VERSION ""

NS_ :

BS_:

BU_: PowertrainControlModule AtmosphericSensor SafetyRestraintSystem2 Aftertreatment_2_GasOutlet Aftertreatment_2_GasIntake DieselParticulateFilterControl Turbocharger SafetyRestraintSystem1 CabDisplay2 Aftertreatment_1_GasOutlet Aftertreatment_1_GasIntake OnBoardDataLogger OffBoardDiagnosticTool2 OffBoardDiagnosticTool1 FileServer ParkingBrakeController SeatController2 FanDriveController SteeringColumnUnit CommunicationUnitRadio CommunicationUnitSatellite CommunicationUnitCellular PropulsionBatteryCharger ChassisController2 ChassisController1 EngineValveControl AuxiliaryHeater2 AuxiliaryHeater1 ClutchUnit RampControl InformationSystem1 SuspensionSystemController2 OilSensor VehicleDynamicStability ExhaustEmissionController TransmissionDisplay2 TransmissionDisplay1 ClimateControl2 WaterPumpController RearAxleSteeringController LightingOperatorControl SeatController1 IgnitionController2 IgnitionController1 TirePressureController CabController2 CabController1 PneumaticSystemController SuspensionSystemController1 HydraulicPumpController EnduranceBrakingSystem RetarderExhaustEngine2 OnBoardDiagnosticUnit HeadwayController RetarderExhaustEngine1 CabDisplay1 ManagementComputer VirtualTerminal OffVehicleGateway PowerTakeOffFront HitchControl AuxiliaryValveControl BodyController TractorTrailerBridge1 StarterSystem ElectricalSystem VehicleSecurity VehicleNavigation AerodynamicControl ElectricalChargingSystem ClimateControl1 TripRecorder InstrumentCluster SuspensionDriveAxle2 SuspensionDriveAxle1 SuspensionSteerAxle SteeringController FuelSystem CruiseControl RetarderDriveline RetarderEngine BrakesDriveAxle2 BrakesDriveAxle1 BrakesSystemController BrakesSteerAxle AxleDrive2 AxleDrive1 AxleSteering PowerTakeOff ShiftConsoleSecondary ShiftConsolePrimary Transmission2 Transmission1 Engine2 Engine1

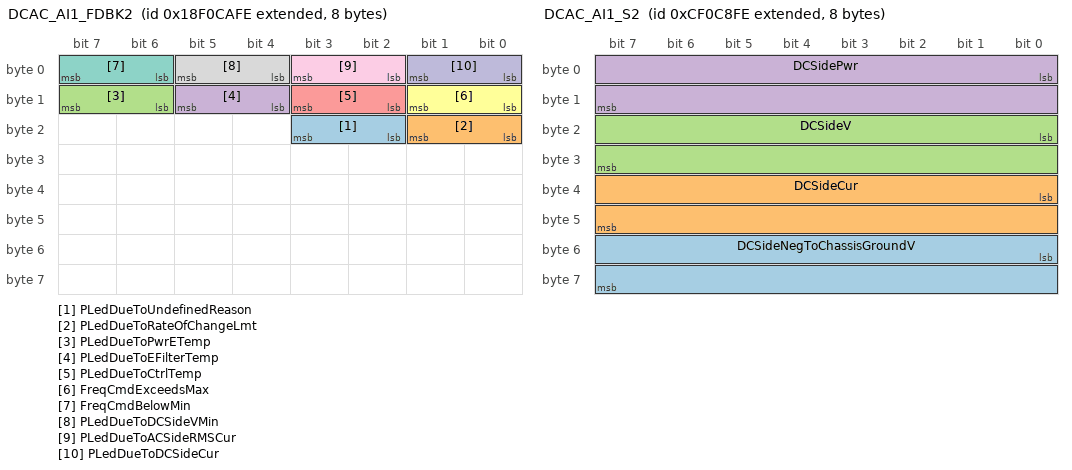
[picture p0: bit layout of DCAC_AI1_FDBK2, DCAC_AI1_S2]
BO_ 2565917438 DCAC_AI1_FDBK2: 8 Vector__XXX
 SG_ PLedDueToUndefinedReason : 18|2@1+ (1,0) [0|3] "" Vector__XXX
 SG_ PLedDueToRateOfChangeLmt : 16|2@1+ (1,0) [0|3] "" Vector__XXX
 SG_ PLedDueToPwrETemp : 14|2@1+ (1,0) [0|3] "" Vector__XXX
 SG_ PLedDueToEFilterTemp : 12|2@1+ (1,0) [0|3] "" Vector__XXX
 SG_ PLedDueToCtrlTemp : 10|2@1+ (1,0) [0|3] "" Vector__XXX
 SG_ FreqCmdExceedsMax : 8|2@1+ (1,0) [0|3] "" Vector__XXX
 SG_ FreqCmdBelowMin : 6|2@1+ (1,0) [0|3] "" Vector__XXX
 SG_ PLedDueToDCSideVMin : 4|2@1+ (1,0) [0|3] "" Vector__XXX
 SG_ PLedDueToACSideRMSCur : 2|2@1+ (1,0) [0|3] "" Vector__XXX
 SG_ PLedDueToDCSideCur : 0|2@1+ (1,0) [0|3] "" Vector__XXX

BO_ 2364590590 DCAC_AI1_V: 8 Vector__XXX
 SG_ SLIV : 16|16@1+ (0.05,0) [0|3212.75] "V" Vector__XXX
 SG_ IgntV : 0|16@1+ (0.05,0) [0|3212.75] "V" Vector__XXX

BO_ 2364590334 DCAC_AI1_S2: 8 Vector__XXX
 SG_ DCSideNegToChassisGroundV : 48|16@1+ (0.05,0) [0|3212.75] "V" Vector__XXX
 SG_ DCSideCur : 32|16@1+ (0.0625,0) [0|4015.9375] "A" Vector__XXX
 SG_ DCSideV : 16|16@1+ (0.05,0) [0|3212.75] "V" Vector__XXX
 SG_ DCSidePwr : 0|16@1+ (0.0625,0) [0|4015.9375] "kW" Vector__XXX

BO_ 2624519934 CRSC: 8 Vector__XXX
 SG_ CommandedReceiveSPNSA : 40|8@1+ (1,0) [0|255] "" Vector__XXX
 SG_ CommandedReceiveSPNReqSt : 32|2@1+ (1,0) [0|3] "" Vector__XXX
 SG_ CommandedReceiveSPN : 16|19@1+ (1,0) [0|524287] "" Vector__XXX
 SG_ TransactionMode : 4|4@1+ (1,0) [0|15] "" Vector__XXX
 SG_ CommandedPort : 0|4@1+ (1,0) [0|15] "" Vector__XXX

BO_ 2557345534 WSPT1: 19 Vector__XXX
 SG_ PlungerFiringOrder : 144|4@1+ (1,0) [0|15] "" Vector__XXX
 SG_ RodLoadHiThreshold : 128|16@1+ (5,0) [0|321275] "kN" Vector__XXX
 SG_ CrankshaftSpdHiThreshold : 112|16@1+ (0.125,0) [0|8031.875] "rpm" Vector__XXX
 SG_ CrankshaftSpdLowThreshold : 96|16@1+ (0.125,0) [0|8031.875] "rpm" Vector__XXX
 SG_ DisPressHiThreshold : 80|16@1+ (5,0) [0|321275] "kPa" Vector__XXX
 SG_ SuctionPressHiThreshold : 64|16@1+ (0.1,-3212.7) [-3212.7|3212.8] "kPa" Vector__XXX
 SG_ SuctionPressLowThreshold : 48|16@1+ (0.1,-3212.7) [-3212.7|3212.8] "kPa" Vector__XXX
 SG_ GearBoxOilTempHiThreshold : 40|8@1+ (1,-40) [-40|210] "°C" Vector__XXX
 SG_ GearBoxOilTempLowThreshold : 32|8@1+ (1,-40) [-40|210] "°C" Vector__XXX
 SG_ GearBoxOilPressHiThreshold : 16|16@1+ (0.1,0) [0|6425.5] "kPa" Vector__XXX
 SG_ GearBoxOilPressLowThreshold : 0|16@1+ (0.1,0) [0|6425.5] "kPa" Vector__XXX

BO_ 2557214462 WSPSCC: 8 Vector__XXX
 SG_ DisPressCalSetPointCmd : 8|4@1+ (1,0) [0|15] "" Vector__XXX
 SG_ SuctionPressCalSetPointCmd : 0|4@1+ (1,0) [0|15] "" Vector__XXX

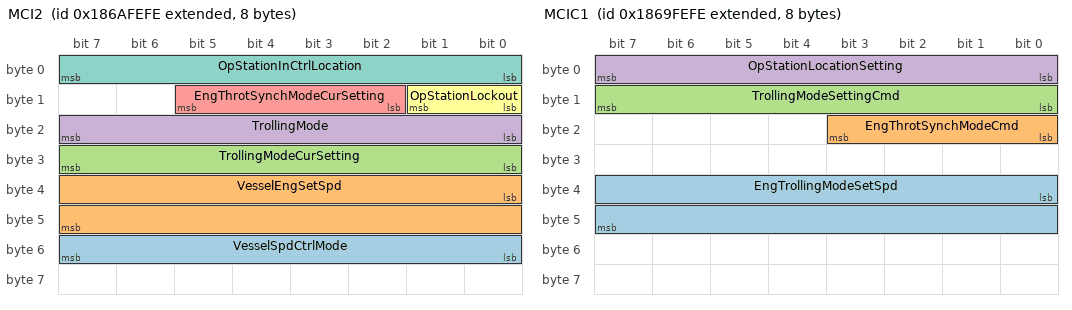
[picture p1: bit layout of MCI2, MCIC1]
BO_ 2557148926 MCI2: 8 Vector__XXX
 SG_ VesselSpdCtrlMode : 48|8@1+ (1,0) [0|255] "" Vector__XXX
 SG_ VesselEngSetSpd : 32|16@1+ (0.125,0) [0|8031.875] "rpm" Vector__XXX
 SG_ TrollingModeCurSetting : 24|8@1+ (1,0) [0|255] "" Vector__XXX
 SG_ TrollingMode : 16|8@1+ (1,0) [0|255] "" Vector__XXX
 SG_ EngThrotSynchModeCurSetting : 10|4@1+ (1,0) [0|15] "" Vector__XXX
 SG_ OpStationLockout : 8|2@1+ (1,0) [0|3] "" Vector__XXX
 SG_ OpStationInCtrlLocation : 0|8@1+ (1,0) [0|250] "ID" Vector__XXX

BO_ 2557083390 MCIC1: 8 Vector__XXX
 SG_ EngTrollingModeSetSpd : 32|16@1+ (0.125,0) [0|8031.875] "rpm" Vector__XXX
 SG_ EngThrotSynchModeCmd : 16|4@1+ (1,0) [0|15] "" Vector__XXX
 SG_ TrollingModeSettingCmd : 8|8@1+ (1,0) [0|255] "" Vector__XXX
 SG_ OpStationLocationSetting : 0|8@1+ (1,0) [0|250] "ID" Vector__XXX

BO_ 2633785086 HVESSHIST: 19 Vector__XXX
 SG_ TotalEnergyOut : 120|32@1+ (1,0) [0|4211081215] "kWh" Vector__XXX
 SG_ TotalEnergyInput : 88|32@1+ (1,0) [0|4211081215] "kWh" Vector__XXX
 SG_ TotalAccumulatedCharge : 56|32@1+ (100,0) [0|421108121500] "Ah" Vector__XXX
 SG_ TotalEnergyThroughput : 24|32@1+ (100,0) [0|421108121500] "Wh" Vector__XXX
 SG_ ContactorOpenUnderLoadCount : 8|16@1+ (1,0) [0|64255] "" Vector__XXX
 SG_ StOfHealth : 0|8@1+ (0.4,0) [0|100] "%" Vector__XXX

BO_ 2566675966 HVESSCFG: 20 Vector__XXX
 SG_ NomRatedCapacity : 136|24@1+ (0.001,0) [0|16449.535] "kWh" Vector__XXX
 SG_ NumOfHVESPsConfigured : 128|8@1+ (1,0) [0|250] "" Vector__XXX
 SG_ CellMinVLmt : 120|8@1+ (0.02044,0) [0|5.11] "V" Vector__XXX
 SG_ CellMaxVLmt : 112|8@1+ (0.02044,0) [0|5.11] "V" Vector__XXX
 SG_ RecommendedMinOperatingTemp : 96|16@1+ (0.03125,-273) [-273|1734.96875] "°C" Vector__XXX
 SG_ RecommendedMaxOperatingTemp : 80|16@1+ (0.03125,-273) [-273|1734.96875] "°C" Vector__XXX
 SG_ RecommendedMaxStOfCharge : 64|16@1+ (0.0015625,0) [0|100.3984375] "%" Vector__XXX
 SG_ RecommendedMinStOfCharge : 48|16@1+ (0.0015625,0) [0|100.3984375] "%" Vector__XXX
 SG_ RecommendedMaxOperatingV : 32|16@1+ (0.05,0) [0|3212.75] "V" Vector__XXX
 SG_ RecommendedMinOperatingV : 16|16@1+ (0.05,0) [0|3212.75] "V" Vector__XXX
 SG_ NominalV : 0|16@1+ (0.05,0) [0|3212.75] "V" Vector__XXX

BO_ 2566661886 A2DEFI2: 8 Vector__XXX
 SG_ Ctrl2Temp : 8|8@1+ (1,-40) [-40|210] "°C" Vector__XXX
 SG_ CtrlTemp : 0|8@1+ (1,-40) [-40|210] "°C" Vector__XXX

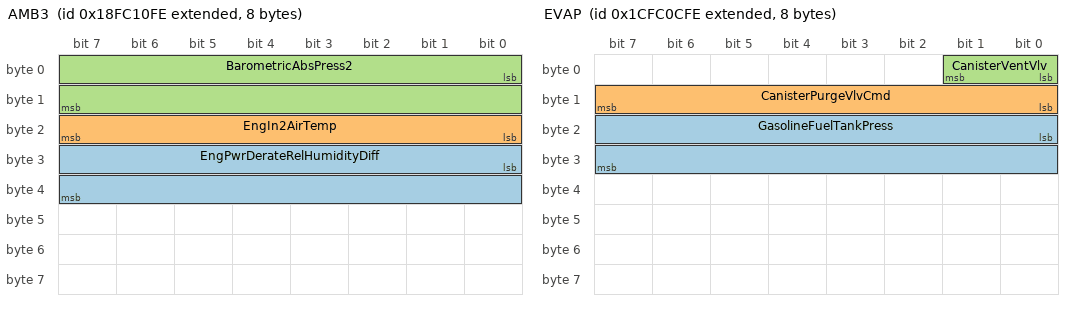
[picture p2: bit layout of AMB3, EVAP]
BO_ 2566656254 AMB3: 8 Vector__XXX
 SG_ EngPwrDerateRelHumidityDiff : 24|16@1+ (0.01,-321.27) [-100|100] "%" Vector__XXX
 SG_ EngIn2AirTemp : 16|8@1+ (1,-40) [-40|210] "°C" Vector__XXX
 SG_ BarometricAbsPress2 : 0|16@1+ (0.1,0) [0|6425.5] "kPa" Vector__XXX

BO_ 2566655998 SHRPS: 8 Vector__XXX
 SG_ PitchSensitivity : 8|8@1+ (0.4,0) [0|100] "%" Vector__XXX
 SG_ Sensitivity : 0|8@1+ (0.4,0) [0|100] "%" Vector__XXX

BO_ 2566655742 PHRPS: 8 Vector__XXX
 SG_ PitchSensitivity : 8|8@1+ (0.4,0) [0|100] "%" Vector__XXX
 SG_ Sensitivity : 0|8@1+ (0.4,0) [0|100] "%" Vector__XXX

BO_ 2633764350 FPS1: 8 Vector__XXX
 SG_ EngagementCycles : 32|16@1+ (1,0) [0|64255] "" Vector__XXX
 SG_ OpTime : 0|32@1+ (1,0) [0|4211081215] "s" Vector__XXX

BO_ 2633764094 EVAP: 8 Vector__XXX
 SG_ GasolineFuelTankPress : 16|16@1+ (0.1,-3212.7) [-3212.7|3212.8] "kPa" Vector__XXX
 SG_ CanisterPurgeVlvCmd : 8|8@1+ (0.4,0) [0|100] "%" Vector__XXX
 SG_ CanisterVentVlv : 0|2@1+ (1,0) [0|3] "" Vector__XXX

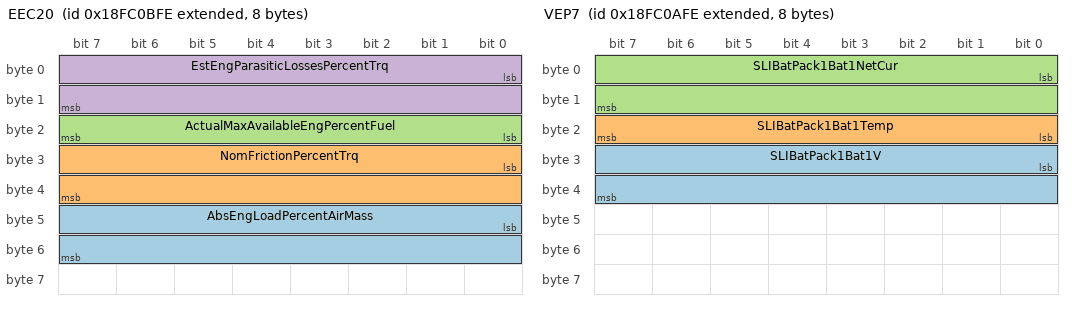
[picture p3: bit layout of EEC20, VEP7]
BO_ 2566654974 EEC20: 8 Vector__XXX
 SG_ AbsEngLoadPercentAirMass : 40|16@1+ (0.025,0) [0|1606.375] "%" Vector__XXX
 SG_ NomFrictionPercentTrq : 24|16@1+ (0.0015625,0) [0|100.3984375] "%" Vector__XXX
 SG_ ActualMaxAvailableEngPercentFuel : 16|8@1+ (0.4,0) [0|100] "%" Vector__XXX
 SG_ EstEngParasiticLossesPercentTrq : 0|16@1+ (0.0015625,0) [0|100.3984375] "%" Vector__XXX

BO_ 2566654718 VEP7: 8 Vector__XXX
 SG_ SLIBatPack1Bat1V : 24|16@1+ (0.05,0) [0|3212.75] "V" Vector__XXX
 SG_ SLIBatPack1Bat1Temp : 16|8@1+ (1,-40) [-40|210] "°C" Vector__XXX
 SG_ SLIBatPack1Bat1NetCur : 0|16@1+ (0.05,-1600) [-1600|1612.75] "A" Vector__XXX

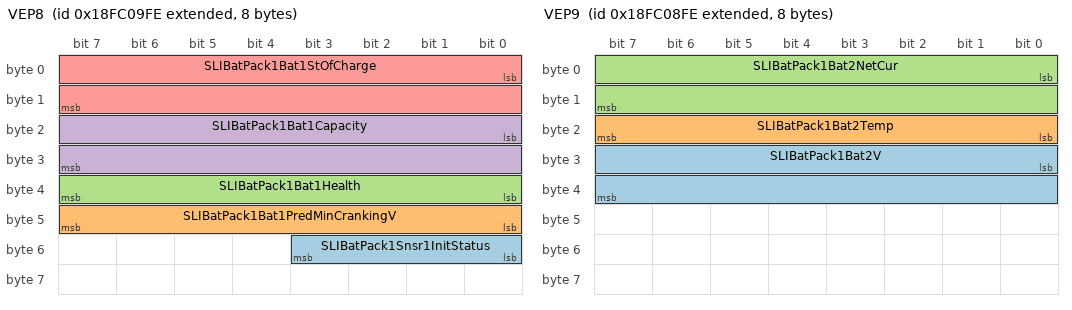
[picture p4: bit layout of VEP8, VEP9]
BO_ 2566654462 VEP8: 8 Vector__XXX
 SG_ SLIBatPack1Snsr1InitStatus : 48|4@1+ (1,0) [0|15] "" Vector__XXX
 SG_ SLIBatPack1Bat1PredMinCrankingV : 40|8@1+ (0.2,0) [0|50] "V" Vector__XXX
 SG_ SLIBatPack1Bat1Health : 32|8@1+ (0.5,0) [0|125] "%" Vector__XXX
 SG_ SLIBatPack1Bat1Capacity : 16|16@1+ (1,0) [0|64255] "Ah" Vector__XXX
 SG_ SLIBatPack1Bat1StOfCharge : 0|16@1+ (0.0025,0) [0|160.6375] "%" Vector__XXX

BO_ 2566654206 VEP9: 8 Vector__XXX
 SG_ SLIBatPack1Bat2V : 24|16@1+ (0.05,0) [0|3212.75] "V" Vector__XXX
 SG_ SLIBatPack1Bat2Temp : 16|8@1+ (1,-40) [-40|210] "°C" Vector__XXX
 SG_ SLIBatPack1Bat2NetCur : 0|16@1+ (0.05,-1600) [-1600|1612.75] "A" Vector__XXX

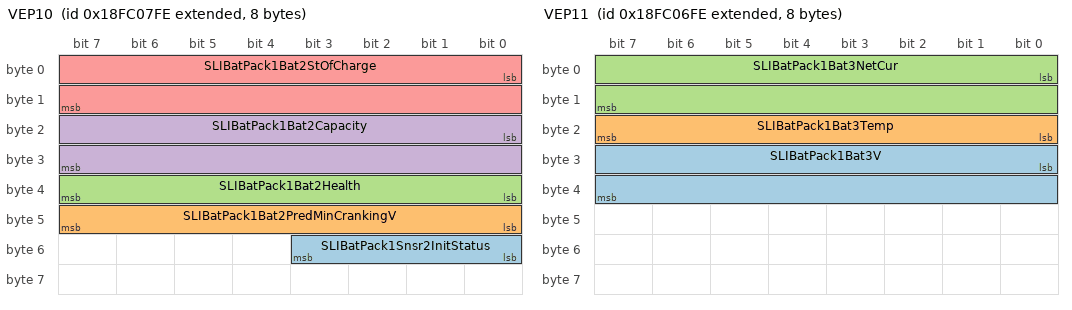
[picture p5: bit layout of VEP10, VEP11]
BO_ 2566653950 VEP10: 8 Vector__XXX
 SG_ SLIBatPack1Snsr2InitStatus : 48|4@1+ (1,0) [0|15] "" Vector__XXX
 SG_ SLIBatPack1Bat2PredMinCrankingV : 40|8@1+ (0.2,0) [0|50] "V" Vector__XXX
 SG_ SLIBatPack1Bat2Health : 32|8@1+ (0.5,0) [0|125] "%" Vector__XXX
 SG_ SLIBatPack1Bat2Capacity : 16|16@1+ (1,0) [0|64255] "Ah" Vector__XXX
 SG_ SLIBatPack1Bat2StOfCharge : 0|16@1+ (0.0025,0) [0|160.6375] "%" Vector__XXX

BO_ 2566653694 VEP11: 8 Vector__XXX
 SG_ SLIBatPack1Bat3V : 24|16@1+ (0.05,0) [0|3212.75] "V" Vector__XXX
 SG_ SLIBatPack1Bat3Temp : 16|8@1+ (1,-40) [-40|210] "°C" Vector__XXX
 SG_ SLIBatPack1Bat3NetCur : 0|16@1+ (0.05,-1600) [-1600|1612.75] "A" Vector__XXX

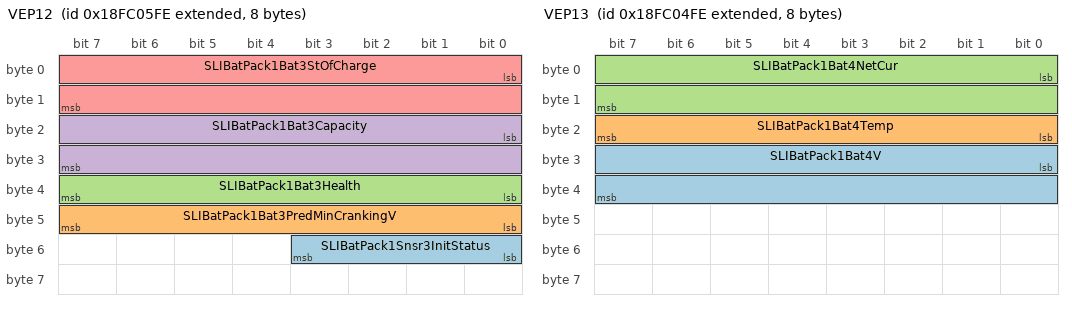
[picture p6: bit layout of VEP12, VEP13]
BO_ 2566653438 VEP12: 8 Vector__XXX
 SG_ SLIBatPack1Snsr3InitStatus : 48|4@1+ (1,0) [0|15] "" Vector__XXX
 SG_ SLIBatPack1Bat3PredMinCrankingV : 40|8@1+ (0.2,0) [0|50] "V" Vector__XXX
 SG_ SLIBatPack1Bat3Health : 32|8@1+ (0.5,0) [0|125] "%" Vector__XXX
 SG_ SLIBatPack1Bat3Capacity : 16|16@1+ (1,0) [0|64255] "Ah" Vector__XXX
 SG_ SLIBatPack1Bat3StOfCharge : 0|16@1+ (0.0025,0) [0|160.6375] "%" Vector__XXX

BO_ 2566653182 VEP13: 8 Vector__XXX
 SG_ SLIBatPack1Bat4V : 24|16@1+ (0.05,0) [0|3212.75] "V" Vector__XXX
 SG_ SLIBatPack1Bat4Temp : 16|8@1+ (1,-40) [-40|210] "°C" Vector__XXX
 SG_ SLIBatPack1Bat4NetCur : 0|16@1+ (0.05,-1600) [-1600|1612.75] "A" Vector__XXX

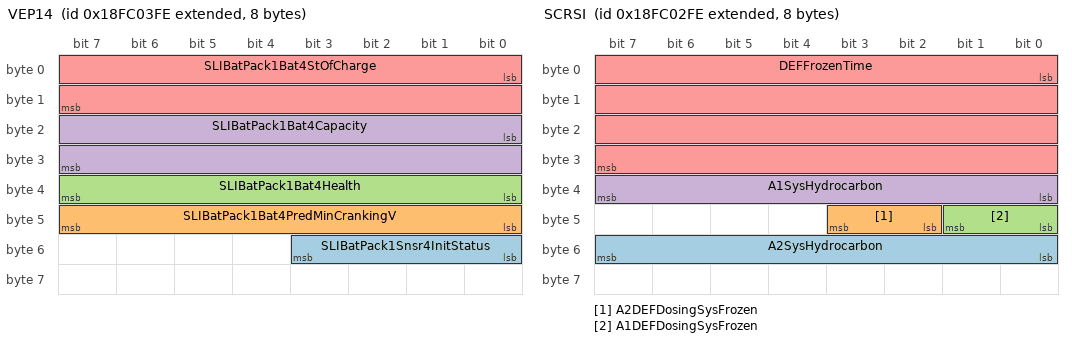
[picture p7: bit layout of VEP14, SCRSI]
BO_ 2566652926 VEP14: 8 Vector__XXX
 SG_ SLIBatPack1Snsr4InitStatus : 48|4@1+ (1,0) [0|15] "" Vector__XXX
 SG_ SLIBatPack1Bat4PredMinCrankingV : 40|8@1+ (0.2,0) [0|50] "V" Vector__XXX
 SG_ SLIBatPack1Bat4Health : 32|8@1+ (0.5,0) [0|125] "%" Vector__XXX
 SG_ SLIBatPack1Bat4Capacity : 16|16@1+ (1,0) [0|64255] "Ah" Vector__XXX
 SG_ SLIBatPack1Bat4StOfCharge : 0|16@1+ (0.0025,0) [0|160.6375] "%" Vector__XXX

BO_ 2566652670 SCRSI: 8 Vector__XXX
 SG_ A2SysHydrocarbon : 48|8@1+ (1,0) [0|250] "%" Vector__XXX
 SG_ A2DEFDosingSysFrozen : 42|2@1+ (1,0) [0|3] "" Vector__XXX
 SG_ A1DEFDosingSysFrozen : 40|2@1+ (1,0) [0|3] "" Vector__XXX
 SG_ A1SysHydrocarbon : 32|8@1+ (1,0) [0|250] "%" Vector__XXX
 SG_ DEFFrozenTime : 0|32@1+ (1,0) [0|4211081215] "s" Vector__XXX

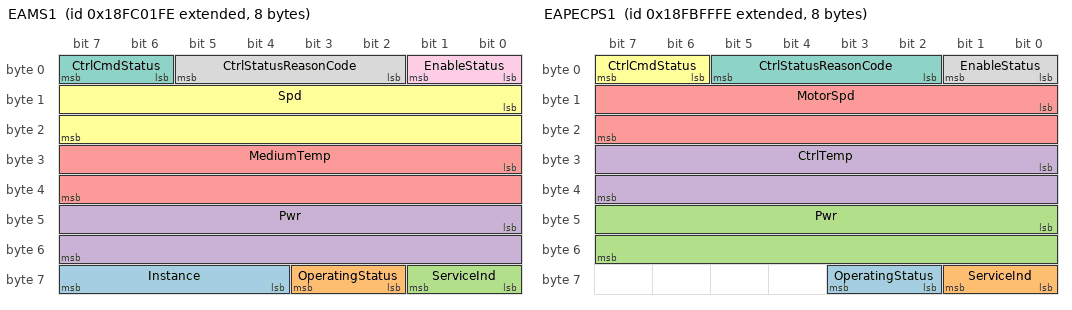
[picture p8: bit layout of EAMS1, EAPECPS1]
BO_ 2566652414 EAMS1: 8 Vector__XXX
 SG_ Instance : 60|4@1+ (1,0) [0|15] "" Vector__XXX
 SG_ OperatingStatus : 58|2@1+ (1,0) [0|3] "" Vector__XXX
 SG_ ServiceInd : 56|2@1+ (1,0) [0|3] "" Vector__XXX
 SG_ Pwr : 40|16@1+ (0.5,0) [0|32127.5] "W" Vector__XXX
 SG_ MediumTemp : 24|16@1+ (0.03125,-273) [-273|1734.96875] "°C" Vector__XXX
 SG_ Spd : 8|16@1+ (0.5,0) [0|32127.5] "rpm" Vector__XXX
 SG_ CtrlCmdStatus : 6|2@1+ (1,0) [0|3] "" Vector__XXX
 SG_ CtrlStatusReasonCode : 2|4@1+ (1,0) [0|15] "" Vector__XXX
 SG_ EnableStatus : 0|2@1+ (1,0) [0|3] "" Vector__XXX

BO_ 2566651902 EAPECPS1: 8 Vector__XXX
 SG_ OperatingStatus : 58|2@1+ (1,0) [0|3] "" Vector__XXX
 SG_ ServiceInd : 56|2@1+ (1,0) [0|3] "" Vector__XXX
 SG_ Pwr : 40|16@1+ (0.5,0) [0|32127.5] "W" Vector__XXX
 SG_ CtrlTemp : 24|16@1+ (0.03125,-273) [-273|1734.96875] "°C" Vector__XXX
 SG_ MotorSpd : 8|16@1+ (0.5,0) [0|32127.5] "rpm" Vector__XXX
 SG_ CtrlCmdStatus : 6|2@1+ (1,0) [0|3] "" Vector__XXX
 SG_ CtrlStatusReasonCode : 2|4@1+ (1,0) [0|15] "" Vector__XXX
 SG_ EnableStatus : 0|2@1+ (1,0) [0|3] "" Vector__XXX

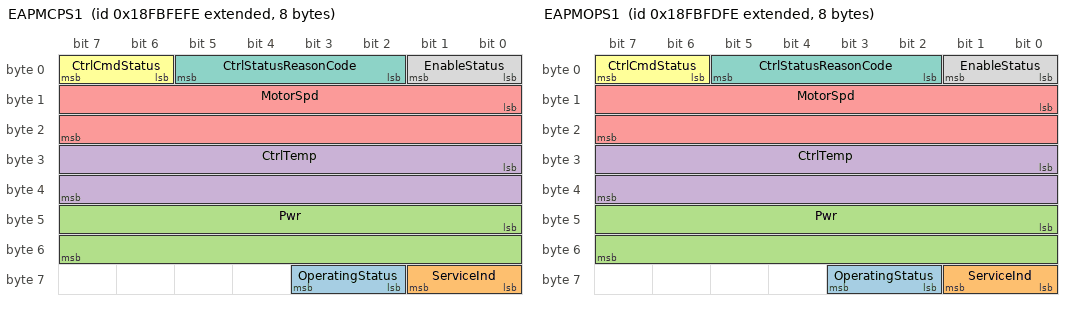
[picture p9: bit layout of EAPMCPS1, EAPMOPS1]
BO_ 2566651646 EAPMCPS1: 8 Vector__XXX
 SG_ OperatingStatus : 58|2@1+ (1,0) [0|3] "" Vector__XXX
 SG_ ServiceInd : 56|2@1+ (1,0) [0|3] "" Vector__XXX
 SG_ Pwr : 40|16@1+ (0.5,0) [0|32127.5] "W" Vector__XXX
 SG_ CtrlTemp : 24|16@1+ (0.03125,-273) [-273|1734.96875] "°C" Vector__XXX
 SG_ MotorSpd : 8|16@1+ (0.5,0) [0|32127.5] "rpm" Vector__XXX
 SG_ CtrlCmdStatus : 6|2@1+ (1,0) [0|3] "" Vector__XXX
 SG_ CtrlStatusReasonCode : 2|4@1+ (1,0) [0|15] "" Vector__XXX
 SG_ EnableStatus : 0|2@1+ (1,0) [0|3] "" Vector__XXX

BO_ 2566651390 EAPMOPS1: 8 Vector__XXX
 SG_ OperatingStatus : 58|2@1+ (1,0) [0|3] "" Vector__XXX
 SG_ ServiceInd : 56|2@1+ (1,0) [0|3] "" Vector__XXX
 SG_ Pwr : 40|16@1+ (0.5,0) [0|32127.5] "W" Vector__XXX
 SG_ CtrlTemp : 24|16@1+ (0.03125,-273) [-273|1734.96875] "°C" Vector__XXX
 SG_ MotorSpd : 8|16@1+ (0.5,0) [0|32127.5] "rpm" Vector__XXX
 SG_ CtrlCmdStatus : 6|2@1+ (1,0) [0|3] "" Vector__XXX
 SG_ CtrlStatusReasonCode : 2|4@1+ (1,0) [0|15] "" Vector__XXX
 SG_ EnableStatus : 0|2@1+ (1,0) [0|3] "" Vector__XXX

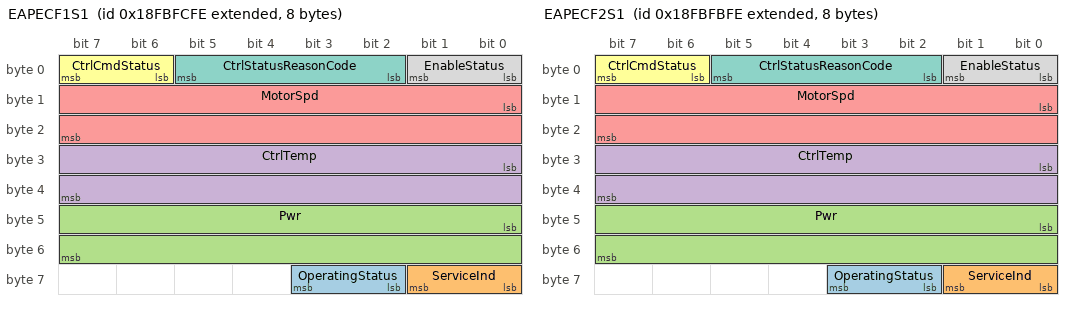
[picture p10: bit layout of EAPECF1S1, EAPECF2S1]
BO_ 2566651134 EAPECF1S1: 8 Vector__XXX
 SG_ OperatingStatus : 58|2@1+ (1,0) [0|3] "" Vector__XXX
 SG_ ServiceInd : 56|2@1+ (1,0) [0|3] "" Vector__XXX
 SG_ Pwr : 40|16@1+ (0.5,0) [0|32127.5] "W" Vector__XXX
 SG_ CtrlTemp : 24|16@1+ (0.03125,-273) [-273|1734.96875] "°C" Vector__XXX
 SG_ MotorSpd : 8|16@1+ (0.5,0) [0|32127.5] "rpm" Vector__XXX
 SG_ CtrlCmdStatus : 6|2@1+ (1,0) [0|3] "" Vector__XXX
 SG_ CtrlStatusReasonCode : 2|4@1+ (1,0) [0|15] "" Vector__XXX
 SG_ EnableStatus : 0|2@1+ (1,0) [0|3] "" Vector__XXX

BO_ 2566650878 EAPECF2S1: 8 Vector__XXX
 SG_ OperatingStatus : 58|2@1+ (1,0) [0|3] "" Vector__XXX
 SG_ ServiceInd : 56|2@1+ (1,0) [0|3] "" Vector__XXX
 SG_ Pwr : 40|16@1+ (0.5,0) [0|32127.5] "W" Vector__XXX
 SG_ CtrlTemp : 24|16@1+ (0.03125,-273) [-273|1734.96875] "°C" Vector__XXX
 SG_ MotorSpd : 8|16@1+ (0.5,0) [0|32127.5] "rpm" Vector__XXX
 SG_ CtrlCmdStatus : 6|2@1+ (1,0) [0|3] "" Vector__XXX
 SG_ CtrlStatusReasonCode : 2|4@1+ (1,0) [0|15] "" Vector__XXX
 SG_ EnableStatus : 0|2@1+ (1,0) [0|3] "" Vector__XXX

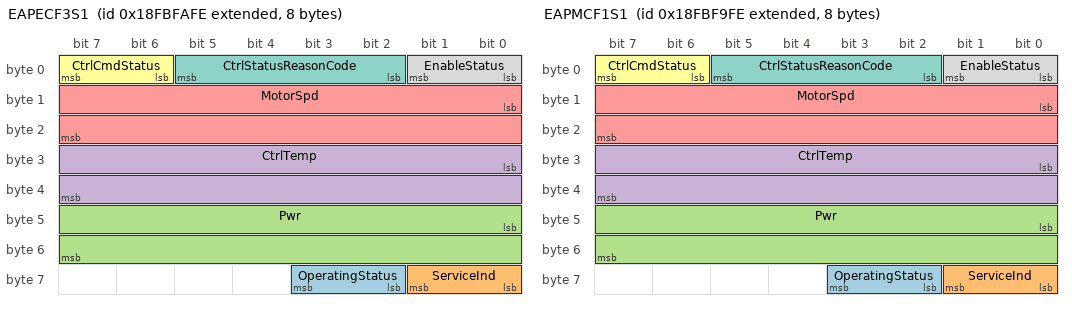
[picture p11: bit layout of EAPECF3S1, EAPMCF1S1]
BO_ 2566650622 EAPECF3S1: 8 Vector__XXX
 SG_ OperatingStatus : 58|2@1+ (1,0) [0|3] "" Vector__XXX
 SG_ ServiceInd : 56|2@1+ (1,0) [0|3] "" Vector__XXX
 SG_ Pwr : 40|16@1+ (0.5,0) [0|32127.5] "W" Vector__XXX
 SG_ CtrlTemp : 24|16@1+ (0.03125,-273) [-273|1734.96875] "°C" Vector__XXX
 SG_ MotorSpd : 8|16@1+ (0.5,0) [0|32127.5] "rpm" Vector__XXX
 SG_ CtrlCmdStatus : 6|2@1+ (1,0) [0|3] "" Vector__XXX
 SG_ CtrlStatusReasonCode : 2|4@1+ (1,0) [0|15] "" Vector__XXX
 SG_ EnableStatus : 0|2@1+ (1,0) [0|3] "" Vector__XXX

BO_ 2566650366 EAPMCF1S1: 8 Vector__XXX
 SG_ OperatingStatus : 58|2@1+ (1,0) [0|3] "" Vector__XXX
 SG_ ServiceInd : 56|2@1+ (1,0) [0|3] "" Vector__XXX
 SG_ Pwr : 40|16@1+ (0.5,0) [0|32127.5] "W" Vector__XXX
 SG_ CtrlTemp : 24|16@1+ (0.03125,-273) [-273|1734.96875] "°C" Vector__XXX
 SG_ MotorSpd : 8|16@1+ (0.5,0) [0|32127.5] "rpm" Vector__XXX
 SG_ CtrlCmdStatus : 6|2@1+ (1,0) [0|3] "" Vector__XXX
 SG_ CtrlStatusReasonCode : 2|4@1+ (1,0) [0|15] "" Vector__XXX
 SG_ EnableStatus : 0|2@1+ (1,0) [0|3] "" Vector__XXX

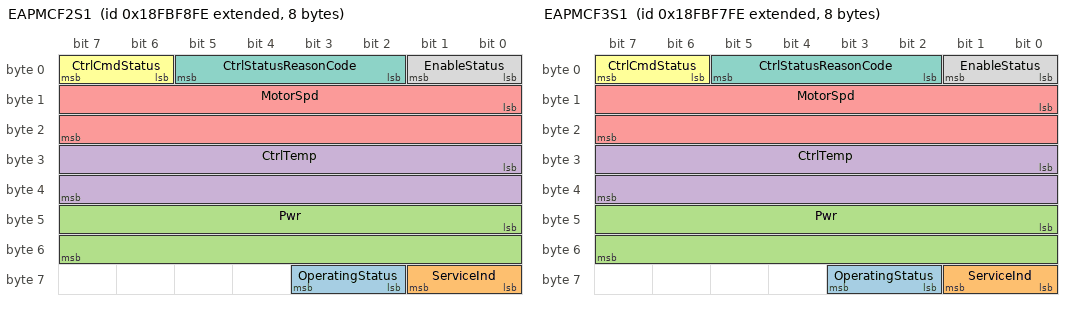
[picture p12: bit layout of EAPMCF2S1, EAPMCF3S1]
BO_ 2566650110 EAPMCF2S1: 8 Vector__XXX
 SG_ OperatingStatus : 58|2@1+ (1,0) [0|3] "" Vector__XXX
 SG_ ServiceInd : 56|2@1+ (1,0) [0|3] "" Vector__XXX
 SG_ Pwr : 40|16@1+ (0.5,0) [0|32127.5] "W" Vector__XXX
 SG_ CtrlTemp : 24|16@1+ (0.03125,-273) [-273|1734.96875] "°C" Vector__XXX
 SG_ MotorSpd : 8|16@1+ (0.5,0) [0|32127.5] "rpm" Vector__XXX
 SG_ CtrlCmdStatus : 6|2@1+ (1,0) [0|3] "" Vector__XXX
 SG_ CtrlStatusReasonCode : 2|4@1+ (1,0) [0|15] "" Vector__XXX
 SG_ EnableStatus : 0|2@1+ (1,0) [0|3] "" Vector__XXX

BO_ 2566649854 EAPMCF3S1: 8 Vector__XXX
 SG_ OperatingStatus : 58|2@1+ (1,0) [0|3] "" Vector__XXX
 SG_ ServiceInd : 56|2@1+ (1,0) [0|3] "" Vector__XXX
 SG_ Pwr : 40|16@1+ (0.5,0) [0|32127.5] "W" Vector__XXX
 SG_ CtrlTemp : 24|16@1+ (0.03125,-273) [-273|1734.96875] "°C" Vector__XXX
 SG_ MotorSpd : 8|16@1+ (0.5,0) [0|32127.5] "rpm" Vector__XXX
 SG_ CtrlCmdStatus : 6|2@1+ (1,0) [0|3] "" Vector__XXX
 SG_ CtrlStatusReasonCode : 2|4@1+ (1,0) [0|15] "" Vector__XXX
 SG_ EnableStatus : 0|2@1+ (1,0) [0|3] "" Vector__XXX

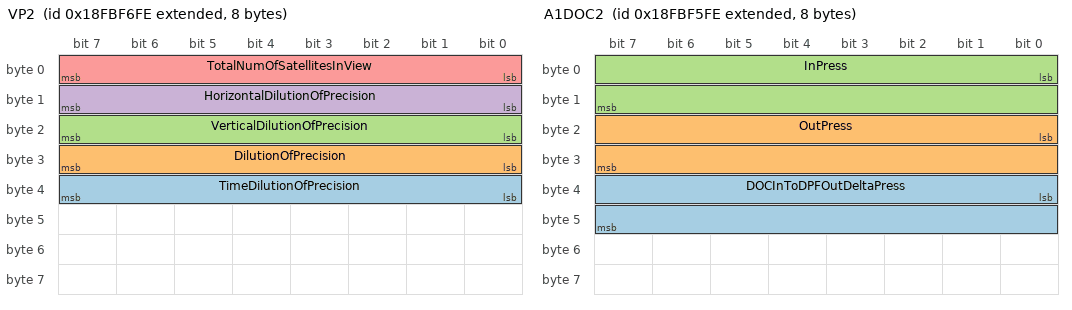
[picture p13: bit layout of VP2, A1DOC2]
BO_ 2566649598 VP2: 8 Vector__XXX
 SG_ TimeDilutionOfPrecision : 32|8@1+ (0.1,0) [0|25] "" Vector__XXX
 SG_ DilutionOfPrecision : 24|8@1+ (0.1,0) [0|25] "" Vector__XXX
 SG_ VerticalDilutionOfPrecision : 16|8@1+ (0.1,0) [0|25] "" Vector__XXX
 SG_ HorizontalDilutionOfPrecision : 8|8@1+ (0.1,0) [0|25] "" Vector__XXX
 SG_ TotalNumOfSatellitesInView : 0|8@1+ (1,0) [0|250] "" Vector__XXX

BO_ 2566649342 A1DOC2: 8 Vector__XXX
 SG_ DOCInToDPFOutDeltaPress : 32|16@1+ (0.1,0) [0|6425.5] "kPa" Vector__XXX
 SG_ OutPress : 16|16@1+ (0.1,0) [0|6425.5] "kPa" Vector__XXX
 SG_ InPress : 0|16@1+ (0.1,0) [0|6425.5] "kPa" Vector__XXX

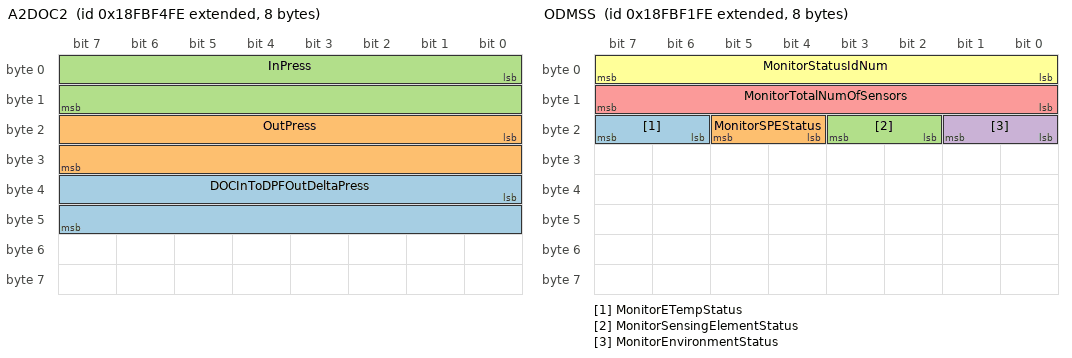
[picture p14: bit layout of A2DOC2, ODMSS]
BO_ 2566649086 A2DOC2: 8 Vector__XXX
 SG_ DOCInToDPFOutDeltaPress : 32|16@1+ (0.1,0) [0|6425.5] "kPa" Vector__XXX
 SG_ OutPress : 16|16@1+ (0.1,0) [0|6425.5] "kPa" Vector__XXX
 SG_ InPress : 0|16@1+ (0.1,0) [0|6425.5] "kPa" Vector__XXX

BO_ 2365322238 CCVS5: 8 Vector__XXX
 SG_ DirVS : 0|16@1+ (0.0078125,-250) [-250|251.9921875] "km/h" Vector__XXX

BO_ 2566648318 ODMSS: 8 Vector__XXX
 SG_ MonitorETempStatus : 22|2@1+ (1,0) [0|3] "" Vector__XXX
 SG_ MonitorSPEStatus : 20|2@1+ (1,0) [0|3] "" Vector__XXX
 SG_ MonitorSensingElementStatus : 18|2@1+ (1,0) [0|3] "" Vector__XXX
 SG_ MonitorEnvironmentStatus : 16|2@1+ (1,0) [0|3] "" Vector__XXX
 SG_ MonitorTotalNumOfSensors : 8|8@1+ (1,0) [0|250] "" Vector__XXX
 SG_ MonitorStatusIdNum : 0|8@1+ (1,0) [0|250] "" Vector__XXX

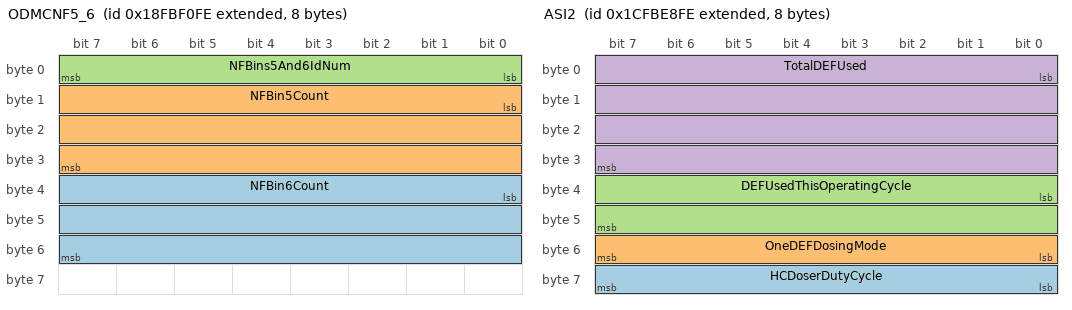
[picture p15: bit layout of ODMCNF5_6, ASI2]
BO_ 2566648062 ODMCNF5_6: 8 Vector__XXX
 SG_ NFBin6Count : 32|24@1+ (1,0) [0|16449535] "" Vector__XXX
 SG_ NFBin5Count : 8|24@1+ (1,0) [0|16449535] "" Vector__XXX
 SG_ NFBins5And6IdNum : 0|8@1+ (1,0) [0|250] "" Vector__XXX

BO_ 2566647806 ODMCNF3_4: 8 Vector__XXX
 SG_ NFBin4Count : 32|24@1+ (1,0) [0|16449535] "" Vector__XXX
 SG_ NFBin3Count : 8|24@1+ (1,0) [0|16449535] "" Vector__XXX
 SG_ NFBins3And4IdNum : 0|8@1+ (1,0) [0|250] "" Vector__XXX

BO_ 2566647550 ODMCNF1_2: 8 Vector__XXX
 SG_ NFBin2Count : 32|24@1+ (1,0) [0|16449535] "" Vector__XXX
 SG_ NFBin1Count : 8|24@1+ (1,0) [0|16449535] "" Vector__XXX
 SG_ NFBins1And2IdNum : 0|8@1+ (1,0) [0|250] "" Vector__XXX

BO_ 2566647294 ODMCF5_6: 8 Vector__XXX
 SG_ FBin6Count : 32|24@1+ (1,0) [0|16449535] "" Vector__XXX
 SG_ FBin5Count : 8|24@1+ (1,0) [0|16449535] "" Vector__XXX
 SG_ FBins5And6IdNum : 0|8@1+ (1,0) [0|250] "" Vector__XXX

BO_ 2566647038 ODMCF3_4: 8 Vector__XXX
 SG_ FBin4Count : 32|24@1+ (1,0) [0|16449535] "" Vector__XXX
 SG_ FBin3Count : 8|24@1+ (1,0) [0|16449535] "" Vector__XXX
 SG_ FBins3And4IdNum : 0|8@1+ (1,0) [0|250] "" Vector__XXX

BO_ 2566646782 ODMCF1_2: 8 Vector__XXX
 SG_ FBin2Count : 32|24@1+ (1,0) [0|16449535] "" Vector__XXX
 SG_ FBin1Count : 8|24@1+ (1,0) [0|16449535] "" Vector__XXX
 SG_ FBins1And2IdNum : 0|8@1+ (1,0) [0|250] "" Vector__XXX

BO_ 2633755390 E1NET1: 19 Vector__XXX
 SG_ MACAddressOctet6 : 144|8@1+ (1,0) [0|255] "" Vector__XXX
 SG_ MACAddressOctet5 : 136|8@1+ (1,0) [0|255] "" Vector__XXX
 SG_ MACAddressOctet4 : 128|8@1+ (1,0) [0|255] "" Vector__XXX
 SG_ MACAddressOctet3 : 120|8@1+ (1,0) [0|255] "" Vector__XXX
 SG_ MACAddressOctet2 : 112|8@1+ (1,0) [0|255] "" Vector__XXX
 SG_ MACAddressOctet1 : 104|8@1+ (1,0) [0|255] "" Vector__XXX
 SG_ DefaultGatewayOctet4 : 96|8@1+ (1,0) [0|255] "" Vector__XXX
 SG_ DefaultGatewayOctet3 : 88|8@1+ (1,0) [0|255] "" Vector__XXX
 SG_ DefaultGatewayOctet2 : 80|8@1+ (1,0) [0|255] "" Vector__XXX
 SG_ DefaultGatewayOctet1 : 72|8@1+ (1,0) [0|255] "" Vector__XXX
 SG_ SubnetMaskOctet4 : 64|8@1+ (1,0) [0|255] "" Vector__XXX
 SG_ SubnetMaskOctet3 : 56|8@1+ (1,0) [0|255] "" Vector__XXX
 SG_ SubnetMaskOctet2 : 48|8@1+ (1,0) [0|255] "" Vector__XXX
 SG_ SubnetMaskOctet1 : 40|8@1+ (1,0) [0|255] "" Vector__XXX
 SG_ IPv4AddressOctet4 : 32|8@1+ (1,0) [0|255] "" Vector__XXX
 SG_ IPv4AddressOctet3 : 24|8@1+ (1,0) [0|255] "" Vector__XXX
 SG_ IPv4AddressOctet2 : 16|8@1+ (1,0) [0|255] "" Vector__XXX
 SG_ IPv4AddressOctet1 : 8|8@1+ (1,0) [0|255] "" Vector__XXX
 SG_ LinkStatus : 4|2@1+ (1,0) [0|3] "" Vector__XXX
 SG_ DHCPStatus : 0|4@1+ (1,0) [0|15] "" Vector__XXX

BO_ 2633755134 E1NET2: 100 Vector__XXX
 SG_ HostName : 0|100@1+ (1,0) [0|255] "" Vector__XXX

BO_ 2633754878 ASI2: 8 Vector__XXX
 SG_ HCDoserDutyCycle : 56|8@1+ (0.4,0) [0|100] "%" Vector__XXX
 SG_ OneDEFDosingMode : 48|8@1+ (1,0) [0|250] "" Vector__XXX
 SG_ DEFUsedThisOperatingCycle : 32|16@1+ (0.1,0) [0|6425.5] "l" Vector__XXX
 SG_ TotalDEFUsed : 0|32@1+ (0.5,0) [0|2105540607.5] "l" Vector__XXX

BO_ 2633754622 SCROII5: 8 Vector__XXX
 SG_ EmergOvrdTotalActivationTime : 32|32@1+ (1,0) [0|4211081215] "s" Vector__XXX
 SG_ A1SCRInHiTempTime : 0|32@1+ (1,0) [0|4211081215] "s" Vector__XXX

BO_ 2365318910 HVESSFC: 8 Vector__XXX
 SG_ HVESFanInstance15 : 46|1@1+ (1,0) [0|1] "" Vector__XXX
 SG_ HVESFanInstance14 : 45|1@1+ (1,0) [0|1] "" Vector__XXX
 SG_ HVESFanInstance13 : 44|1@1+ (1,0) [0|1] "" Vector__XXX
 SG_ HVESFanInstance12 : 43|1@1+ (1,0) [0|1] "" Vector__XXX
 SG_ HVESFanInstance11 : 42|1@1+ (1,0) [0|1] "" Vector__XXX
 SG_ HVESFanInstance10 : 41|1@1+ (1,0) [0|1] "" Vector__XXX
 SG_ HVESFanInstance9 : 40|1@1+ (1,0) [0|1] "" Vector__XXX
 SG_ HVESFanInstance8 : 39|1@1+ (1,0) [0|1] "" Vector__XXX
 SG_ HVESFanInstance7 : 38|1@1+ (1,0) [0|1] "" Vector__XXX
 SG_ HVESFanInstance6 : 37|1@1+ (1,0) [0|1] "" Vector__XXX
 SG_ HVESFanInstance5 : 36|1@1+ (1,0) [0|1] "" Vector__XXX
 SG_ HVESFanInstance4 : 35|1@1+ (1,0) [0|1] "" Vector__XXX
 SG_ HVESFanInstance3 : 34|1@1+ (1,0) [0|1] "" Vector__XXX
 SG_ HVESFanInstance2 : 33|1@1+ (1,0) [0|1] "" Vector__XXX
 SG_ HVESFanInstance1 : 32|1@1+ (1,0) [0|1] "" Vector__XXX
 SG_ HVESFanPercentSpdCmd : 24|8@1+ (0.4,0) [0|100] "%" Vector__XXX
 SG_ HVESFanSpdCmd : 8|16@1+ (0.5,0) [0|32127.5] "rpm" Vector__XXX
 SG_ HVESFanPwrHold : 2|2@1+ (1,0) [0|3] "" Vector__XXX
 SG_ HVESFanEnableCmd : 0|2@1+ (1,0) [0|3] "" Vector__XXX

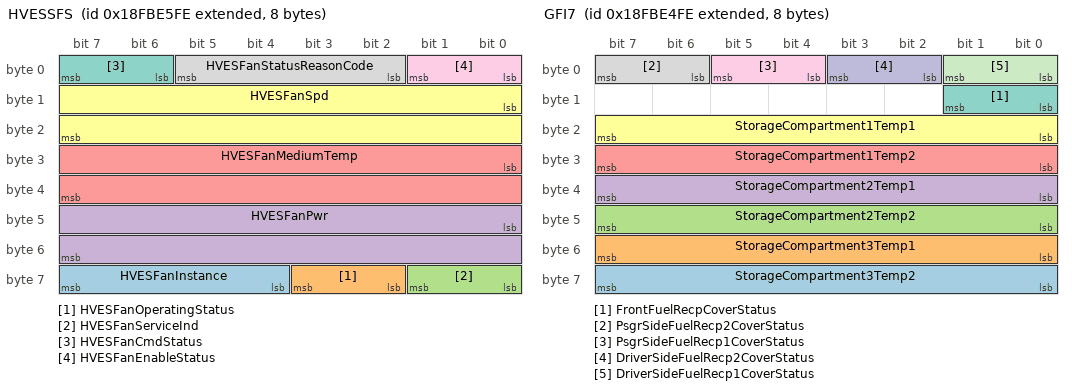
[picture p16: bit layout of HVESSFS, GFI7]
BO_ 2566645246 HVESSFS: 8 Vector__XXX
 SG_ HVESFanInstance : 60|4@1+ (1,0) [0|15] "" Vector__XXX
 SG_ HVESFanOperatingStatus : 58|2@1+ (1,0) [0|3] "" Vector__XXX
 SG_ HVESFanServiceInd : 56|2@1+ (1,0) [0|3] "" Vector__XXX
 SG_ HVESFanPwr : 40|16@1+ (0.5,0) [0|32127.5] "W" Vector__XXX
 SG_ HVESFanMediumTemp : 24|16@1+ (0.03125,-273) [-273|1734.96875] "°C" Vector__XXX
 SG_ HVESFanSpd : 8|16@1+ (0.5,0) [0|32127.5] "rpm" Vector__XXX
 SG_ HVESFanCmdStatus : 6|2@1+ (1,0) [0|3] "" Vector__XXX
 SG_ HVESFanStatusReasonCode : 2|4@1+ (1,0) [0|15] "" Vector__XXX
 SG_ HVESFanEnableStatus : 0|2@1+ (1,0) [0|3] "" Vector__XXX

BO_ 2566644990 GFI7: 8 Vector__XXX
 SG_ StorageCompartment3Temp2 : 56|8@1+ (1,-40) [-40|210] "°C" Vector__XXX
 SG_ StorageCompartment3Temp1 : 48|8@1+ (1,-40) [-40|210] "°C" Vector__XXX
 SG_ StorageCompartment2Temp2 : 40|8@1+ (1,-40) [-40|210] "°C" Vector__XXX
 SG_ StorageCompartment2Temp1 : 32|8@1+ (1,-40) [-40|210] "°C" Vector__XXX
 SG_ StorageCompartment1Temp2 : 24|8@1+ (1,-40) [-40|210] "°C" Vector__XXX
 SG_ StorageCompartment1Temp1 : 16|8@1+ (1,-40) [-40|210] "°C" Vector__XXX
 SG_ FrontFuelRecpCoverStatus : 8|2@1+ (1,0) [0|3] "" Vector__XXX
 SG_ PsgrSideFuelRecp2CoverStatus : 6|2@1+ (1,0) [0|3] "" Vector__XXX
 SG_ PsgrSideFuelRecp1CoverStatus : 4|2@1+ (1,0) [0|3] "" Vector__XXX
 SG_ DriverSideFuelRecp2CoverStatus : 2|2@1+ (1,0) [0|3] "" Vector__XXX
 SG_ DriverSideFuelRecp1CoverStatus : 0|2@1+ (1,0) [0|3] "" Vector__XXX

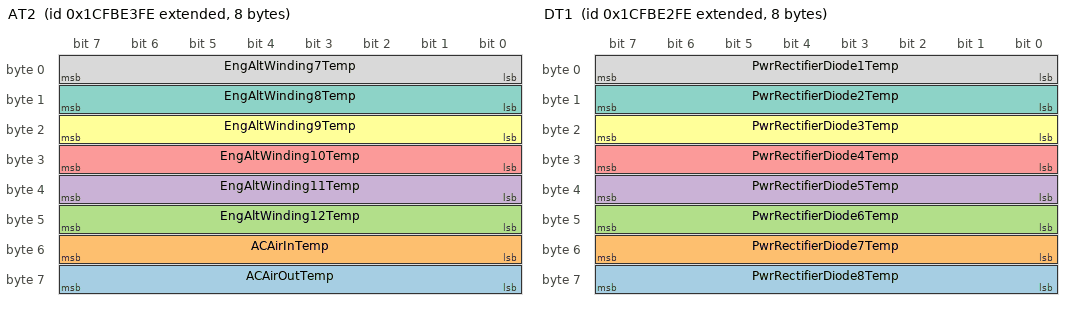
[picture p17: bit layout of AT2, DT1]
BO_ 2633753598 AT2: 8 Vector__XXX
 SG_ ACAirOutTemp : 56|8@1+ (1,-40) [-40|210] "°C" Vector__XXX
 SG_ ACAirInTemp : 48|8@1+ (1,-40) [-40|210] "°C" Vector__XXX
 SG_ EngAltWinding12Temp : 40|8@1+ (1,-40) [-40|210] "°C" Vector__XXX
 SG_ EngAltWinding11Temp : 32|8@1+ (1,-40) [-40|210] "°C" Vector__XXX
 SG_ EngAltWinding10Temp : 24|8@1+ (1,-40) [-40|210] "°C" Vector__XXX
 SG_ EngAltWinding9Temp : 16|8@1+ (1,-40) [-40|210] "°C" Vector__XXX
 SG_ EngAltWinding8Temp : 8|8@1+ (1,-40) [-40|210] "°C" Vector__XXX
 SG_ EngAltWinding7Temp : 0|8@1+ (1,-40) [-40|210] "°C" Vector__XXX

BO_ 2633753342 DT1: 8 Vector__XXX
 SG_ PwrRectifierDiode8Temp : 56|8@1+ (1,-40) [-40|210] "°C" Vector__XXX
 SG_ PwrRectifierDiode7Temp : 48|8@1+ (1,-40) [-40|210] "°C" Vector__XXX
 SG_ PwrRectifierDiode6Temp : 40|8@1+ (1,-40) [-40|210] "°C" Vector__XXX
 SG_ PwrRectifierDiode5Temp : 32|8@1+ (1,-40) [-40|210] "°C" Vector__XXX
 SG_ PwrRectifierDiode4Temp : 24|8@1+ (1,-40) [-40|210] "°C" Vector__XXX
 SG_ PwrRectifierDiode3Temp : 16|8@1+ (1,-40) [-40|210] "°C" Vector__XXX
 SG_ PwrRectifierDiode2Temp : 8|8@1+ (1,-40) [-40|210] "°C" Vector__XXX
 SG_ PwrRectifierDiode1Temp : 0|8@1+ (1,-40) [-40|210] "°C" Vector__XXX

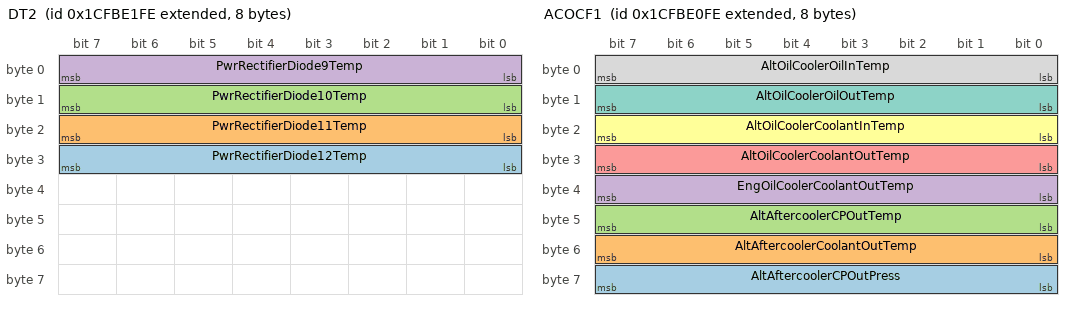
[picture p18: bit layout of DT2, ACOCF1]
BO_ 2633753086 DT2: 8 Vector__XXX
 SG_ PwrRectifierDiode12Temp : 24|8@1+ (1,-40) [-40|210] "°C" Vector__XXX
 SG_ PwrRectifierDiode11Temp : 16|8@1+ (1,-40) [-40|210] "°C" Vector__XXX
 SG_ PwrRectifierDiode10Temp : 8|8@1+ (1,-40) [-40|210] "°C" Vector__XXX
 SG_ PwrRectifierDiode9Temp : 0|8@1+ (1,-40) [-40|210] "°C" Vector__XXX

BO_ 2633752830 ACOCF1: 8 Vector__XXX
 SG_ AltAftercoolerCPOutPress : 56|8@1+ (2,0) [0|500] "kPa" Vector__XXX
 SG_ AltAftercoolerCoolantOutTemp : 48|8@1+ (1,-40) [-40|210] "°C" Vector__XXX
 SG_ AltAftercoolerCPOutTemp : 40|8@1+ (1,-40) [-40|210] "°C" Vector__XXX
 SG_ EngOilCoolerCoolantOutTemp : 32|8@1+ (1,-40) [-40|210] "°C" Vector__XXX
 SG_ AltOilCoolerCoolantOutTemp : 24|8@1+ (1,-40) [-40|210] "°C" Vector__XXX
 SG_ AltOilCoolerCoolantInTemp : 16|8@1+ (1,-40) [-40|210] "°C" Vector__XXX
 SG_ AltOilCoolerOilOutTemp : 8|8@1+ (1,-40) [-40|210] "°C" Vector__XXX
 SG_ AltOilCoolerOilInTemp : 0|8@1+ (1,-40) [-40|210] "°C" Vector__XXX

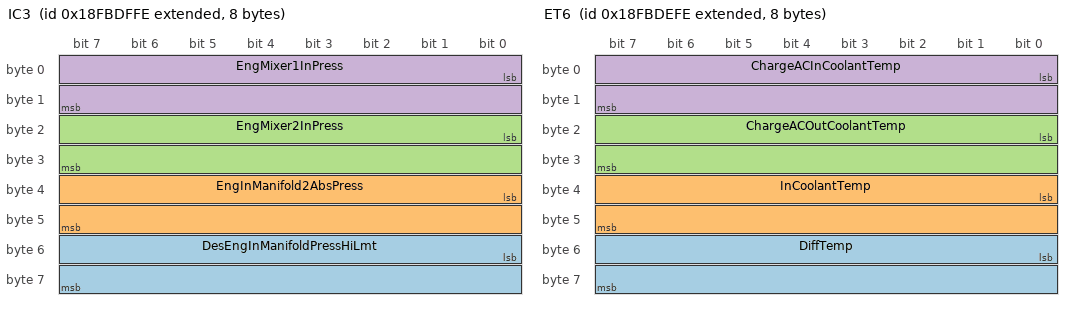
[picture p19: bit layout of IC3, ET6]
BO_ 2566643710 IC3: 8 Vector__XXX
 SG_ DesEngInManifoldPressHiLmt : 48|16@1+ (0.1,0) [0|6425.5] "kPa" Vector__XXX
 SG_ EngInManifold2AbsPress : 32|16@1+ (0.1,0) [0|6425.5] "kPa" Vector__XXX
 SG_ EngMixer2InPress : 16|16@1+ (0.1,0) [0|6425.5] "kPa" Vector__XXX
 SG_ EngMixer1InPress : 0|16@1+ (0.1,0) [0|6425.5] "kPa" Vector__XXX

BO_ 2566643454 ET6: 8 Vector__XXX
 SG_ DiffTemp : 48|16@1+ (0.03125,-273) [-273|1734.96875] "°C" Vector__XXX
 SG_ InCoolantTemp : 32|16@1+ (0.03125,-273) [-273|1734.96875] "°C" Vector__XXX
 SG_ ChargeACOutCoolantTemp : 16|16@1+ (0.03125,-273) [-273|1734.96875] "°C" Vector__XXX
 SG_ ChargeACInCoolantTemp : 0|16@1+ (0.03125,-273) [-273|1734.96875] "°C" Vector__XXX

BO_ 2566643198 DC3: 8 Vector__XXX
 SG_ EnableStatusOfDoor20 : 58|2@1+ (1,0) [0|3] "" Vector__XXX
 SG_ OpenStatusOfDoor20 : 56|2@1+ (1,0) [0|3] "" Vector__XXX
 SG_ LockStatusOfDoor20 : 54|2@1+ (1,0) [0|3] "" Vector__XXX
 SG_ EnableStatusOfDoor19 : 52|2@1+ (1,0) [0|3] "" Vector__XXX
 SG_ OpenStatusOfDoor19 : 50|2@1+ (1,0) [0|3] "" Vector__XXX
 SG_ LockStatusOfDoor19 : 48|2@1+ (1,0) [0|3] "" Vector__XXX
 SG_ EnableStatusOfDoor18 : 46|2@1+ (1,0) [0|3] "" Vector__XXX
 SG_ OpenStatusOfDoor18 : 44|2@1+ (1,0) [0|3] "" Vector__XXX
 SG_ LockStatusOfDoor18 : 42|2@1+ (1,0) [0|3] "" Vector__XXX
 SG_ EnableStatusOfDoor17 : 40|2@1+ (1,0) [0|3] "" Vector__XXX
 SG_ OpenStatusOfDoor17 : 38|2@1+ (1,0) [0|3] "" Vector__XXX
 SG_ LockStatusOfDoor17 : 36|2@1+ (1,0) [0|3] "" Vector__XXX
 SG_ EnableStatusOfDoor16 : 34|2@1+ (1,0) [0|3] "" Vector__XXX
 SG_ OpenStatusOfDoor16 : 32|2@1+ (1,0) [0|3] "" Vector__XXX
 SG_ LockStatusOfDoor16 : 30|2@1+ (1,0) [0|3] "" Vector__XXX
 SG_ EnableStatusOfDoor15 : 28|2@1+ (1,0) [0|3] "" Vector__XXX
 SG_ OpenStatusOfDoor15 : 26|2@1+ (1,0) [0|3] "" Vector__XXX
 SG_ LockStatusOfDoor15 : 24|2@1+ (1,0) [0|3] "" Vector__XXX
 SG_ EnableStatusOfDoor14 : 22|2@1+ (1,0) [0|3] "" Vector__XXX
 SG_ OpenStatusOfDoor14 : 20|2@1+ (1,0) [0|3] "" Vector__XXX
 SG_ LockStatusOfDoor14 : 18|2@1+ (1,0) [0|3] "" Vector__XXX
 SG_ EnableStatusOfDoor13 : 16|2@1+ (1,0) [0|3] "" Vector__XXX
 SG_ OpenStatusOfDoor13 : 14|2@1+ (1,0) [0|3] "" Vector__XXX
 SG_ LockStatusOfDoor13 : 12|2@1+ (1,0) [0|3] "" Vector__XXX
 SG_ EnableStatusOfDoor12 : 10|2@1+ (1,0) [0|3] "" Vector__XXX
 SG_ OpenStatusOfDoor12 : 8|2@1+ (1,0) [0|3] "" Vector__XXX
 SG_ LockStatusOfDoor12 : 6|2@1+ (1,0) [0|3] "" Vector__XXX
 SG_ EnableStatusOfDoor11 : 4|2@1+ (1,0) [0|3] "" Vector__XXX
 SG_ OpenStatusOfDoor11 : 2|2@1+ (1,0) [0|3] "" Vector__XXX
 SG_ LockStatusOfDoor11 : 0|2@1+ (1,0) [0|3] "" Vector__XXX

CM_ BO_ 2565917438 "DC/AC Accessory Inverter 1 Feedback 2
Sent by this Accessory Inverter instance and contains the current operating conditions of this output of the inverter.  This message would be received by a controller application (e.g. Power System Manager) ...";
CM_ SG_ 2565917438 PLedDueToUndefinedReason "Output power is being limited due to an undefined reason.

00b = No power limit for this reason
01b = Power limited for this reason
10b = Error
11b = Not Available";
CM_ SG_ 2565917438 PLedDueToRateOfChangeLmt "Output power is being limited due to the frequency approaching or exceeding the rate of change limit (see SPN 8332).

00b = No power limit for this reason
01b = Power limited for this reason
10b = Error
11b = Not Available";
CM_ SG_ 2565917438 PLedDueToPwrETemp "Output power is being limited due to power electronics temperature (see SPN 9206) approaching or exceeding the maximum limit.

00b = No power limit for this reason
01b = Power limited for this reason
10b = Error
11b = Not Available";
CM_ SG_ 2565917438 PLedDueToEFilterTemp "Output power is being limited due to electronic filter temperature (see SPN 9205) approaching or exceeding the maximum limit.

00b = No power limit for this reason
01b = Power limited for this reason
10b = Error
11b = Not Available";
CM_ SG_ 2565917438 PLedDueToCtrlTemp "Output power is being limited due to the controller temperature (see SPN 9204) approaching or exceeding the maximum limit.

00b = No power limit for this reason
01b = Power limited for this reason
10b = Error
11b = Not Available";
CM_ SG_ 2565917438 FreqCmdExceedsMax "Output frequency is being limited due to frequency command (see SPN 8333) approaching or exceeding the maximum limit (SPN 8328).

00b = No frequency limit for this reason
01b = Frequency limited for this reason
10b = Error
11b = Not Available";
CM_ SG_ 2565917438 FreqCmdBelowMin "Output frequency is being limited due to frequency command (see SPN 8333) approaching or falling below the minimum limit (SPN 8329).
00b = No frequency limit for this reason
01b = Frequency limited for this reason
10b = Error
11b = Not Available
 ...";
CM_ SG_ 2565917438 PLedDueToDCSideVMin "Output power is being limited due to DC Side input voltage (see SPN 8890) approaching or falling below the minimum limit (SPN 9225).

00b = No power limit for this reason
01b = Power limited for this reason
10b = Error
11b = Not Available";
CM_ SG_ 2565917438 PLedDueToACSideRMSCur "AC Side Output power is being limited due to AC Side output RMS current (see SPN 9200) approaching or exceeding the maximum limit (See SPN 9228).
00b = No power limit for this reason
01b = Power limited for this reason
10b = Error
11b = Not ...";
CM_ SG_ 2565917438 PLedDueToDCSideCur "Output power is being limited due to DC Side input current (see SPN 8891) approaching or exceeding the maximum limit (See SPN 9226).

00b = No power limit for this reason
01b = Power limited for this reason
10b = Error
11b = Not Available";
CM_ BO_ 2364590590 "DC/AC Accessory Inverter 1 Voltage
Low Voltage data from DC/AC Accessory Inverter.";
CM_ SG_ 2364590590 SLIV "Continuously supplied SLI power to this instance of the DC/AC Accessory Inverter controller.";
CM_ SG_ 2364590590 IgntV "Ignition voltage supplied to the  DC/AC Accessory Inverter controller.";
CM_ BO_ 2364590334 "DC/AC Accessory Inverter 1 Status 2
Additional data reported from DC/AC Accessory Inverter";
CM_ SG_ 2364590334 DCSideNegToChassisGroundV "The voltage level of the high voltage DC side, as measured by the DC/AC between the negative side of the High Voltage DC Side input and the chassis of the DC/AC enclosure.  This voltage can be used for system level monitoring of DC Side High Voltage ...";
CM_ SG_ 2364590334 DCSideCur "DC Side input current measured at the point of control inside the DC/AC Accessory Inverter.";
CM_ SG_ 2364590334 DCSideV "DC Side input voltage measured at the point of control inside the DC/AC Accessory Inverter.";
CM_ SG_ 2364590334 DCSidePwr "Power measured at the DC Side input to the DC/AC Accessory Inverter.";
CM_ BO_ 2624519934 "Configurable Receive SPNs Command
PGN 28160 and PGN 64462 are used to manage and report configurable parameters that are received by a Configurable ECU. PGN 28160 is used by an ECU to request the current receive parameter configuration or to ...";
CM_ SG_ 2624519934 CommandedReceiveSPNSA "The source address from which the Configurable ECU shall receive the SP identified in SPN 8839.
0 to 253 = Source Address that the Configurable ECU should use to receive the Configurable Receive SP.
254 = The command in SPN 8840 applies to all ...";
CM_ SG_ 2624519934 CommandedReceiveSPNReqSt "Identifies the receive enable state being commanded for the specified SP on the port identified in SPN 8837. This parameter is only valid when SPN 8838 is set to 'Configure Port Receive State' (1). For transaction modes where this parameter is not ...";
CM_ SG_ 2624519934 CommandedReceiveSPN "Identifies the SP to be acted on by the associated SPN 8840.";
CM_ SG_ 2624519934 TransactionMode "Identifies the command or action being commanded to the target Configurable ECU of this instance of PGN 28160.
0000b = Request Port Receive Status - Identifies the message as a request for the list of configurable receive SPs on the port identified ...";
CM_ SG_ 2624519934 CommandedPort "Identifies the ECU communication port of the target Configurable ECU for this instance of PGN 28160. The identification of each ECU communication port is ECU specific. The correlation of ECU communication port to a physical network connection is ...";
CM_ BO_ 2557345534 "Well Stimulation Pump System Configuration Command
Configures the threshold of operating parameters of a well stimulation pump used in oil and gas drilling applications.
See PGN 64461 for the feedback of current settings of the operating ...";
CM_ SG_ 2557345534 PlungerFiringOrder "Well stimulation pump plunger firing order
0000b = Firing order 1-2-3
0001b = Firing order 1-5-2-3-4
0010b = Reserved
0011b = Reserved
0100b = Reserved
0101b = Reserved
0110b = Reserved
0111b = Reserved
1000b = Reserved
1001b = Reserved
 ...";
CM_ SG_ 2557345534 RodLoadHiThreshold "Rod load force at which the rod load is considered at the highest acceptable force.";
CM_ SG_ 2557345534 CrankshaftSpdHiThreshold "Well stimulation pump crankshaft speed that has been considered to be the highest acceptable speed.";
CM_ SG_ 2557345534 CrankshaftSpdLowThreshold "The minimum speed of Well stimulation pump crankshaft that is considered to be valid.";
CM_ SG_ 2557345534 DisPressHiThreshold "Pressure at which the discharge pressure is considered at the highest acceptable pressure.";
CM_ SG_ 2557345534 SuctionPressHiThreshold "Pressure at which the suction pressure is considered at the highest acceptable pressure.";
CM_ SG_ 2557345534 SuctionPressLowThreshold "Pressure at which the suction pressure is considered at the lowest acceptable pressure.";
CM_ SG_ 2557345534 GearBoxOilTempHiThreshold "Temperature at which the gearbox oil temperature is considered at the highest acceptable temperature.";
CM_ SG_ 2557345534 GearBoxOilTempLowThreshold "Temperature at which the gearbox oil temperature is considered at the lowest acceptable temperature.";
CM_ SG_ 2557345534 GearBoxOilPressHiThreshold "Pressure at which the gearbox oil pressure is considered at the highest acceptable pressure.";
CM_ SG_ 2557345534 GearBoxOilPressLowThreshold "Pressure at which the gearbox oil pressure is considered at the lowest acceptable pressure.";
CM_ BO_ 2557214462 "Well Stimulation Pump Sensor Calibration Command
Calibration setting commands for the Well Stimulation Pump System.";
CM_ SG_ 2557214462 DisPressCalSetPointCmd "Specifies the current discharge pressure whose calibration status is being reported. Multipoint calibration of the discharge pressure system is performed by increasing the pressure with up to 10 known calibration pressures. For each calibration ...";
CM_ SG_ 2557214462 SuctionPressCalSetPointCmd "Specifies the current suction pressure being calibrated. Multipoint calibration of the suction pressure
system is performed by increasing the pressure with up to 10 known calibration pressures. For each
calibration pressure, the Well Stimulation ...";
CM_ BO_ 2557148926 "Marine Control Information 2
Marine vessel control information for the vessel control system.";
CM_ SG_ 2557148926 VesselSpdCtrlMode "The vessel set speed type that is selected by the operator.

00h = No Set Speed
01h = Slow Vessel Mode
02h = Synchronization Mode
03h = Trolling Mode
04h to FDh = Reserved
FEh = Error
FFh = Not Available";
CM_ SG_ 2557148926 VesselEngSetSpd "The (chosen) vessel speed that has been selected by the operator.";
CM_ SG_ 2557148926 TrollingModeCurSetting "The current setting of the Trolling Mode.  In traditional trolling mode, engine speed remains constant while the throttle lever changes the amount of slip within the transmission clutches. In advanced trolling mode, the throttle lever controls ...";
CM_ SG_ 2557148926 TrollingMode "The active status of the Trolling Mode (Extended Range). In traditional trolling mode, engine speed remains constant while the throttle lever changes the amount of slip within the transmission clutches. In advanced trolling mode, the throttle lever ...";
CM_ SG_ 2557148926 EngThrotSynchModeCurSetting "The current setting of the engine throttle synchronization mode. Throttle synchronization mode indicates which throttle, if any, is to be used for the synchronized throttle.
0000b = Not Synchronized
0001b = Synchronized Center
0010b = ...";
CM_ SG_ 2557148926 OpStationLockout "Indicates the status of a lockout to prevent changing the active control station. Lockout active indicates a change is not permitted to the active control station.
00b = Station Lockout Inactive
01b = Station Lockout Active
10b = Error
11b = Not ...";
CM_ SG_ 2557148926 OpStationInCtrlLocation "Identifies the location of the operator station that is currently in control of the system.
00h = Bridge
01h = Port Wing
02h = Starboard Wing
03h = Tower
04h = Engine Room
05h = Aft. Station
06h = Fly Bridge
07h = Bow Station
08h to FDh = ...";
CM_ BO_ 2557083390 "Marine Control Information Configuration 1
Marine vessel control configuration information for the vessel control system.";
CM_ SG_ 2557083390 EngTrollingModeSetSpd "The (chosen) vessel trolling speed that has been selected by the operator";
CM_ SG_ 2557083390 EngThrotSynchModeCmd "The setting of the throttle synchronization mode. Throttle synchronization mode is used to indicate which throttle, if any, is used to be used for the synchronized throttle.
0000b = Not Synchronized
0001b = Synchronized Center
0010b = ...";
CM_ SG_ 2557083390 TrollingModeSettingCmd "The commanded setting of the Trolling Mode.  In traditional trolling mode, engine speed remains constant while the throttle lever changes the amount of slip within the transmission clutches. In advanced trolling mode, the throttle lever controls ...";
CM_ SG_ 2557083390 OpStationLocationSetting "Configurable location of the selected operator station.
00h = Bridge
01h = Port Wing
02h = Starboard Wing
03h = Tower
04h = Engine Room
05h = Aft. Station
06h = Fly Bridge
07h = Bow Station
08h to FDh = Reserved
FEh = Error
FFh = Not ...";
CM_ BO_ 2633785086 "High Voltage Energy Storage System History
Historical data for High Voltage Energy Storage System (or Pack 1 in systems with only one pack).";
CM_ SG_ 2633785086 TotalEnergyOut "The cumulative energy which has flowed out of the High Voltage Energy Storage System over the lifetime of the battery system (or Pack 1 in systems with only one pack). In multipack systems this parameter is the sum of the individual packs (See SPN ...";
CM_ SG_ 2633785086 TotalEnergyInput "The cumulative energy which has flowed into the High Voltage Energy Storage System over the lifetime of the battery system (or Pack 1 in systems with only one pack).
In multipack systems this parameter is the sum of the individual packs (See SPN ...";
CM_ SG_ 2633785086 TotalAccumulatedCharge "The total accumulated amp hours which have flowed through High Voltage Energy Storage System (or Pack 1 in systems with only one pack).  This parameter is the sum of the absolute values of the Ampere hours into and out of this HVES instance.
This ...";
CM_ SG_ 2633785086 TotalEnergyThroughput "The total energy throughput which has flowed through High Voltage Energy Storage System (or Pack 1 in systems with only one pack).  This parameter is the sum of the absolute values of the Energy into and out of this HVES instance.
This parameter ...";
CM_ SG_ 2633785086 ContactorOpenUnderLoadCount "This signal represents the number of times the contactors inside the High Voltage Energy Storage System (or Pack 1 in systems with only one pack) have opened while current is flowing through them.  The current level (that determines if an opening ...";
CM_ SG_ 2633785086 StOfHealth "This signal represents the expected remaining \"Life\" of the High Voltage Energy Storage System (or Pack 1 in systems with only one pack), in percent.  Battery life is a manufacturer-specific measure of how well the energy storage system is ...";
CM_ BO_ 2566675966 "High Voltage Energy Storage System Configuration
Configuration data for High Voltage Energy Storage System (or Pack 1 in systems with only one pack).
Note that configuration data should not dynamically change during vehicle operation.";
CM_ SG_ 2566675966 NomRatedCapacity "Per the HVES manufacturer, this is the manufacturer's nominal rated capacity of the High Voltage Energy Storage System (or Pack 1 in systems with only one pack).   In a multipack system, this is the sum of all packs.
This parameter provides HVES ...";
CM_ SG_ 2566675966 NumOfHVESPsConfigured "The number of High Voltage Energy Storage Packs that are currently configured in the HVESS system.";
CM_ SG_ 2566675966 CellMinVLmt "Per the HVES manufacturer, this is the minimum cell voltage for High Voltage Energy Storage System (or Pack 1 in systems with only one pack) operation.  Operating below this value may damage HVES hardware, or compromise HVES life.
This parameter ...";
CM_ SG_ 2566675966 CellMaxVLmt "Per the HVES manufacturer, this is the maximum cell voltage for High Voltage Energy Storage System (or Pack 1 in systems with only one pack) operation.  Operating above this value may damage HVES hardware, or compromise HVES life.
This parameter ...";
CM_ SG_ 2566675966 RecommendedMinOperatingTemp "Per the HVES manufacturer, this is the recommended minimum temperature for High Voltage Energy Storage System (or Pack 1 in systems with only one pack) operation.  Operating below this value may damage HVES hardware, or compromise HVES life.
This ...";
CM_ SG_ 2566675966 RecommendedMaxOperatingTemp "Per the HVES manufacturer, this is the recommended maximum temperature for High Voltage Energy Storage System (or Pack 1 in systems with only one pack) operation.  Operating above this value may damage HVES hardware, or compromise HVES life.
This ...";
CM_ SG_ 2566675966 RecommendedMaxStOfCharge "Per the HVES manufacturer, this is the recommended maximum state of charge for High Voltage Energy Storage System (or Pack 1 in systems with only one pack) operation.  Operating above this value may compromise HVES life.
This parameter provides ...";
CM_ SG_ 2566675966 RecommendedMinStOfCharge "Per the HVES manufacturer, this is the recommended minimum state of charge for High Voltage Energy Storage System (or Pack 1 in systems with only one pack) operation.  Operating below this value may compromise HVES life.
This parameter provides ...";
CM_ SG_ 2566675966 RecommendedMaxOperatingV "Per the HVES manufacturer, this is the maximum recommended voltage level for High Voltage Energy Storage System (or Pack 1 in systems with only one pack) operation.  Operating above this value may compromise HVES life.
This parameter provides HVES ...";
CM_ SG_ 2566675966 RecommendedMinOperatingV "Per the HVES manufacturer, this is the minimum recommended voltage level for High Voltage Energy Storage System (or Pack 1 in systems with only one pack) operation.  Operating below this value may compromise HVES life.
This parameter provides HVES ...";
CM_ SG_ 2566675966 NominalV "Per the HVES manufacturer, this is the nominal operating voltage of the High Voltage Energy Storage System (or Pack 1 in systems with only one pack), e.g. “300V” or “600V”.
This parameter provides HVES system level information. If there are ...";
CM_ BO_ 2566661886 "Aftertreatment 2 Diesel Exhaust Fluid Information 2
Sensor Information which measures temperature, concentration, and conductivity of the diesel exhaust fluid of the aftertreatment 2 system.";
CM_ SG_ 2566661886 Ctrl2Temp "Temperature of the diesel exhaust fluid at the aftertreatment 2 diesel exhaust fluid controller 2.";
CM_ SG_ 2566661886 CtrlTemp "Temperature of the diesel exhaust fluid at the aftertreatment 2 diesel exhaust fluid controller.";
CM_ BO_ 2566656254 "Ambient Conditions 3
This message contains measurement and configuration information about the vehicle ambient conditions.";
CM_ SG_ 2566656254 EngPwrDerateRelHumidityDiff "Indicates the current relative humidity compared to available relative humidity before engine power derate occurs.
Positive values represents how much relative humidity is available before the derate.  Negative values represents the percentage of ...";
CM_ SG_ 2566656254 EngIn2AirTemp "Temperature of air entering through a second vehicle air induction system.";
CM_ SG_ 2566656254 BarometricAbsPress2 "Second absolute air pressure measurement of the atmosphere.

See SPN 108 or SPN 5685 as the primary barometric pressure measurement.";
CM_ BO_ 2566655998 "Secondary or Front Hitch Roll and Pitch Sensitivity
Provides current sensitivity of the front hitch roll and pitch control loops.";
CM_ SG_ 2566655998 PitchSensitivity "The current sensitivity of the front hitch pitch control expressed as a percentage of the maximum gain.  0% indicates minimal gain in the control loop; 100%, the maximum gain. Values near zero may result in no reaction by the control loop.";
CM_ SG_ 2566655998 Sensitivity "The current sensitivity of the front hitch roll control expressed as a percentage of the maximum gain.  0% indicates minimal gain in the control loop; 100%, the maximum gain. Values near zero may result in no reaction by the control loop.";
CM_ BO_ 2566655742 "Primary or Rear Hitch Roll and Pitch Sensitivity
Provides current sensitivity of the rear hitch roll and pitch control loops.";
CM_ SG_ 2566655742 PitchSensitivity "The current sensitivity of the rear hitch pitch control expressed as a percentage of the maximum gain.  0% indicates minimal gain in the control loop; 100%, the maximum gain. Values near zero may result in no reaction by the control loop.";
CM_ SG_ 2566655742 Sensitivity "The current sensitivity of the rear hitch roll control expressed as a percentage of the maximum gain.  0% indicates minimal gain in the control loop; 100%, the maximum gain. Values near zero may result in no reaction by the control loop.";
CM_ BO_ 2633764350 "Fire Pump Statistics 1
Contains statistics of the fire apparatus pump.";
CM_ SG_ 2633764350 EngagementCycles "Accumulated number of times the fire pump has been engaged.";
CM_ SG_ 2633764350 OpTime "Accumulated time that the fire pump is enaged.";
CM_ BO_ 2633764094 "Evaporative Systems
This message contains data for the evaporative emissions system";
CM_ SG_ 2633764094 GasolineFuelTankPress "The gage pressure of the vapor in the gasoline fuel tank.";
CM_ SG_ 2633764094 CanisterPurgeVlvCmd "The commanded positon of the canister purge valve used to allow fuel vapors from the charcoal canister into the intake manifold.

A value of 0 % indicates fully closed, a value of 100 % indicates fully open.";
CM_ SG_ 2633764094 CanisterVentVlv "The state of the canister vent value used to allow fresh air into the charcoal vapor canister.

00b = Vent Valve is Closed
01b = Vent Valve is Open
10b = Error
11b = Not Available";
CM_ BO_ 2566654974 "Electronic Engine Controller 20";
CM_ SG_ 2566654974 AbsEngLoadPercentAirMass "Absolute Engine Load - Percent Air Mass is the normalized value of air mass per intake stroke displayed as a percent.
Vehicles which utilize spark or compression ignition engines for propulsion shall use the following definition for calculating ...";
CM_ SG_ 2566654974 NomFrictionPercentTrq "Indicates the amount of torque required by the basic engine itself added by the loss torque of accessories. It contains the frictional and thermodynamic loss of the engine itself, pumping torque loss (SPN 5398), and the losses of fuel, oil and ...";
CM_ SG_ 2566654974 ActualMaxAvailableEngPercentFuel "The percent of torque limited fuel relative to the engine standard torque fuel.  The torque limited fuel in the Actual Maximum Available Engine - Percent Fuel shall take into consideration all engine torque derates (e.g. fault / event derates, ...";
CM_ SG_ 2566654974 EstEngParasiticLossesPercentTrq "Indicates the estimated amount of torque loss due to engine parasitics, such as cooling fan, air compressor, air conditioning, etc. It is expressed as a percent of Engine Reference Torque.
If there are multiple devices on a network that provide ...";
CM_ BO_ 2566654718 "Vehicle Electrical Power 7
Parameters of the first battery in the first set of batteries (battery pack) used for starting, lighting, and ignition (SLI).";
CM_ SG_ 2566654718 SLIBatPack1Bat1V "Voltage of the first battery in the first set of batteries (battery pack) used for starting, lighting and ignition (SLI).
In the case of EV, this parameter indicates the voltage of the first battery in the first set of batteries (battery pack) used ...";
CM_ SG_ 2566654718 SLIBatPack1Bat1Temp "Temperature of the first battery in the first set of batteries (battery pack) used for starting, lighting and ignition (SLI).

The relation to physical location is determined by the equipment manufacturer.";
CM_ SG_ 2566654718 SLIBatPack1Bat1NetCur "Net flow of electrical current into/out of the first battery in the first set of batteries (battery pack) used for starting, lighting and ignition (SLI).";
CM_ BO_ 2566654462 "Vehicle Electrical Power 8
Parameters of the first battery in the first set of batteries (battery pack) used for starting, lighting, and ignition (SLI).";
CM_ SG_ 2566654462 SLIBatPack1Snsr1InitStatus "The battery sensor may go through an initialization process when it is first connected to a battery.  This parameter reports the battery sensor's progress through the initialization process.
0 = Initialization process has not started.
1 to 9 = ...";
CM_ SG_ 2566654462 SLIBatPack1Bat1PredMinCrankingV "Prediction of the minimum battery voltage of the first battery in the first battery pack used for starting, lighting and ignition (SLI) during a starting/ cranking event, under present battery conditions.
Parameter Specific Indicator:  A value of ...";
CM_ SG_ 2566654462 SLIBatPack1Bat1Health "Capacity of the first battery in the first battery pack relative to its original specification for the battery pack used for starting, lighting and ignition (SLI).
0% means battery pack is not capable of holding any charge, 100% means battery pack ...";
CM_ SG_ 2566654462 SLIBatPack1Bat1Capacity "Total reserve capacity of the first battery in the first battery pack used for starting, lighting and ignition (SLI).
This value could be the original capacity, rated capacity, or the capacity received in SPN 9368.
Parameter Specific Indicator:  A ...";
CM_ SG_ 2566654462 SLIBatPack1Bat1StOfCharge "Indicates the remaining charge of the first battery in the first battery pack used for starting, lighting and ignition (SLI).
0% means no charge remaining, 100% means full capacity at the battery's current state of health.
Parameter Specific ...";
CM_ BO_ 2566654206 "Vehicle Electrical Power 9
Parameters of the second battery in the first set of batteries (battery pack) used for starting, lighting and ignition (SLI).";
CM_ SG_ 2566654206 SLIBatPack1Bat2V "Voltage of the second battery in the first set of batteries (battery pack) used for starting, lighting and ignition (SLI). 

The relation to physical location is determined by the equipment manufacturer.";
CM_ SG_ 2566654206 SLIBatPack1Bat2Temp "Temperature of the second battery in the first set of batteries (battery pack) used for starting, lighting and ignition (SLI). 

The relation to physical location is determined by the equipment manufacturer.";
CM_ SG_ 2566654206 SLIBatPack1Bat2NetCur "Net flow of electrical current into/out of the second battery in the first set of batteries (battery pack) used for starting, lighting and ignition (SLI).";
CM_ BO_ 2566653950 "Vehicle Electrical Power 10
Parameters of the second battery in the first set of batteries (battery pack) used for starting, lighting and ignition (SLI).";
CM_ SG_ 2566653950 SLIBatPack1Snsr2InitStatus "The battery sensor may go through an initialization process when it is first connected to a battery.  This parameter reports the battery sensor's progress through the initialization process.
0 = Initialization process has not started.
1 to 9 = ...";
CM_ SG_ 2566653950 SLIBatPack1Bat2PredMinCrankingV "Prediction of the minimum battery voltage of the second battery in the first battery pack used for starting, lighting and ignition (SLI) during a starting/cranking event, under present battery conditions.
Parameter Specific Indicator:  A value of ...";
CM_ SG_ 2566653950 SLIBatPack1Bat2Health "Capacity of the second battery in the first battery pack relative to its original specification for the battery pack used for starting, lighting and ignition (SLI). 0% means battery pack is not capable of holding any charge, 100% means battery pack ...";
CM_ SG_ 2566653950 SLIBatPack1Bat2Capacity "Total reserve capacity of the second battery in the first battery pack used for starting, lighting and ignition (SLI).  This value could be the original capacity, rated capacity, or the capacity received in SPN 9369.
Parameter Specific Indicator ...";
CM_ SG_ 2566653950 SLIBatPack1Bat2StOfCharge "Indicates the remaining charge of the second battery in the first battery pack used for starting, lighting and ignition (SLI). 0% means no charge remaining, 100% means full capacity at the battery's current state of health.
Parameter Specific ...";
CM_ BO_ 2566653694 "Vehicle Electrical Power 11
Parameters of the third battery in the first set of batteries (battery pack) used for starting, lighting and ignition (SLI).";
CM_ SG_ 2566653694 SLIBatPack1Bat3V "Voltage of the third battery in the first set of batteries (battery pack) used for starting, lighting and ignition (SLI). 

The relation to physical location is determined by the equipment manufacturer.";
CM_ SG_ 2566653694 SLIBatPack1Bat3Temp "Temperature of the third battery in the first set of batteries (battery pack) used for starting, lighting and ignition (SLI). 

The relation to physical location is determined by the equipment manufacturer.";
CM_ SG_ 2566653694 SLIBatPack1Bat3NetCur "Net flow of electrical current into/out of the third battery in the first set of batteries (battery pack) used for starting, lighting and ignition (SLI).";
CM_ BO_ 2566653438 "Vehicle Electrical Power 12
Parameters of the third battery in the first set of batteries (battery pack) used for starting, lighting and ignition (SLI).";
CM_ SG_ 2566653438 SLIBatPack1Snsr3InitStatus "The battery sensor may go through an initialization process when it is first connected to a battery.  This parameter reports the battery sensor's progress through the initialization process.
0 = Initialization process has not started.
1 to 9 = ...";
CM_ SG_ 2566653438 SLIBatPack1Bat3PredMinCrankingV "Prediction of the minimum battery voltage of the third battery in the first battery pack used for starting, lighting and ignition (SLI) during a starting/cranking event, under present battery conditions.
Parameter Specific Indicator:  A value of ...";
CM_ SG_ 2566653438 SLIBatPack1Bat3Health "Capacity of the third battery in the first battery pack relative to its original specification for the battery pack used for starting, lighting and ignition (SLI). 0% means battery pack is not capable of holding any charge, 100% means battery pack ...";
CM_ SG_ 2566653438 SLIBatPack1Bat3Capacity "Total reserve capacity of the third battery in the first battery pack used for starting, lighting and ignition (SLI).  This value could be the original capacity, rated capacity, or the capacity received in SPN 9370.
Parameter Specific Indicator:  A ...";
CM_ SG_ 2566653438 SLIBatPack1Bat3StOfCharge "Indicates the remaining charge of the third battery in the first battery pack used for starting, lighting and ignition (SLI). 0% means no charge remaining, 100% means full capacity at the battery's current state of health.
Parameter Specific ...";
CM_ BO_ 2566653182 "Vehicle Electrical Power 13
Parameters of the fourth battery in the first set of batteries (battery pack) used for starting, lighting and ignition (SLI).";
CM_ SG_ 2566653182 SLIBatPack1Bat4V "Voltage of the fourth battery in the first set of batteries (battery pack) used for starting, lighting and ignition (SLI). 

The relation to physical location is determined by the equipment manufacturer.";
CM_ SG_ 2566653182 SLIBatPack1Bat4Temp "Temperature of the fourth battery in the first set of batteries (battery pack) used for starting, lighting and ignition (SLI). 

The relation to physical location is determined by the equipment manufacturer.";
CM_ SG_ 2566653182 SLIBatPack1Bat4NetCur "Net flow of electrical current into/out of the fourth battery in the first set of batteries (battery pack) used for starting, lighting and ignition (SLI).";
CM_ BO_ 2566652926 "Vehicle Electrical Power 14
Parameters of the fourth battery in the first set of batteries (battery pack) used for starting, lighting and ignition (SLI).";
CM_ SG_ 2566652926 SLIBatPack1Snsr4InitStatus "The battery sensor may go through an initialization process when it is first connected to a battery.  This parameter reports the battery sensor's progress through the initialization process.
0 = Initialization process has not started.
1 to 9 = ...";
CM_ SG_ 2566652926 SLIBatPack1Bat4PredMinCrankingV "Prediction of the minimum battery voltage of the fourth battery in the first battery pack used for starting, lighting and ignition (SLI) during a starting/cranking event, under present battery conditions.
Parameter Specific Indicator:  A value of ...";
CM_ SG_ 2566652926 SLIBatPack1Bat4Health "Capacity of the fourth battery in the first battery pack relative to its original specification for the battery pack used for starting, lighting and ignition (SLI). 0% means battery pack is not capable of holding any charge, 100% means battery pack ...";
CM_ SG_ 2566652926 SLIBatPack1Bat4Capacity "Total reserve capacity of the fourth battery in the first battery pack used for starting, lighting and ignition (SLI).  This value could be the original capacity, rated capacity, or the capacity received in SPN 9371.
Parameter Specific Indicator ...";
CM_ SG_ 2566652926 SLIBatPack1Bat4StOfCharge "Indicates the remaining charge of the fourth battery in the first battery pack used for starting, lighting and ignition (SLI). 0% means no charge remaining, 100% means full capacity at the battery's current state of health.
Parameter Specific ...";
CM_ BO_ 2566652670 "SCR System Information
Includes parameters related to the SCR system.";
CM_ SG_ 2566652670 A2SysHydrocarbon "The ratio of the mass of hydrocarbon present in the aftertreatment 2 system compared to the maximum allowable mass of hydrocarbon for the aftertreatment system. 100% represents the maximum percentage of hydrocarbon loading that can safely be handled ...";
CM_ SG_ 2566652670 A2DEFDosingSysFrozen "All or part of the diesel exhaust fluid system (DEF tank, DEF supply lines, DEF pump, and DEF doser, etc.) in bank 2 is frozen.
In situations where it is desired to report the DEF system frozen as a faulted condition, FMI 31 can be used with this ...";
CM_ SG_ 2566652670 A1DEFDosingSysFrozen "All or part of the diesel exhaust fluid system (DEF tank, DEF supply lines, DEF pump, and DEF doser, etc.) in bank 1 is frozen.
In situations where it is desired to report the DEF system frozen as a faulted condition, FMI 31 can be used with this ...";
CM_ SG_ 2566652670 A1SysHydrocarbon "The ratio of the mass of hydrocarbon present in the aftertreatment system compared to the maximum allowable mass of hydrocarbon for the aftertreatment system. 100% represents the maximum percentage of hydrocarbon loading that can safely be handled ...";
CM_ SG_ 2566652670 DEFFrozenTime "Indicates the amount of time the diesel exhaust fluid is frozen while key switch is on. This will accumulate over the life of the product, and will never be reset.

This parameter is not for engine applications that are capable of being derated.";
CM_ BO_ 2566652414 "Electrified Accessory Motor Status 1
Status data set 1 of electrified accessory motor controller.   See PGN 32000 for the corresponding command message.  This PG should only be used in a case where the specific PG for the Electrified Accessory is ...";
CM_ SG_ 2566652414 Instance "Indicates the electrified accessory instance that is providing status data set 1.
0000b = Instance 1
0001b = Instance 2
0010b = Instance 3
0011b = Instance 4
0100b = Instance 5
0101b = Instance 6
0110b = Instance 7
0111b = Instance 8
1000b ...";
CM_ SG_ 2566652414 OperatingStatus "Indicates the operating status of this Electrified Accessory Motor system or component.  This parameter is used to inform other devices that this system or component is no longer performing to its operational capacity and that reduced, or no flow of ...";
CM_ SG_ 2566652414 ServiceInd "Indicates that service is required for this Electrified Accessory Motor system or component.  An active indication may convey a need for component replacement or periodic service.  The Electrified Accessory Motor Controller Status Reason Code (SPN ...";
CM_ SG_ 2566652414 Pwr "Calculated electrical power consumed by this Electrified Accessory Motor.";
CM_ SG_ 2566652414 MediumTemp "A temperature measured and reported by the device.  It may be used for direct or remote (e.g. by another controller) control of the pump.  For example, this may be the temperature of the fluid flowing through the pump, or some other temperature ...";
CM_ SG_ 2566652414 Spd "Speed of this Electrified Accessory Motor.";
CM_ SG_ 2566652414 CtrlCmdStatus "Indicates the source of the speed command to this Electrified Accessory Motor system or component.
00b is communicated when the controller is self-controlled (e.g. based on a temperature sensor).
01b is communicated when responding to the ...";
CM_ SG_ 2566652414 CtrlStatusReasonCode "Provides the reason code describing the unique failure of this Electrified Accessory Motor system or component.
If a detailed reason code is not used by the supporting application, or this reason code is Not Available, the Electrified Accessory ...";
CM_ SG_ 2566652414 EnableStatus "Enable and direction status of this Electrified Accessory Motor system or component.

00b = Accessory Motor Off
01b = Accessory Motor On - Normal, Forward, or Default Direction
10b = Accessory Motor On - Reverse Direction
11b = Not available";
CM_ BO_ 2566651902 "Electrified Accessory Power Electronics Coolant Pump Status 1
Status data set 1 of electrified accessory: Power Electronics Coolant Pump.   See PGN 31488 for the corresponding command message.";
CM_ SG_ 2566651902 OperatingStatus "Indicates the operating status of the Power Electronics Coolant Pump system or component.
This parameter is used to inform other devices that this system or component is no longer performing to its operational capacity and that reduced, or no flow, ...";
CM_ SG_ 2566651902 ServiceInd "Indicates that service is required for the Power Electronics Coolant Pump system or component.
An active indication may convey a need for component replacement or periodic service.  The Power Electronics Coolant Pump Controller Status Reason Code ...";
CM_ SG_ 2566651902 Pwr "Calculated electrical power consumed by the Power Electronics Coolant Pump.";
CM_ SG_ 2566651902 CtrlTemp "A temperature measured and reported by the device.  It may be used for direct or remote (e.g. by another controller) control of the pump.  For example, this may be the temperature of the fluid flowing through the pump, or some other temperature ...";
CM_ SG_ 2566651902 MotorSpd "Motor Speed of the Power Electronics Coolant Pump.";
CM_ SG_ 2566651902 CtrlCmdStatus "Indicates the source of the speed command to the Power Electronics Coolant Pump system or component.
00b is communicated when the controller is self-controlled  (e.g. based on a temperature sensor).
01b is communicated when responding to the Power ...";
CM_ SG_ 2566651902 CtrlStatusReasonCode "Provides the reason code describing the unique failure of the Power Electronics Coolant Pump system or component.
If a detailed reason code is not used by the supporting application, or this reason code is Not Available, the Power Electronics ...";
CM_ SG_ 2566651902 EnableStatus "Enable and direction status of the Power Electronics Coolant Pump system or component.

00b = Accessory Motor Off
01b = Accessory Motor On - Normal, Forward, or Default Direction
10b = Accessory Motor On - Reverse Direction
11b = Not available";
CM_ BO_ 2566651646 "Electrified Accessory Propulsion Motor Coolant Pump Status 1
Status data set 1 of electrified accessory: Propulsion Motor Coolant Pump.   See PGN 31232 for the corresponding command message.";
CM_ SG_ 2566651646 OperatingStatus "Indicates the operating status of the Propulsion Motor Coolant Pump system or component.
This parameter is used to inform other devices that this system or component is no longer performing to its operational capacity and that reduced, or no flow, ...";
CM_ SG_ 2566651646 ServiceInd "Indicates that service is required for the Propulsion Motor Coolant Pump system or component.
An active indication may convey a need for component replacement or periodic service.  The Propulsion Motor Coolant Pump Controller Status Reason Code ...";
CM_ SG_ 2566651646 Pwr "Calculated electrical power consumed by the Propulsion Motor Coolant Pump.";
CM_ SG_ 2566651646 CtrlTemp "A temperature measured and reported by the device.  It may be used for direct or remote (e.g. by another controller) control of the pump.  For example, this may be the temperature of the fluid flowing through the pump, or some other temperature ...";
CM_ SG_ 2566651646 MotorSpd "Motor Speed of the Propulsion Motor Coolant Pump.";
CM_ SG_ 2566651646 CtrlCmdStatus "Indicates the source of the speed command to the Propulsion Motor Coolant Pump system or component.
00b is communicated when the controller is self-controlled  (e.g. based on a temperature sensor).
01b is communicated when responding to the ...";
CM_ SG_ 2566651646 CtrlStatusReasonCode "Provides the reason code describing the unique failure of the Propulsion Motor Coolant Pump system or component.
If a detailed reason code is not used by the supporting application, or this reason code is Not Available, the Propulsion Motor Coolant ...";
CM_ SG_ 2566651646 EnableStatus "Enable and direction status of the Propulsion Motor Coolant Pump system or component.

00b = Accessory Motor Off
01b = Accessory Motor On - Normal, Forward, or Default Direction
10b = Accessory Motor On - Reverse Direction
11b = Not available";
CM_ BO_ 2566651390 "Electrified Accessory Propulsion Motor Oil Pump Status 1
Status data set 1 of electrified accessory: Propulsion Motor Oil Pump.   See PGN 30976 for the corresponding command message.";
CM_ SG_ 2566651390 OperatingStatus "Indicates the operating status of the Propulsion Motor Oil Pump system or component.
This parameter is used to inform other devices that this system or component is no longer performing to its operational capacity and that reduced, or no flow, of ...";
CM_ SG_ 2566651390 ServiceInd "Indicates that service is required for the Propulsion Motor Oil Pump system or component.
An active indication may convey a need for component replacement or periodic service.  The Propulsion Motor Oil Pump Controller Status Reason Code (SPN 7996) ...";
CM_ SG_ 2566651390 Pwr "Calculated electrical power consumed by the Propulsion Motor Oil Pump.";
CM_ SG_ 2566651390 CtrlTemp "A temperature measured and reported by the device.  It may be used for direct or remote (e.g. by another controller) control of the pump.  For example, this may be the temperature of the fluid flowing through the pump, or some other temperature ...";
CM_ SG_ 2566651390 MotorSpd "Motor Speed of the Propulsion Motor Oil Pump.";
CM_ SG_ 2566651390 CtrlCmdStatus "Indicates the source of the speed command to the Propulsion Motor Oil Pump system or component.
00b is communicated when the controller is self-controlled  (e.g. based on a temperature sensor).
01b is communicated when responding to the Propulsion ...";
CM_ SG_ 2566651390 CtrlStatusReasonCode "Provides the reason code describing the unique failure of the Propulsion Motor Oil Pump system or component.
If a detailed reason code is not used by the supporting application, or this reason code is Not Available, the Propulsion Motor Oil Pump ...";
CM_ SG_ 2566651390 EnableStatus "Enable and direction status of the Propulsion Motor Oil Pump system or component.

00b = Accessory Motor Off
01b = Accessory Motor On - Normal, Forward, or Default Direction
10b = Accessory Motor On - Reverse Direction
11b = Not available";
CM_ BO_ 2566651134 "Electrified Accessory Power Electronics Coolant Fan 1 Status 1
Status data set 1 of electrified accessory: Power Electronics Coolant Fan 1.   See PGN 30720 for the corresponding command message.";
CM_ SG_ 2566651134 OperatingStatus "Indicates the operating status of the Power Electronics Coolant Fan 1 system or component.
This parameter is used to inform other devices that this system or component is no longer performing to its operational capacity and that reduced, or no ...";
CM_ SG_ 2566651134 ServiceInd "Indicates that service is required for the Power Electronics Coolant Fan 1 system or component.
An active indication may convey a need for component replacement or periodic service.  The Power Electronics Coolant Fan 1 Controller Status Reason Code ...";
CM_ SG_ 2566651134 Pwr "Calculated electrical power consumed by the Power Electronics Coolant Fan 1.";
CM_ SG_ 2566651134 CtrlTemp "A temperature measured and reported by the device.  It may be used for direct or remote (by another controller) control of the Fan 1.  For example, this may be the temperature of the fluid flowing through the Fan 1, or some other temperature ...";
CM_ SG_ 2566651134 MotorSpd "Motor Speed of the Power Electronics Coolant Fan 1.";
CM_ SG_ 2566651134 CtrlCmdStatus "Indicates the source of the speed command to the Power Electronics Coolant Fan 1 system or component.
00b is communicated when the controller is self-controlled  (e.g. based on a temperature sensor).
01b is communicated when responding to the ...";
CM_ SG_ 2566651134 CtrlStatusReasonCode "Provides the reason code describing the unique failure of the Power Electronics Coolant Fan 1 system or component.
If a detailed reason code is not used by the supporting application, or this reason code is Not Available, the Power Electronics ...";
CM_ SG_ 2566651134 EnableStatus "Enable and direction status of the Power Electronics Coolant Fan 1 system or component.

00b = Accessory Motor Off
01b = Accessory Motor On - Normal, Forward, or Default Direction
10b = Accessory Motor On - Reverse Direction
11b = Not available";
CM_ BO_ 2566650878 "Electrified Accessory Power Electronics Coolant Fan 2 Status 1
Status data set 1 of electrified accessory: Power Electronics Coolant Fan 2.   See PGN 30464 for the corresponding command message.";
CM_ SG_ 2566650878 OperatingStatus "Indicates the operating status of the Power Electronics Coolant Fan 2 system or component.
This parameter is used to inform other devices that this system or component is no longer performing to its operational capacity and that reduced, or no ...";
CM_ SG_ 2566650878 ServiceInd "Indicates that service is required for the Power Electronics Coolant Fan 2 system or component.
An active indication may convey a need for component replacement or periodic service.  The Power Electronics Coolant Fan 2 Controller Status Reason Code ...";
CM_ SG_ 2566650878 Pwr "Calculated electrical power consumed by the Power Electronics Coolant Fan 2.";
CM_ SG_ 2566650878 CtrlTemp "A temperature measured and reported by the device.  It may be used for direct or remote (by another controller) control of the Fan 2.  For example, this may be the temperature of the fluid flowing through the Fan 2, or some other temperature ...";
CM_ SG_ 2566650878 MotorSpd "Motor Speed of the Power Electronics Coolant Fan 2.";
CM_ SG_ 2566650878 CtrlCmdStatus "Indicates the source of the speed command to the Power Electronics Coolant Fan 2 system or component.
00b is communicated when the controller is self-controlled  (e.g. based on a temperature sensor).
01b is communicated when responding to the ...";
CM_ SG_ 2566650878 CtrlStatusReasonCode "Provides the reason code describing the unique failure of the Power Electronics Coolant Fan 2 system or component.
If a detailed reason code is not used by the supporting application, or this reason code is Not Available, the Power Electronics ...";
CM_ SG_ 2566650878 EnableStatus "Enable and direction status of the Power Electronics Coolant Fan 2 system or component.

00b = Accessory Motor Off
01b = Accessory Motor On - Normal, Forward, or Default Direction
10b = Accessory Motor On - Reverse Direction
11b = Not available";
CM_ BO_ 2566650622 "Electrified Accessory Power Electronics Coolant Fan 3 Status 1
Status data set 1 of electrified accessory: Power Electronics Coolant Fan 3.   See PGN 30208 for the corresponding command message.";
CM_ SG_ 2566650622 OperatingStatus "Indicates the operating status of the Power Electronics Coolant Fan 3 system or component.
This parameter is used to inform other devices that this system or component is no longer performing to its operational capacity and that reduced, or no ...";
CM_ SG_ 2566650622 ServiceInd "Indicates that service is required for the Power Electronics Coolant Fan 3 system or component.
An active indication may convey a need for component replacement or periodic service.  The Power Electronics Coolant Fan 3 Controller Status Reason Code ...";
CM_ SG_ 2566650622 Pwr "Calculated electrical power consumed by the Power Electronics Coolant Fan 3.";
CM_ SG_ 2566650622 CtrlTemp "A temperature measured and reported by the device.  It may be used for direct or remote (by another controller) control of the Fan 3.  For example, this may be the temperature of the fluid flowing through the Fan 3, or some other temperature ...";
CM_ SG_ 2566650622 MotorSpd "Motor Speed of the Power Electronics Coolant Fan 3.";
CM_ SG_ 2566650622 CtrlCmdStatus "Indicates the source of the speed command to the Power Electronics Coolant Fan 3 system or component.
00b is communicated when the controller is self-controlled  (e.g. based on a temperature sensor).
01b is communicated when responding to the ...";
CM_ SG_ 2566650622 CtrlStatusReasonCode "Provides the reason code describing the unique failure of the Power Electronics Coolant Fan 3 system or component.  If a detailed reason code is not used by the supporting application, or this reason code is Not Available, the Power Electronics ...";
CM_ SG_ 2566650622 EnableStatus "Enable and direction status of the Power Electronics Coolant Fan 3 system or component.

00b = Accessory Motor Off
01b = Accessory Motor On - Normal, Forward, or Default Direction
10b = Accessory Motor On - Reverse Direction
11b = Not available";
CM_ BO_ 2566650366 "Electrified Accessory Propulsion Motor Coolant Fan 1 Status 1
Status data set 1 of electrified accessory: Propulsion Motor Coolant Fan 1.   See PGN 29952 for the corresponding command message.";
CM_ SG_ 2566650366 OperatingStatus "Indicates the operating status of the Propulsion Motor Coolant Fan 1 system or component.
This parameter is used to inform other devices that this system or component is no longer performing to its operational capacity and that reduced, or no flow, ...";
CM_ SG_ 2566650366 ServiceInd "Indicates that service is required for the Propulsion Motor Coolant Fan 1 system or component.
An active indication may convey a need for component replacement or periodic service.  The Propulsion Motor Coolant Fan 1 Controller Status Reason Code ...";
CM_ SG_ 2566650366 Pwr "Calculated electrical power consumed by the Propulsion Motor Coolant Fan 1.";
CM_ SG_ 2566650366 CtrlTemp "A temperature measured and reported by the device.  It may be used for direct or remote (by another controller) control of the Fan 1.  For example, this may be the temperature of the fluid flowing through the Fan 1, or some other temperature ...";
CM_ SG_ 2566650366 MotorSpd "Motor Speed of the Propulsion Motor Coolant Fan 1.";
CM_ SG_ 2566650366 CtrlCmdStatus "Indicates the source of the speed command to the Propulsion Motor Coolant Fan 1 system or component.
00b is communicated when the controller is self-controlled  (e.g. based on a temperature sensor).
01b is communicated when responding to the ...";
CM_ SG_ 2566650366 CtrlStatusReasonCode "Provides the reason code describing the unique failure of the Propulsion Motor Coolant Fan 1 system or component.
If a detailed reason code is not used by the supporting application, or this reason code is Not Available, the Propulsion Motor ...";
CM_ SG_ 2566650366 EnableStatus "Enable and direction status of the Propulsion Motor Coolant Fan 1 system or component.

00b = Accessory Motor Off
01b = Accessory Motor On - Normal, Forward, or Default Direction
10b = Accessory Motor On - Reverse Direction
11b = Not available";
CM_ BO_ 2566650110 "Electrified Accessory Propulsion Motor Coolant Fan 2 Status 1
Status data set 1 of electrified accessory: Propulsion Motor Coolant Fan 2.   See PGN 29696 for the corresponding command message.";
CM_ SG_ 2566650110 OperatingStatus "Indicates the operating status of the Propulsion Motor Coolant Fan 2 system or component.
This parameter is used to inform other devices that this system or component is no longer performing to its operational capacity and that reduced, or no flow, ...";
CM_ SG_ 2566650110 ServiceInd "Indicates that service is required for the Propulsion Motor Coolant Fan 2 system or component.
An active indication may convey a need for component replacement or periodic service.  The Propulsion Motor Coolant Fan 2 Controller Status Reason Code ...";
CM_ SG_ 2566650110 Pwr "Calculated electrical power consumed by the Propulsion Motor Coolant Fan 2.";
CM_ SG_ 2566650110 CtrlTemp "A temperature measured and reported by the device.  It may be used for direct or remote (by another controller) control of the Fan 2.  For example, this may be the temperature of the fluid flowing through the Fan 2, or some other temperature ...";
CM_ SG_ 2566650110 MotorSpd "Motor Speed of the Propulsion Motor Coolant Fan 2.";
CM_ SG_ 2566650110 CtrlCmdStatus "Indicates the source of the speed command to the Propulsion Motor Coolant Fan 2 system or component.
00b is communicated when the controller is self-controlled  (e.g. based on a temperature sensor).
01b is communicated when responding to the ...";
CM_ SG_ 2566650110 CtrlStatusReasonCode "Provides the reason code describing the unique failure of the Propulsion Motor Coolant Fan 2 system or component.
If a detailed reason code is not used by the supporting application, or this reason code is Not Available, the Propulsion Motor ...";
CM_ SG_ 2566650110 EnableStatus "Enable and direction status of the Propulsion Motor Coolant Fan 2 system or component.

00b = Accessory Motor Off
01b = Accessory Motor On - Normal, Forward, or Default Direction
10b = Accessory Motor On - Reverse Direction
11b = Not available";
CM_ BO_ 2566649854 "Electrified Accessory Propulsion Motor Coolant Fan 3 Status 1
Status data set 1 of electrified accessory: Propulsion Motor Coolant Fan 3.   See PGN 29440 for the corresponding command message.";
CM_ SG_ 2566649854 OperatingStatus "Indicates the operating status of the Propulsion Motor Coolant Fan 3 system or component.
This parameter is used to inform other devices that this system or component is no longer performing to its operational capacity and that reduced, or no flow, ...";
CM_ SG_ 2566649854 ServiceInd "Indicates that service is required for the Propulsion Motor Coolant Fan 3 system or component.
An active indication may convey a need for component replacement or periodic service.  The Propulsion Motor Coolant Fan 3 Controller Status Reason Code ...";
CM_ SG_ 2566649854 Pwr "Calculated electrical power consumed by the Propulsion Motor Coolant Fan 3.";
CM_ SG_ 2566649854 CtrlTemp "A temperature measured and reported by the device.  It may be used for direct or remote (by another controller) control of the Fan 3.  For example, this may be the temperature of the fluid flowing through the Fan 3, or some other temperature ...";
CM_ SG_ 2566649854 MotorSpd "Motor Speed of the Propulsion Motor Coolant Fan 3.";
CM_ SG_ 2566649854 CtrlCmdStatus "Indicates the source of the speed command to the Propulsion Motor Coolant Fan 3 system or component.
00b is communicated when the controller is self-controlled  (e.g. based on a temperature sensor).
01b is communicated when responding to the ...";
CM_ SG_ 2566649854 CtrlStatusReasonCode "Provides the reason code describing the unique failure of the Propulsion Motor Coolant Fan 3 system or component.
If a detailed reason code is not used by the supporting application, or this reason code is Not Available, the Propulsion Motor ...";
CM_ SG_ 2566649854 EnableStatus "Enable and direction status of the Propulsion Motor Coolant Fan 3 system or component.

00b = Accessory Motor Off
01b = Accessory Motor On - Normal, Forward, or Default Direction
10b = Accessory Motor On - Reverse Direction
11b = Not available";
CM_ BO_ 2566649598 "Vehicle Position 2
Contains additional data that is provided by GPS antennas and systems and which is used by many vehicle applications including geofencing, vehicle tracking, predictive cruise control, et cetera. This data, combined with the VP1 ...";
CM_ SG_ 2566649598 TimeDilutionOfPrecision "Provides the estimated receiver clock error as calculated by the positioning and locating system receiver from the satellites’ clock data. The dilution of precision factor is calculated from the observed satellites (at least 4 must be tracked for ...";
CM_ SG_ 2566649598 DilutionOfPrecision "Provides the dilution of precision for the overall position (X-Y-Z coordinate system) as calculated by the positioning and locating system receiver. The dilution of precision factor is calculated from the observed satellites (at least 4 must be ...";
CM_ SG_ 2566649598 VerticalDilutionOfPrecision "Provides the dilution of precision in the vertical (Z axis) direction as calculated by the positioning and locating system receiver. The dilution of precision factor is calculated from the observed positions of the observed satellites (at least 4 ...";
CM_ SG_ 2566649598 HorizontalDilutionOfPrecision "Provides the dilution of precision in the horizontal (X-Y plane axis) direction as calculated by the positioning and locating system receiver. The dilution of precision factor is calculated from the observed positions of the observed satellites (at ...";
CM_ SG_ 2566649598 TotalNumOfSatellitesInView "Indicates the number of satellites in view of the positioning and locating system receiver.";
CM_ BO_ 2566649342 "Aftertreatment 1 Diesel Oxidation Catalyst 2
The purpose of this PG is to group the aftertreatment diesel oxidation catalyst data for bank 1. These values include the intake temperature, outlet temperature and differential pressure as well as the ...";
CM_ SG_ 2566649342 DOCInToDPFOutDeltaPress "Aftertreatment 1 Diesel Oxidation Catalyst intake to Diesel Particulate Filter outlet differential pressure in exhaust bank 1.";
CM_ SG_ 2566649342 OutPress "Aftertreatment 1 Diesel Oxidation Catalyst absolute pressure measured at the DOC outlet in exhaust bank 1.";
CM_ SG_ 2566649342 InPress "Aftertreatment 1 Diesel Oxidation Catalyst absolute pressure measured at the DOC intake in exhaust bank 1.";
CM_ BO_ 2566649086 "Aftertreatment 2 Diesel Oxidation Catalyst 2
The purpose of this PG is to group the aftertreatment diesel oxidation catalyst data for bank 2. These values include the intake temperature, outlet temperature and differential pressure as well as the ...";
CM_ SG_ 2566649086 DOCInToDPFOutDeltaPress "Aftertreatment 2 Diesel Oxidation Catalyst intake to Diesel Particulate Filter outlet differential pressure in exhaust bank 1.";
CM_ SG_ 2566649086 OutPress "Aftertreatment 2 Diesel Oxidation Catalyst absolute pressure measured at the DOC outlet in exhaust bank 1.";
CM_ SG_ 2566649086 InPress "Aftertreatment 2 Diesel Oxidation Catalyst absolute pressure measured at the DOC intake in exhaust bank 1.";
CM_ BO_ 2365322238 "Cruise Control / Vehicle Speed 5
Cruise Control / Vehicle Speed 5";
CM_ SG_ 2365322238 DirVS "The velocity and direction of the vehicle. Positive values are used for forward vehicle motion, negative values for reverse vehicle motion.  This SP is intended for control purposes where vehicle direction is required.  It is not intended to replace ...";
CM_ BO_ 2566648318 "Oil Debris Monitoring System Status
Reports the status of an oil debris sensor within the Oil Debris Monitoring (ODM) system.
NOTE – Multiple instances of this message will be required to transmit data for all of the ODM Sensors. When reporting ...";
CM_ SG_ 2566648318 MonitorETempStatus "Temperature indicator for the Oil Debris Monitor (ODM) Electronics.

00b = Acceptable temperature
01b = Temperature is outside of limits
10b = Reserved
11b = Not available";
CM_ SG_ 2566648318 MonitorSPEStatus "Status of the Oil Debris Monitor (ODM) signal processing electronics.

00b = Electronics functioning normally
01b = Fault in electronics
10b = Reserved
11b = Not available";
CM_ SG_ 2566648318 MonitorSensingElementStatus "Status of the Oil Debris Monitor (ODM) sensing element.

00b = Sensing element OK
01b = Fault with sensing element
10b = Reserved
11b = Not available";
CM_ SG_ 2566648318 MonitorEnvironmentStatus "Status of the electrical and mechanical environment surrounding the Oil Debris Monitor (ODM) Sensor.

00b = Acceptable environment
01b = Excessive noise in signal
10b = Reserved
11b = Not available";
CM_ SG_ 2566648318 MonitorTotalNumOfSensors "Total number of Oil Debris Monitoring (ODM) sensors configured for this application.";
CM_ SG_ 2566648318 MonitorStatusIdNum "Identification number of the Oil Debris Monitoring (ODM) sensor being reported. Identification numbers are application specific.";
CM_ BO_ 2566648062 "Oil Debris Monitor Counts Non-Ferrous Bins 5 & 6
Reports the Oil Debris Monitor counts in non-ferrous bins 5 & 6 measured by one oil debris sensor within the Oil Debris Monitoring (ODM) system.
In oil debris monitoring, bins are count accumulators ...";
CM_ SG_ 2566648062 NFBin6Count "Total number of particles detected in Non-Ferrous bin 6. Bin sizes are application specific.";
CM_ SG_ 2566648062 NFBin5Count "Total number of particles detected in Non-Ferrous bin 5. Bin sizes are application specific.";
CM_ SG_ 2566648062 NFBins5And6IdNum "Identification number of the Oil Debris Monitoring (ODM) sensor being reported for Non-Ferrous bins 5 and 6. Identification numbers are application specific.";
CM_ BO_ 2566647806 "Oil Debris Monitor Counts Non-Ferrous Bins 3 & 4
Reports the Oil Debris Monitor counts in non-ferrous bins 3 & 4 measured by one oil debris sensor within the Oil Debris Monitoring (ODM) system.
In oil debris monitoring, bins are count accumulators ...";
CM_ SG_ 2566647806 NFBin4Count "Total number of particles detected in Non-Ferrous bin 4. Bin sizes are application specific.";
CM_ SG_ 2566647806 NFBin3Count "Total number of particles detected in Non-Ferrous bin 3. Bin sizes are application specific.";
CM_ SG_ 2566647806 NFBins3And4IdNum "Identification number of the Oil Debris Monitoring (ODM) sensor being reported for Non-Ferrous bins 3 and 4. Identification numbers are application specific.";
CM_ BO_ 2566647550 "Oil Debris Monitor Counts Non-Ferrous Bins 1 & 2
Reports the Oil Debris Monitor counts in non-ferrous bins 1 & 2 measured by one oil debris sensor within the Oil Debris Monitoring (ODM) system.
In oil debris monitoring, bins are count accumulators ...";
CM_ SG_ 2566647550 NFBin2Count "Total number of particles detected in Non-Ferrous bin 2. Bin sizes are application specific.";
CM_ SG_ 2566647550 NFBin1Count "Total number of particles detected in Non-Ferrous bin 1. Bin sizes are application specific.";
CM_ SG_ 2566647550 NFBins1And2IdNum "Identification number of the Oil Debris Monitoring (ODM) sensor being reported for Non-Ferrous bins 1 and 2.  Identification numbers are application specific.";
CM_ BO_ 2566647294 "Oil Debris Monitor Counts Ferrous Bins 5 & 6
Reports the Oil Debris Monitor counts in ferrous bins 5 & 6 measured by one oil debris sensor within the Oil Debris Monitoring (ODM) system.
In oil debris monitoring, bins are count accumulators for the ...";
CM_ SG_ 2566647294 FBin6Count "Total number of particles detected in Ferrous bin 6. Bin sizes are application specific.";
CM_ SG_ 2566647294 FBin5Count "Total number of particles detected in Ferrous bin 5. Bin sizes are application specific.";
CM_ SG_ 2566647294 FBins5And6IdNum "Identification number of the Oil Debris Monitoring (ODM) sensor being reported for Ferrous bins 5 and 6. Identification numbers are application specific.";
CM_ BO_ 2566647038 "Oil Debris Monitor Counts Ferrous Bins 3 & 4
Reports the Oil Debris Monitor counts in ferrous bins 3 & 4 measured by one oil debris sensor within the Oil Debris Monitoring (ODM) system.
In oil debris monitoring, bins are count accumulators for the ...";
CM_ SG_ 2566647038 FBin4Count "Total number of particles detected in Ferrous bin 4. Bin sizes are application specific.";
CM_ SG_ 2566647038 FBin3Count "Total number of particles detected in Ferrous bin 3. Bin sizes are application specific.";
CM_ SG_ 2566647038 FBins3And4IdNum "Identification number of the Oil Debris Monitoring (ODM) sensor being reported for Ferrous bins 3 and 4. Identification numbers are application specific.";
CM_ BO_ 2566646782 "Oil Debris Monitor Counts Ferrous Bins 1 & 2
Reports the Oil Debris Monitor counts in ferrous bins 1 & 2 measured by one oil debris sensor within the Oil Debris Monitoring (ODM) system.
In oil debris monitoring, bins are count accumulators for the ...";
CM_ SG_ 2566646782 FBin2Count "Total number of particles detected in Ferrous bin 2. Bin sizes are application specific.";
CM_ SG_ 2566646782 FBin1Count "Total number of particles detected in Ferrous bin 1. Bin sizes are application specific.";
CM_ SG_ 2566646782 FBins1And2IdNum "Identification number of the Oil Debris Monitoring (ODM) sensor being reported for Ferrous bins 1 and 2. Identification numbers are application specific.";
CM_ BO_ 2633755390 "Ethernet 1 Connection Information 1
Includes information helpful to facilitate connecting to the sending ECU via the first instance of an embedded Ethernet link.

As a minimum, the first 19 bytes are expected to be broadcast.";
CM_ SG_ 2633755390 MACAddressOctet6 "This value is the sixth of 6 octets in the ECU's assigned MAC address. The address is separated into 6 bytes, 1 per octet of the address. Byte 1 is the first octet of the address. Byte 2 is the second and so forth. If the MAC address is not ...";
CM_ SG_ 2633755390 MACAddressOctet5 "This value is the fifth of 6 octets in the ECU's assigned MAC address. The address is separated into 6 bytes, 1 per octet of the address. Byte 1 is the first octet of the address. Byte 2 is the second and so forth. If the MAC address is not ...";
CM_ SG_ 2633755390 MACAddressOctet4 "This value is the fourth of 6 octets in the ECU's assigned MAC address. The address is separated into 6 bytes, 1 per octet of the address. Byte 1 is the first octet of the address. Byte 2 is the second and so forth. If the MAC address is not ...";
CM_ SG_ 2633755390 MACAddressOctet3 "This value is the third of 6 octets in the ECU's assigned MAC address. The address is separated into 6 bytes, 1 per octet of the address. Byte 1 is the first octet of the address. Byte 2 is the second and so forth. If the MAC address is not ...";
CM_ SG_ 2633755390 MACAddressOctet2 "This value is the second of 6 octets in the ECU's assigned MAC address. The address is separated into 6 bytes, 1 per octet of the address. Byte 1 is the first octet of the address. Byte 2 is the second and so forth. If the MAC address is not ...";
CM_ SG_ 2633755390 MACAddressOctet1 "This value is the first of 6 octets in the ECU's assigned MAC address. The address is separated into 6 bytes, 1 per octet of the address. Byte 1 is the first octet of the address. Byte 2 is the second and so forth. If the MAC address is not ...";
CM_ SG_ 2633755390 DefaultGatewayOctet4 "This value is the fourth of 4 octets in the ECU's configured or assigned Default Gateway IP address.  The Default Gateway IP address is separated into 4 bytes, 1 per octet of the address Byte 1 is the first octet of the address Byte 2 is the second ...";
CM_ SG_ 2633755390 DefaultGatewayOctet3 "This value is the third of 4 octets in the ECU's configured or assigned Default Gateway IP address.  The Default Gateway IP address is separated into 4 bytes, 1 per octet of the address Byte 1 is the first octet of the address Byte 2 is the second ...";
CM_ SG_ 2633755390 DefaultGatewayOctet2 "This value is the second of 4 octets in the ECU's configured or assigned Default Gateway IP address.  The Default Gateway IP address is separated into 4 bytes, 1 per octet of the address Byte 1 is the first octet of the address Byte 2 is the second ...";
CM_ SG_ 2633755390 DefaultGatewayOctet1 "This value is the first of 4 octets in the ECU's configured or assigned Default Gateway IP address.  The Default Gateway IP address is separated into 4 bytes, 1 per octet of the address Byte 1 is the first octet of the address Byte 2 is the second ...";
CM_ SG_ 2633755390 SubnetMaskOctet4 "This value is the fourth of 4 octets in the ECU's configured Subnet mask. The subnet mask is separated into 4 bytes, 1 per octet of the mask. Byte 1 is the first octet of the mask. Byte 2 is the second and so forth. If the Subnet mask is not ...";
CM_ SG_ 2633755390 SubnetMaskOctet3 "This value is the third of 4 octets in the ECU's configured Subnet mask. The subnet mask is separated into 4 bytes, 1 per octet of the mask. Byte 1 is the first octet of the mask. Byte 2 is the second and so forth. If the Subnet mask is not ...";
CM_ SG_ 2633755390 SubnetMaskOctet2 "This value is the second of 4 octets in the ECU's configured Subnet mask. The subnet mask is separated into 4 bytes, 1 per octet of the mask. Byte 1 is the first octet of the mask. Byte 2 is the second and so forth. If the Subnet mask is not ...";
CM_ SG_ 2633755390 SubnetMaskOctet1 "This value is the first of 4 octets in the ECU's configured Subnet mask. The subnet mask is separated into 4 bytes, 1 per octet of the mask. Byte 1 is the first octet of the mask. Byte 2 is the second and so forth. If the Subnet mask is not ...";
CM_ SG_ 2633755390 IPv4AddressOctet4 "This value is the fourth of 4 octets in the ECU's assigned Internet Protocol (IP) address. The address is separated into 4 bytes, 1 per octet of the address. Byte 1 is the first octet of the address. Byte 2 is the second and so forth. If the IP ...";
CM_ SG_ 2633755390 IPv4AddressOctet3 "This value is the third of 4 octets in the ECU's assigned Internet Protocol (IP) address. The address is separated into 4 bytes, 1 per octet of the address. Byte 1 is the first octet of the address. Byte 2 is the second and so forth. If the IP ...";
CM_ SG_ 2633755390 IPv4AddressOctet2 "This value is the second of 4 octets in the ECU's assigned Internet Protocol (IP) address. The address is separated into 4 bytes, 1 per octet of the address. Byte 1 is the first octet of the address. Byte 2 is the second and so forth. If the IP ...";
CM_ SG_ 2633755390 IPv4AddressOctet1 "This value is the first of 4 octets in the ECU's assigned Internet Protocol (IP) address. The address is separated into 4 bytes, 1 per octet of the address. Byte 1 is the first octet of the address. Byte 2 is the second and so forth. If the IP ...";
CM_ SG_ 2633755390 LinkStatus "Ethernet Link Status. When there is no physical connection, the status shall report 00. 

00b = Ethernet Link Down
01b = Ethernet Link Up
10b = Error
11b = Not Supported";
CM_ SG_ 2633755390 DHCPStatus "DHCP Client Status. This parameter is intended to provide feedback on the status of obtaining an IP address. When no physical link is available and DHCP is enabled, an Error response is appropriate.
0000b = Not Configured (static IP)
0001b = ...";
CM_ BO_ 2633755134 "Ethernet 1 Connection Information 2
Provides the Host Name used by the sending ECU of the first instance of an embedded Ethernet link. This information can be used to aid locating the ECU on a network.";
CM_ SG_ 2633755134 HostName "The Host Name of the sending ECU for its embedded Ethernet port.  Host Names can be up to 63 characters in length.";
CM_ BO_ 2633754878 "Aftertreatment System Information 2
The state of the aftertreatment system.";
CM_ SG_ 2633754878 HCDoserDutyCycle "The commanded relative postion of the proportioning valve in the Hydrocarbon (HC) Doser System controlling the delivery of fuel to the aftertreatment system.  This SP does not apply to system designs that employ shuttle valves to meter fuel ...";
CM_ SG_ 2633754878 OneDEFDosingMode "The present operating state of the DEF doser for aftertreatment 1 (exhaust bank 1) as described by the appropriate regulatory body with the manufacturer.
00h = Off, not dosing
01h - FAh = Manufacturer Defined, assign from 1 up or from 250 down.
 ...";
CM_ SG_ 2633754878 DEFUsedThisOperatingCycle "Total amount of DEF used by aftertreatment device 1 and aftertreatment device 2 over the current operating cycle (from engine start to engine start).
Notes:
See SPNs 5963 and 5964 for individual lifetime accumulation.
See SPNs 21225 ...";
CM_ SG_ 2633754878 TotalDEFUsed "Total amount of DEF used by aftertreatment device 1 and aftertreatment device 2 over the lifetime of the system.

See SPNs 5963 and 5964 for individual device accumulation.";
CM_ BO_ 2633754622 "SCR Operator Inducement Information 5
Contains parameters that are related to SCR inducement.";
CM_ SG_ 2633754622 EmergOvrdTotalActivationTime "The total time duration the SCR Operator Inducement Override Mode (SPN 7342) has been active.

Note:  Euro Stage V states this timer can not be reset.";
CM_ SG_ 2633754622 A1SCRInHiTempTime "Indicates the time the aftertreatment 1 SCR intake temperature is above a manufacturer specified threshold. This is the temperature of engine combustion byproducts entering the SCR in exhaust bank 1. This will accumulate over the life of the product ...";
CM_ BO_ 2365318910 "High Voltage Energy Storage System Fan Commands
Commands to 1 or more fans in an HVES system.  See PGN 64485 for the corresponding feedback message.
This command may be used to control fans in (a) individual, stand-alone packs, (b) packs that are ...";
CM_ SG_ 2365318910 HVESFanInstance15 "Indicates the HVES Fan Instance that is being commanded.  Multiple instances can be controlled with the same command PG by setting each unique instance parameter to 0b.
0b = Command applied to this Fan Instance
1b = No Command applied to this Fan ...";
CM_ SG_ 2365318910 HVESFanInstance14 "Indicates the HVES Fan Instance that is being commanded.  Multiple instances can be controlled with the same command PG by setting each unique instance parameter to 0b.
0b = Command applied to this Fan Instance
1b = No Command applied to this Fan ...";
CM_ SG_ 2365318910 HVESFanInstance13 "Indicates the HVES Fan Instance that is being commanded.  Multiple instances can be controlled with the same command PG by setting each unique instance parameter to 0b.
0b = Command applied to this Fan Instance
1b = No Command applied to this Fan ...";
CM_ SG_ 2365318910 HVESFanInstance12 "Indicates the HVES Fan Instance that is being commanded.  Multiple instances can be controlled with the same command PG by setting each unique instance parameter to 0b.
0b = Command applied to this Fan Instance
1b = No Command applied to this Fan ...";
CM_ SG_ 2365318910 HVESFanInstance11 "Indicates the HVES Fan Instance that is being commanded.  Multiple instances can be controlled with the same command PG by setting each unique instance parameter to 0b.
0b = Command applied to this Fan Instance
1b = No Command applied to this Fan ...";
CM_ SG_ 2365318910 HVESFanInstance10 "Indicates the HVES Fan Instance that is being commanded.  Multiple instances can be controlled with the same command PG by setting each unique instance parameter to 0b.
0b = Command applied to this Fan Instance
1b = No Command applied to this Fan ...";
CM_ SG_ 2365318910 HVESFanInstance9 "Indicates the HVES Fan Instance that is being commanded.  Multiple instances can be controlled with the same command PG by setting each unique instance parameter to 0b.
0b = Command applied to this Fan Instance
1b = No Command applied to this Fan ...";
CM_ SG_ 2365318910 HVESFanInstance8 "Indicates the HVES Fan Instance that is being commanded.  Multiple instances can be controlled with the same command PG by setting each unique instance parameter to 0b.
0b = Command applied to this Fan Instance
1b = No Command applied to this Fan ...";
CM_ SG_ 2365318910 HVESFanInstance7 "Indicates the HVES Fan Instance that is being commanded.  Multiple instances can be controlled with the same command PG by setting each unique instance parameter to 0b.
0b = Command applied to this Fan Instance
1b = No Command applied to this Fan ...";
CM_ SG_ 2365318910 HVESFanInstance6 "Indicates the HVES Fan Instance that is being commanded.  Multiple instances can be controlled with the same command PG by setting each unique instance parameter to 0b.
0b = Command applied to this Fan Instance
1b = No Command applied to this Fan ...";
CM_ SG_ 2365318910 HVESFanInstance5 "Indicates the HVES Fan Instance that is being commanded.  Multiple instances can be controlled with the same command PG by setting each unique instance parameter to 0b.
0b = Command applied to this Fan Instance
1b = No Command applied to this Fan ...";
CM_ SG_ 2365318910 HVESFanInstance4 "Indicates the HVES Fan Instance that is being commanded.  Multiple instances can be controlled with the same command PG by setting each unique instance parameter to 0b.
0b = Command applied to this Fan Instance
1b = No Command applied to this Fan ...";
CM_ SG_ 2365318910 HVESFanInstance3 "Indicates the HVES Fan Instance that is being commanded.  Multiple instances can be controlled with the same command PG by setting each unique instance parameter to 0b.
0b = Command applied to this Fan Instance
1b = No Command applied to this Fan ...";
CM_ SG_ 2365318910 HVESFanInstance2 "Indicates the HVES Fan Instance that is being commanded.  Multiple instances can be controlled with the same command PG by setting each unique instance parameter to 0b.
0b = Command applied to this Fan Instance
1b = No Command applied to this Fan ...";
CM_ SG_ 2365318910 HVESFanInstance1 "Indicates the HVES Fan Instance that is being commanded.  Multiple instances can be controlled with the same command PG by setting each unique instance parameter to 0b.
0b = Command applied to this Fan Instance
1b = No Command applied to this Fan ...";
CM_ SG_ 2365318910 HVESFanPercentSpdCmd "Speed command to this HVES fan in percentage of maximum speed.
Note: Both SPN 8386 (HVESS Fan Speed Command) and SPN 8387 (HVESS Fan Percent Speed Command) cannot be used at the same time.  Always set the unused speed command to Not Available.  If ...";
CM_ SG_ 2365318910 HVESFanSpdCmd "Speed command to this HVES fan.
Note: Both SPN 8386 (HVESS Fan Speed Command) and SPN 8387 (HVESS Fan Percent Speed Command) cannot be used at the same time.  Always set the unused speed command to Not Available.  If both commands are set to Not ...";
CM_ SG_ 2365318910 HVESFanPwrHold "Command to allow this HVES fan to remain alive independently of the electrical enable input to the fan.  For example, this could allow continued device operation after the keyswitch has turned off.
00b = Power Hold Disabled
01b = Power Hold ...";
CM_ SG_ 2365318910 HVESFanEnableCmd "Enable and direction command to this HVES fan.

00b = Fan Off
01b = Fan On Normal/Default Direction
10b = Fan On Reverse Direction
11b = Don't Care/Take no action";
CM_ BO_ 2566645246 "High Voltage Energy Storage System Fan Status
The status of HVES fan(s).   See PGN 64486 for the corresponding command message.
If a single controller application broadcasts multiple instances of this message, a 10ms spacing between broadcasts of ...";
CM_ SG_ 2566645246 HVESFanInstance "Indicates the instance of the HVES fan that is providing status in systems controlled by a master ECU.
0000b = Instance 1
0001b = Instance 2
0010b = Instance 3
0011b = Instance 4
0100b = Instance 5
0101b = Instance 6
0110b = Instance 7
0111b ...";
CM_ SG_ 2566645246 HVESFanOperatingStatus "Indicates the operating status of this HVES fan.  This parameter is used to inform other devices that this system or component is no longer performing to its operational capacity and that reduced, or no flow of the medium (e.g. coolant, oil, air, ...";
CM_ SG_ 2566645246 HVESFanServiceInd "Indicates that service is required for this HVES fan.  An active indication may convey a need for component replacement or periodic service.  SPN 8404 (HVESS Fan Status Reason Code) may provide additional detail as to the nature of the system ...";
CM_ SG_ 2566645246 HVESFanPwr "Calculated electrical power consumed by this HVES fan.";
CM_ SG_ 2566645246 HVESFanMediumTemp "A temperature measured and reported by the device.  It may be used for direct or remote (e.g. by another controller) control of the pump.  For example, this may be the temperature of the fluid flowing through the pump, or some other temperature ...";
CM_ SG_ 2566645246 HVESFanSpd "Speed of this HVES fan.";
CM_ SG_ 2566645246 HVESFanCmdStatus "Indicates the source of the speed command to this HVES fan.
00b is communicated when the fan is self-controlled (e.g. based on a temperature sensor).  01b is communicated when responding to SPN 8386  (HVESS Fan Speed Command) or SPN 8387 (HVESS Fan ...";
CM_ SG_ 2566645246 HVESFanStatusReasonCode "Provides the reason code describing the unique failure of this HVES fan.  If a detailed reason code is not used by the supporting application, or this reason code is Not Available, the SPN 8409 (HVESS Fan Service Indicator) and SPN 8410 (HVESS fan ...";
CM_ SG_ 2566645246 HVESFanEnableStatus "Enable and direction status of this HVES fan.

00b = Fan Off
01b = Fan On - Normal, Forward, or Default Direction
10b = Fan On - Reverse Direction
11b = Not available";
CM_ BO_ 2566644990 "Fuel Information 7 (Gaseous)
Gaseous fuel information 7";
CM_ SG_ 2566644990 StorageCompartment3Temp2 "The ambient temperature as measured by the second temperature sensor in the third fuel storage compartment. Note that this is not the temperature of the fuel in the fuel tank.";
CM_ SG_ 2566644990 StorageCompartment3Temp1 "The ambient temperature in the third fuel storage compartment.  If there is more than 1 sensor, then this is the first sensor. Note that this is not the temperature of the fuel in the fuel tank.";
CM_ SG_ 2566644990 StorageCompartment2Temp2 "The ambient temperature as measured by the second temperature sensor in the second fuel storage compartment. Note that this is not the temperature of the fuel in the fuel tank.";
CM_ SG_ 2566644990 StorageCompartment2Temp1 "The ambient temperature in the second fuel storage compartment.  If there is more than 1 sensor, then this is the first sensor. Note that this is not the temperature of the fuel in the fuel tank.";
CM_ SG_ 2566644990 StorageCompartment1Temp2 "The ambient temperature as measured by the second temperature sensor in the first fuel storage compartment. Note that this is not the temperature of the fuel in the fuel tank.";
CM_ SG_ 2566644990 StorageCompartment1Temp1 "The ambient temperature in the first fuel storage compartment.  If there is more than 1 sensor, then this is the first sensor. Note that this is not the temperature of the fuel in the fuel tank.";
CM_ SG_ 2566644990 FrontFuelRecpCoverStatus "Indicates if the cover for the fuel receptacle at the front of the vehicle is attached or detached.

00b = Receptacle cover is detached
01b = Receptacle cover is attached
10b = Error
11b = Not available";
CM_ SG_ 2566644990 PsgrSideFuelRecp2CoverStatus "Indicates if the cover for the second fuel receptacle on the passenger side is attached or detached.

00b = Receptacle cover is detached
01b = Receptacle cover is attached
10b = Error
11b = Not available";
CM_ SG_ 2566644990 PsgrSideFuelRecp1CoverStatus "Indicates if the cover for the first fuel receptacle on the passenger side is attached or detached.

00b = Receptacle cover is detached
01b = Receptacle cover is attached
10b = Error
11b = Not available";
CM_ SG_ 2566644990 DriverSideFuelRecp2CoverStatus "Indicates if the cover for the second fuel receptacle on the driver side is attached or detached.

00b = Receptacle cover is detached
01b = Receptacle cover is attached
10b = Error
11b = Not available";
CM_ SG_ 2566644990 DriverSideFuelRecp1CoverStatus "Indicates if the cover for the first fuel receptacle on the driver side is attached or detached.

00b = Receptacle cover is detached
01b = Receptacle cover is attached
10b = Error
11b = Not available";
CM_ BO_ 2633753598 "Alternator Temperature 2
Temperature of the alternator windings";
CM_ SG_ 2633753598 ACAirOutTemp "Temperature of air after it exits from the air cooler in an alternator.";
CM_ SG_ 2633753598 ACAirInTemp "Temperature of air entering the air cooler in an alternator";
CM_ SG_ 2633753598 EngAltWinding12Temp "Temperature of this winding inside the alternator.";
CM_ SG_ 2633753598 EngAltWinding11Temp "Temperature of this winding inside the alternator.";
CM_ SG_ 2633753598 EngAltWinding10Temp "Temperature of this winding inside the alternator.";
CM_ SG_ 2633753598 EngAltWinding9Temp "Temperature of this winding inside the alternator.";
CM_ SG_ 2633753598 EngAltWinding8Temp "Temperature of this winding inside the alternator.";
CM_ SG_ 2633753598 EngAltWinding7Temp "Temperature of this winding inside the alternator.";
CM_ BO_ 2633753342 "Diode Temperature 1
Temperature of the diodes in a power rectifier.";
CM_ SG_ 2633753342 PwrRectifierDiode8Temp "Temperature of this diode used in power rectifier.";
CM_ SG_ 2633753342 PwrRectifierDiode7Temp "Temperature of this diode used in power rectifier.";
CM_ SG_ 2633753342 PwrRectifierDiode6Temp "Temperature of this diode used in power rectifier.";
CM_ SG_ 2633753342 PwrRectifierDiode5Temp "Temperature of this diode used in power rectifier.";
CM_ SG_ 2633753342 PwrRectifierDiode4Temp "Temperature of this diode used in power rectifier.";
CM_ SG_ 2633753342 PwrRectifierDiode3Temp "Temperature of this diode used in power rectifier.";
CM_ SG_ 2633753342 PwrRectifierDiode2Temp "Temperature of this diode used in power rectifier.";
CM_ SG_ 2633753342 PwrRectifierDiode1Temp "Temperature of this diode used in power rectifier.";
CM_ BO_ 2633753086 "Diode Temperature 2
Temperature of the diodes in a power rectifier.";
CM_ SG_ 2633753086 PwrRectifierDiode12Temp "Temperature of this diode used in power rectifier.";
CM_ SG_ 2633753086 PwrRectifierDiode11Temp "Temperature of this diode used in power rectifier.";
CM_ SG_ 2633753086 PwrRectifierDiode10Temp "Temperature of this diode used in power rectifier.";
CM_ SG_ 2633753086 PwrRectifierDiode9Temp "Temperature of this diode used in power rectifier.";
CM_ BO_ 2633752830 "Aftercooler and Oil Cooler Fluids 1
Temperature and pressures for the aftercooler and oil cooler.";
CM_ SG_ 2633752830 AltAftercoolerCPOutPress "Pressure of liquid at the aftercooler pump outlet";
CM_ SG_ 2633752830 AltAftercoolerCoolantOutTemp "Temperature of liquid at the aftercooler outlet.";
CM_ SG_ 2633752830 AltAftercoolerCPOutTemp "Temperature of liquid at the aftercooler coolant pump outlet.";
CM_ SG_ 2633752830 EngOilCoolerCoolantOutTemp "Temperature of liquid after it exits the engine oil cooler.";
CM_ SG_ 2633752830 AltOilCoolerCoolantOutTemp "Temperature of liquid after it exits the oil cooler of an alternator.";
CM_ SG_ 2633752830 AltOilCoolerCoolantInTemp "Temperature of liquid as it enters the oil cooler of an alternator.";
CM_ SG_ 2633752830 AltOilCoolerOilOutTemp "Temperature of lubricant after it exits the oil cooler of an alternator.";
CM_ SG_ 2633752830 AltOilCoolerOilInTemp "Temperature of lubricant as it enters the oil cooler of an alternator.";
CM_ BO_ 2566643710 "Intake/Exhaust Conditions 3
Intake/Exhaust Conditions 3 is a second PG conveying this type of engine information. Also see PGNs 64976 and 65270.";
CM_ SG_ 2566643710 DesEngInManifoldPressHiLmt "The desired pressure high limit of the air intake manifold. This SP is a high resolution measurement.";
CM_ SG_ 2566643710 EngInManifold2AbsPress "The absolute pressure measurement of the air intake manifold for bank 2 or the second air intake manifold.  If there are multiple air pressure sensors in the intake stream, this is the last one in flow direction before entering the combustion ...";
CM_ SG_ 2566643710 EngMixer2InPress "The pressure at the intake of the second air and fuel mixer.";
CM_ SG_ 2566643710 EngMixer1InPress "The pressure at the intake of the air and fuel mixer.";
CM_ BO_ 2566643454 "Engine Temperature 6
Engine related parameters";
CM_ SG_ 2566643454 DiffTemp "Indicates the differential temperature between the engine intake manifold air to secondary coolant circuit coolant.";
CM_ SG_ 2566643454 InCoolantTemp "Temperature of the coolant at the intake of the engine block.";
CM_ SG_ 2566643454 ChargeACOutCoolantTemp "Temperature of the fluid in the low temperature circuit measured at the fluid outlet of the charge air cooler.";
CM_ SG_ 2566643454 ChargeACInCoolantTemp "Temperature of the fluid in the low temperature circuit measured at the fluid intake of the charge air cooler.";
CM_ BO_ 2566643198 "Door Control 3
Used for door information.";
CM_ SG_ 2566643198 EnableStatusOfDoor20 "Enable status of bus door 20.  Enabled means the bus doors are able to be automatically opened or closed.

00b = Door disabled
01b = Door enabled
10b = Error
11b = Not available";
CM_ SG_ 2566643198 OpenStatusOfDoor20 "Open status of bus door 20

00b = Door closed
01b = Door opened
10b = Error
11b = Not available";
CM_ SG_ 2566643198 LockStatusOfDoor20 "Lock status of bus door 20

00b = Unlocked
01b = Locked
10b = Error
11b = Not available";
CM_ SG_ 2566643198 EnableStatusOfDoor19 "Enable status of bus door 19.  Enabled means the bus doors are able to be automatically opened or closed.

00b = Door disabled
01b = Door enabled
10b = Error
11b = Not available";
CM_ SG_ 2566643198 OpenStatusOfDoor19 "Open status of bus door 19

00b = Door closed
01b = Door opened
10b = Error
11b = Not available";
CM_ SG_ 2566643198 LockStatusOfDoor19 "Lock status of bus door 19

00b = Unlocked
01b = Locked
10b = Error
11b = Not available";
CM_ SG_ 2566643198 EnableStatusOfDoor18 "Enable status of bus door 18.  Enabled means the bus doors are able to be automatically opened or closed.

00b = Door disabled
01b = Door enabled
10b = Error
11b = Not available";
CM_ SG_ 2566643198 OpenStatusOfDoor18 "Open status of bus door 18

00b = Door closed
01b = Door opened
10b = Error
11b = Not available";
CM_ SG_ 2566643198 LockStatusOfDoor18 "Lock status of bus door 18

00b = Unlocked
01b = Locked
10b = Error
11b = Not available";
CM_ SG_ 2566643198 EnableStatusOfDoor17 "Enable status of bus door 17.  Enabled means the bus doors are able to be automatically opened or closed.

00b = Door disabled
01b = Door enabled
10b = Error
11b = Not available";
CM_ SG_ 2566643198 OpenStatusOfDoor17 "Open status of bus door 17

00b = Door closed
01b = Door opened
10b = Error
11b = Not available";
CM_ SG_ 2566643198 LockStatusOfDoor17 "Lock status of bus door 17

00b = Unlocked
01b = Locked
10b = Error
11b = Not available";
CM_ SG_ 2566643198 EnableStatusOfDoor16 "Enable status of bus door 16.  Enabled means the bus doors are able to be automatically opened or closed.

00b = Door disabled
01b = Door enabled
10b = Error
11b = Not available";
CM_ SG_ 2566643198 OpenStatusOfDoor16 "Open status of bus door 16

00b = Door closed
01b = Door opened
10b = Error
11b = Not available";
CM_ SG_ 2566643198 LockStatusOfDoor16 "Lock status of bus door 16

00b = Unlocked
01b = Locked
10b = Error
11b = Not available";
CM_ SG_ 2566643198 EnableStatusOfDoor15 "Enable status of bus door 15.  Enabled means the bus doors are able to be automatically opened or closed.

00b = Door disabled
01b = Door enabled
10b = Error
11b = Not available";
CM_ SG_ 2566643198 OpenStatusOfDoor15 "Open status of bus door 15

00b = Door closed
01b = Door opened
10b = Error
11b = Not available";
CM_ SG_ 2566643198 LockStatusOfDoor15 "Lock status of bus door 15

00b = Unlocked
01b = Locked
10b = Error
11b = Not available";
CM_ SG_ 2566643198 EnableStatusOfDoor14 "Enable status of bus door 14.  Enabled means the bus doors are able to be automatically opened or closed.

00b = Door disabled
01b = Door enabled
10b = Error
11b = Not available";
CM_ SG_ 2566643198 OpenStatusOfDoor14 "Open status of bus door 14

00b = Door closed
01b = Door opened
10b = Error
11b = Not available";
CM_ SG_ 2566643198 LockStatusOfDoor14 "Lock status of bus door 14

00b = Unlocked
01b = Locked
10b = Error
11b = Not available";
CM_ SG_ 2566643198 EnableStatusOfDoor13 "Enable status of bus door 13.  Enabled means the bus doors are able to be automatically opened or closed.

00b = Door disabled
01b = Door enabled
10b = Error
11b = Not available";
CM_ SG_ 2566643198 OpenStatusOfDoor13 "Open status of bus door 13

00b = Door closed
01b = Door opened
10b = Error
11b = Not available";
CM_ SG_ 2566643198 LockStatusOfDoor13 "Lock status of bus door 13

00b = Unlocked
01b = Locked
10b = Error
11b = Not available";
CM_ SG_ 2566643198 EnableStatusOfDoor12 "Enable status of bus door 12.  Enabled means the bus doors are able to be automatically opened or closed.

00b = Door disabled
01b = Door enabled
10b = Error
11b = Not available";
CM_ SG_ 2566643198 OpenStatusOfDoor12 "Open status of bus door 12

00b = Door closed
01b = Door opened
10b = Error
11b = Not available";
CM_ SG_ 2566643198 LockStatusOfDoor12 "Lock status of bus door 12

00b = Unlocked
01b = Locked
10b = Error
11b = Not available";
CM_ SG_ 2566643198 EnableStatusOfDoor11 "Enable status of bus door 11.  Enabled means the bus doors are able to be automatically opened or closed.

00b = Door disabled
01b = Door enabled
10b = Error
11b = Not available";
CM_ SG_ 2566643198 OpenStatusOfDoor11 "Open status of bus door 11

00b = Door closed
01b = Door opened
10b = Error
11b = Not available";
CM_ SG_ 2566643198 LockStatusOfDoor11 "Lock status of bus door 11

00b = Unlocked 
01b = Locked
10b = Error
11b = Not available";
BA_DEF_ SG_  "GenSigInactiveValue" INT 0 0;
BA_DEF_ SG_  "SigType" ENUM  "Default","Range","RangeSigned","ASCII","Discrete","Control","ReferencePGN","DTC","StringDelimiter","StringLength","StringLengthControl","MessageCounter","MessageChecksum";
BA_DEF_ SG_  "GenSigStartValue" INT 0 2147483647;
BA_DEF_ SG_  "GenSigSendType" ENUM  "Cyclic","OnWrite","OnWriteWithRepetition","OnChange","OnChangeWithRepetition","IfActive","IfActiveWithRepetition","NoSigSendType";
BA_DEF_ SG_  "GenSigILSupport" ENUM  "No","Yes";
BA_DEF_ SG_  "SPN" INT 0 524287;
BA_DEF_ BO_  "J1939CPgSendTimeout" INT -1 3600000;
BA_DEF_ BO_  "J1939CPgTOS" INT 0 7;
BA_DEF_ BO_  "J1939PgAppearanceOnBus" ENUM  "Default","CAN_Extended","CANFD_Extended";
BA_DEF_ BO_  "FsJ1939UseCrcAndCounter" STRING ;
BA_DEF_ BO_  "TpJ1939VarDlc" ENUM  "No","Yes";
BA_DEF_ BO_  "GenMsgNrOfRepetition" INT 0 1000000;
BA_DEF_ BO_  "GenMsgCycleTimeFast" INT 0 3600000;
BA_DEF_ BO_  "GenMsgFastOnStart" INT 0 100000;
BA_DEF_ BO_  "GenMsgStartDelayTime" INT 0 100000;
BA_DEF_ BO_  "GenMsgILSupport" ENUM  "No","Yes";
BA_DEF_ BO_  "GenMsgDelayTime" INT 0 1000;
BA_DEF_ BO_  "GenMsgRequestable" INT 0 1;
BA_DEF_ BO_  "GenMsgSendType" ENUM  "cyclic","NotUsed","NotUsed","NotUsed","NotUsed","NotUsed","NotUsed","IfActive","noMsgSendType";
BA_DEF_ BO_  "VFrameFormat" ENUM  "StandardCAN","ExtendedCAN","reserved","J1939PG","reserved","reserved","reserved","reserved","reserved","reserved","reserved","reserved","reserved","reserved","StandardCAN_FD","ExtendedCAN_FD";
BA_DEF_ BO_  "SingleFrame" INT 0 1;
BA_DEF_ BO_  "GenMsgCycleTime" INT 0 3600000;
BA_DEF_ SG_  "SystemSignalLongSymbol" STRING ;
BA_DEF_DEF_  "GenSigInactiveValue" 0;
BA_DEF_DEF_  "SigType" "Default";
BA_DEF_DEF_  "GenSigStartValue" 0;
BA_DEF_DEF_  "GenSigSendType" "NoSigSendType";
BA_DEF_DEF_  "GenSigILSupport" "Yes";
BA_DEF_DEF_  "SPN" 0;
BA_DEF_DEF_  "J1939CPgSendTimeout" -1;
BA_DEF_DEF_  "J1939CPgTOS" 2;
BA_DEF_DEF_  "J1939PgAppearanceOnBus" "Default";
BA_DEF_DEF_  "FsJ1939UseCrcAndCounter" "";
BA_DEF_DEF_  "TpJ1939VarDlc" "No";
BA_DEF_DEF_  "GenMsgNrOfRepetition" 0;
BA_DEF_DEF_  "GenMsgCycleTimeFast" 0;
BA_DEF_DEF_  "GenMsgFastOnStart" 0;
BA_DEF_DEF_  "GenMsgStartDelayTime" 0;
BA_DEF_DEF_  "GenMsgILSupport" "Yes";
BA_DEF_DEF_  "GenMsgDelayTime" 0;
BA_DEF_DEF_  "GenMsgRequestable" 1;
BA_DEF_DEF_  "GenMsgSendType" "noMsgSendType";
BA_DEF_DEF_  "VFrameFormat" "J1939PG";
BA_DEF_DEF_  "SingleFrame" 1;
BA_DEF_DEF_  "GenMsgCycleTime" 0;
BA_DEF_DEF_  "SystemSignalLongSymbol" "";
BA_ "GenMsgSendType" BO_ 2565917438 0;
BA_ "GenMsgCycleTime" BO_ 2565917438 100;
BA_ "GenMsgSendType" BO_ 2364590590 0;
BA_ "GenMsgCycleTime" BO_ 2364590590 100;
BA_ "GenMsgSendType" BO_ 2364590334 0;
BA_ "GenMsgCycleTime" BO_ 2364590334 100;
BA_ "TpJ1939VarDlc" BO_ 2624519934 1;
BA_ "GenMsgSendType" BO_ 2566661886 0;
BA_ "GenMsgCycleTime" BO_ 2566661886 1000;
BA_ "GenMsgSendType" BO_ 2566656254 0;
BA_ "GenMsgCycleTime" BO_ 2566656254 1000;
BA_ "GenMsgDelayTime" BO_ 2566655998 100;
BA_ "GenMsgSendType" BO_ 2566655998 0;
BA_ "GenMsgCycleTime" BO_ 2566655998 1000;
BA_ "GenMsgDelayTime" BO_ 2566655742 100;
BA_ "GenMsgSendType" BO_ 2566655742 0;
BA_ "GenMsgCycleTime" BO_ 2566655742 1000;
BA_ "GenMsgSendType" BO_ 2633764094 0;
BA_ "GenMsgCycleTime" BO_ 2633764094 1000;
BA_ "GenMsgSendType" BO_ 2566654974 0;
BA_ "GenMsgCycleTime" BO_ 2566654974 250;
BA_ "GenMsgDelayTime" BO_ 2566654718 10;
BA_ "GenMsgSendType" BO_ 2566654718 0;
BA_ "GenMsgCycleTime" BO_ 2566654718 100;
BA_ "GenMsgSendType" BO_ 2566654462 0;
BA_ "GenMsgCycleTime" BO_ 2566654462 1000;
BA_ "GenMsgDelayTime" BO_ 2566654206 10;
BA_ "GenMsgSendType" BO_ 2566654206 0;
BA_ "GenMsgCycleTime" BO_ 2566654206 100;
BA_ "GenMsgSendType" BO_ 2566653950 0;
BA_ "GenMsgCycleTime" BO_ 2566653950 1000;
BA_ "GenMsgDelayTime" BO_ 2566653694 10;
BA_ "GenMsgSendType" BO_ 2566653694 0;
BA_ "GenMsgCycleTime" BO_ 2566653694 100;
BA_ "GenMsgSendType" BO_ 2566653438 0;
BA_ "GenMsgCycleTime" BO_ 2566653438 1000;
BA_ "GenMsgDelayTime" BO_ 2566653182 10;
BA_ "GenMsgSendType" BO_ 2566653182 0;
BA_ "GenMsgCycleTime" BO_ 2566653182 100;
BA_ "GenMsgSendType" BO_ 2566652926 0;
BA_ "GenMsgCycleTime" BO_ 2566652926 1000;
BA_ "GenMsgDelayTime" BO_ 2566652670 1000;
BA_ "GenMsgSendType" BO_ 2566652670 0;
BA_ "GenMsgCycleTime" BO_ 2566652670 10000;
BA_ "GenMsgSendType" BO_ 2566652414 0;
BA_ "GenMsgCycleTime" BO_ 2566652414 1000;
BA_ "GenMsgSendType" BO_ 2566651902 0;
BA_ "GenMsgCycleTime" BO_ 2566651902 1000;
BA_ "GenMsgSendType" BO_ 2566651646 0;
BA_ "GenMsgCycleTime" BO_ 2566651646 1000;
BA_ "GenMsgSendType" BO_ 2566651390 0;
BA_ "GenMsgCycleTime" BO_ 2566651390 1000;
BA_ "GenMsgSendType" BO_ 2566651134 0;
BA_ "GenMsgCycleTime" BO_ 2566651134 1000;
BA_ "GenMsgSendType" BO_ 2566650878 0;
BA_ "GenMsgCycleTime" BO_ 2566650878 1000;
BA_ "GenMsgSendType" BO_ 2566650622 0;
BA_ "GenMsgCycleTime" BO_ 2566650622 1000;
BA_ "GenMsgSendType" BO_ 2566650366 0;
BA_ "GenMsgCycleTime" BO_ 2566650366 1000;
BA_ "GenMsgSendType" BO_ 2566650110 0;
BA_ "GenMsgCycleTime" BO_ 2566650110 1000;
BA_ "GenMsgSendType" BO_ 2566649854 0;
BA_ "GenMsgCycleTime" BO_ 2566649854 1000;
BA_ "GenMsgSendType" BO_ 2566649598 0;
BA_ "GenMsgCycleTime" BO_ 2566649598 5000;
BA_ "GenMsgSendType" BO_ 2566649342 0;
BA_ "GenMsgCycleTime" BO_ 2566649342 500;
BA_ "GenMsgSendType" BO_ 2566649086 0;
BA_ "GenMsgCycleTime" BO_ 2566649086 500;
BA_ "GenMsgSendType" BO_ 2365322238 0;
BA_ "GenMsgCycleTime" BO_ 2365322238 100;
BA_ "GenMsgSendType" BO_ 2566648318 0;
BA_ "GenMsgCycleTime" BO_ 2566648318 30000;
BA_ "GenMsgSendType" BO_ 2566648062 0;
BA_ "GenMsgCycleTime" BO_ 2566648062 10000;
BA_ "GenMsgSendType" BO_ 2566647806 0;
BA_ "GenMsgCycleTime" BO_ 2566647806 10000;
BA_ "GenMsgSendType" BO_ 2566647550 0;
BA_ "GenMsgCycleTime" BO_ 2566647550 10000;
BA_ "GenMsgSendType" BO_ 2566647294 0;
BA_ "GenMsgCycleTime" BO_ 2566647294 10000;
BA_ "GenMsgSendType" BO_ 2566647038 0;
BA_ "GenMsgCycleTime" BO_ 2566647038 10000;
BA_ "GenMsgSendType" BO_ 2566646782 0;
BA_ "GenMsgCycleTime" BO_ 2566646782 10000;
BA_ "TpJ1939VarDlc" BO_ 2633755134 1;
BA_ "GenMsgDelayTime" BO_ 2633754622 1000;
BA_ "GenMsgSendType" BO_ 2633754622 0;
BA_ "GenMsgCycleTime" BO_ 2633754622 10000;
BA_ "GenMsgSendType" BO_ 2365318910 0;
BA_ "GenMsgCycleTime" BO_ 2365318910 1000;
BA_ "GenMsgSendType" BO_ 2566645246 0;
BA_ "GenMsgCycleTime" BO_ 2566645246 1000;
BA_ "GenMsgSendType" BO_ 2566644990 0;
BA_ "GenMsgCycleTime" BO_ 2566644990 500;
BA_ "GenMsgSendType" BO_ 2633753598 0;
BA_ "GenMsgCycleTime" BO_ 2633753598 1000;
BA_ "GenMsgSendType" BO_ 2633753342 0;
BA_ "GenMsgCycleTime" BO_ 2633753342 1000;
BA_ "GenMsgSendType" BO_ 2633753086 0;
BA_ "GenMsgCycleTime" BO_ 2633753086 1000;
BA_ "GenMsgSendType" BO_ 2633752830 0;
BA_ "GenMsgCycleTime" BO_ 2633752830 1000;
BA_ "GenMsgSendType" BO_ 2566643710 0;
BA_ "GenMsgCycleTime" BO_ 2566643710 500;
BA_ "GenMsgSendType" BO_ 2566643454 0;
BA_ "GenMsgCycleTime" BO_ 2566643454 1000;
BA_ "GenMsgDelayTime" BO_ 2566643198 100;
BA_ "GenMsgSendType" BO_ 2566643198 0;
BA_ "GenMsgCycleTime" BO_ 2566643198 1000;
BA_ "SigType" SG_ 2565917438 PLedDueToUndefinedReason 5;
BA_ "SPN" SG_ 2565917438 PLedDueToUndefinedReason 9220;
BA_ "SigType" SG_ 2565917438 PLedDueToRateOfChangeLmt 5;
BA_ "SPN" SG_ 2565917438 PLedDueToRateOfChangeLmt 9219;
BA_ "SigType" SG_ 2565917438 PLedDueToPwrETemp 5;
BA_ "SPN" SG_ 2565917438 PLedDueToPwrETemp 9218;
BA_ "SigType" SG_ 2565917438 PLedDueToEFilterTemp 5;
BA_ "SPN" SG_ 2565917438 PLedDueToEFilterTemp 9217;
BA_ "SigType" SG_ 2565917438 PLedDueToCtrlTemp 5;
BA_ "SPN" SG_ 2565917438 PLedDueToCtrlTemp 9216;
BA_ "SigType" SG_ 2565917438 FreqCmdExceedsMax 5;
BA_ "SPN" SG_ 2565917438 FreqCmdExceedsMax 9215;
BA_ "SigType" SG_ 2565917438 FreqCmdBelowMin 5;
BA_ "SPN" SG_ 2565917438 FreqCmdBelowMin 9214;
BA_ "SigType" SG_ 2565917438 PLedDueToDCSideVMin 5;
BA_ "SPN" SG_ 2565917438 PLedDueToDCSideVMin 9213;
BA_ "SigType" SG_ 2565917438 PLedDueToACSideRMSCur 5;
BA_ "SPN" SG_ 2565917438 PLedDueToACSideRMSCur 9212;
BA_ "SigType" SG_ 2565917438 PLedDueToDCSideCur 5;
BA_ "SPN" SG_ 2565917438 PLedDueToDCSideCur 9211;
BA_ "SigType" SG_ 2364590590 SLIV 1;
BA_ "SPN" SG_ 2364590590 SLIV 9210;
BA_ "SigType" SG_ 2364590590 IgntV 1;
BA_ "SPN" SG_ 2364590590 IgntV 9209;
BA_ "SigType" SG_ 2364590334 DCSideNegToChassisGroundV 1;
BA_ "SPN" SG_ 2364590334 DCSideNegToChassisGroundV 9582;
BA_ "SigType" SG_ 2364590334 DCSideCur 1;
BA_ "SPN" SG_ 2364590334 DCSideCur 8891;
BA_ "SigType" SG_ 2364590334 DCSideV 1;
BA_ "SPN" SG_ 2364590334 DCSideV 8890;
BA_ "SigType" SG_ 2364590334 DCSidePwr 1;
BA_ "SPN" SG_ 2364590334 DCSidePwr 8889;
BA_ "SPN" SG_ 2624519934 CommandedReceiveSPNSA 8841;
BA_ "SigType" SG_ 2624519934 CommandedReceiveSPNReqSt 5;
BA_ "SPN" SG_ 2624519934 CommandedReceiveSPNReqSt 8840;
BA_ "SPN" SG_ 2624519934 CommandedReceiveSPN 8839;
BA_ "SPN" SG_ 2624519934 TransactionMode 8838;
BA_ "SPN" SG_ 2624519934 CommandedPort 8837;
BA_ "SPN" SG_ 2557345534 PlungerFiringOrder 8870;
BA_ "SigType" SG_ 2557345534 RodLoadHiThreshold 1;
BA_ "SPN" SG_ 2557345534 RodLoadHiThreshold 8869;
BA_ "SigType" SG_ 2557345534 CrankshaftSpdHiThreshold 1;
BA_ "SPN" SG_ 2557345534 CrankshaftSpdHiThreshold 8868;
BA_ "SigType" SG_ 2557345534 CrankshaftSpdLowThreshold 1;
BA_ "SPN" SG_ 2557345534 CrankshaftSpdLowThreshold 8867;
BA_ "SigType" SG_ 2557345534 DisPressHiThreshold 1;
BA_ "SPN" SG_ 2557345534 DisPressHiThreshold 8866;
BA_ "SigType" SG_ 2557345534 SuctionPressHiThreshold 1;
BA_ "SPN" SG_ 2557345534 SuctionPressHiThreshold 8865;
BA_ "SigType" SG_ 2557345534 SuctionPressLowThreshold 1;
BA_ "SPN" SG_ 2557345534 SuctionPressLowThreshold 8864;
BA_ "SigType" SG_ 2557345534 GearBoxOilTempHiThreshold 1;
BA_ "SPN" SG_ 2557345534 GearBoxOilTempHiThreshold 8863;
BA_ "SigType" SG_ 2557345534 GearBoxOilTempLowThreshold 1;
BA_ "SPN" SG_ 2557345534 GearBoxOilTempLowThreshold 8862;
BA_ "SigType" SG_ 2557345534 GearBoxOilPressHiThreshold 1;
BA_ "SPN" SG_ 2557345534 GearBoxOilPressHiThreshold 8861;
BA_ "SigType" SG_ 2557345534 GearBoxOilPressLowThreshold 1;
BA_ "SPN" SG_ 2557345534 GearBoxOilPressLowThreshold 8860;
BA_ "SPN" SG_ 2557214462 DisPressCalSetPointCmd 9198;
BA_ "SPN" SG_ 2557214462 SuctionPressCalSetPointCmd 9197;
BA_ "SPN" SG_ 2557148926 VesselSpdCtrlMode 9660;
BA_ "SigType" SG_ 2557148926 VesselEngSetSpd 1;
BA_ "SPN" SG_ 2557148926 VesselEngSetSpd 9659;
BA_ "SPN" SG_ 2557148926 TrollingModeCurSetting 9658;
BA_ "SPN" SG_ 2557148926 TrollingMode 9657;
BA_ "SPN" SG_ 2557148926 EngThrotSynchModeCurSetting 9656;
BA_ "SigType" SG_ 2557148926 OpStationLockout 5;
BA_ "SPN" SG_ 2557148926 OpStationLockout 9655;
BA_ "SigType" SG_ 2557148926 OpStationInCtrlLocation 1;
BA_ "SPN" SG_ 2557148926 OpStationInCtrlLocation 9654;
BA_ "SigType" SG_ 2557083390 EngTrollingModeSetSpd 1;
BA_ "SPN" SG_ 2557083390 EngTrollingModeSetSpd 9664;
BA_ "SPN" SG_ 2557083390 EngThrotSynchModeCmd 9663;
BA_ "SPN" SG_ 2557083390 TrollingModeSettingCmd 9662;
BA_ "SigType" SG_ 2557083390 OpStationLocationSetting 1;
BA_ "SPN" SG_ 2557083390 OpStationLocationSetting 9661;
BA_ "SigType" SG_ 2633785086 TotalEnergyOut 1;
BA_ "SPN" SG_ 2633785086 TotalEnergyOut 13366;
BA_ "SigType" SG_ 2633785086 TotalEnergyInput 1;
BA_ "SPN" SG_ 2633785086 TotalEnergyInput 13365;
BA_ "SigType" SG_ 2633785086 TotalAccumulatedCharge 1;
BA_ "SPN" SG_ 2633785086 TotalAccumulatedCharge 8212;
BA_ "SigType" SG_ 2633785086 TotalEnergyThroughput 1;
BA_ "SPN" SG_ 2633785086 TotalEnergyThroughput 8211;
BA_ "SigType" SG_ 2633785086 ContactorOpenUnderLoadCount 1;
BA_ "SPN" SG_ 2633785086 ContactorOpenUnderLoadCount 8122;
BA_ "SigType" SG_ 2633785086 StOfHealth 1;
BA_ "SPN" SG_ 2633785086 StOfHealth 8121;
BA_ "SPN" SG_ 2566675966 NomRatedCapacity 15262;
BA_ "SigType" SG_ 2566675966 NumOfHVESPsConfigured 1;
BA_ "SPN" SG_ 2566675966 NumOfHVESPsConfigured 12904;
BA_ "SigType" SG_ 2566675966 CellMinVLmt 1;
BA_ "SPN" SG_ 2566675966 CellMinVLmt 8210;
BA_ "SigType" SG_ 2566675966 CellMaxVLmt 1;
BA_ "SPN" SG_ 2566675966 CellMaxVLmt 8209;
BA_ "SigType" SG_ 2566675966 RecommendedMinOperatingTemp 1;
BA_ "SPN" SG_ 2566675966 RecommendedMinOperatingTemp 8208;
BA_ "SigType" SG_ 2566675966 RecommendedMaxOperatingTemp 1;
BA_ "SPN" SG_ 2566675966 RecommendedMaxOperatingTemp 8120;
BA_ "SigType" SG_ 2566675966 RecommendedMaxStOfCharge 1;
BA_ "SPN" SG_ 2566675966 RecommendedMaxStOfCharge 8119;
BA_ "SigType" SG_ 2566675966 RecommendedMinStOfCharge 1;
BA_ "SPN" SG_ 2566675966 RecommendedMinStOfCharge 8118;
BA_ "SigType" SG_ 2566675966 RecommendedMaxOperatingV 1;
BA_ "SPN" SG_ 2566675966 RecommendedMaxOperatingV 8117;
BA_ "SigType" SG_ 2566675966 RecommendedMinOperatingV 1;
BA_ "SPN" SG_ 2566675966 RecommendedMinOperatingV 8116;
BA_ "SigType" SG_ 2566675966 NominalV 1;
BA_ "SPN" SG_ 2566675966 NominalV 8115;
BA_ "SigType" SG_ 2566661886 Ctrl2Temp 1;
BA_ "SPN" SG_ 2566661886 Ctrl2Temp 7535;
BA_ "SigType" SG_ 2566661886 CtrlTemp 1;
BA_ "SPN" SG_ 2566661886 CtrlTemp 7529;
BA_ "SigType" SG_ 2566656254 EngPwrDerateRelHumidityDiff 1;
BA_ "GenSigStartValue" SG_ 2566656254 EngPwrDerateRelHumidityDiff 22127;
BA_ "SPN" SG_ 2566656254 EngPwrDerateRelHumidityDiff 12852;
BA_ "SigType" SG_ 2566656254 EngIn2AirTemp 1;
BA_ "SPN" SG_ 2566656254 EngIn2AirTemp 7850;
BA_ "SigType" SG_ 2566656254 BarometricAbsPress2 1;
BA_ "SPN" SG_ 2566656254 BarometricAbsPress2 7781;
BA_ "SigType" SG_ 2566655998 PitchSensitivity 1;
BA_ "SPN" SG_ 2566655998 PitchSensitivity 7801;
BA_ "SigType" SG_ 2566655998 Sensitivity 1;
BA_ "SPN" SG_ 2566655998 Sensitivity 7800;
BA_ "SigType" SG_ 2566655742 PitchSensitivity 1;
BA_ "SPN" SG_ 2566655742 PitchSensitivity 7813;
BA_ "SigType" SG_ 2566655742 Sensitivity 1;
BA_ "SPN" SG_ 2566655742 Sensitivity 7812;
BA_ "SigType" SG_ 2633764350 EngagementCycles 1;
BA_ "SPN" SG_ 2633764350 EngagementCycles 7826;
BA_ "SigType" SG_ 2633764350 OpTime 1;
BA_ "SPN" SG_ 2633764350 OpTime 7825;
BA_ "SigType" SG_ 2633764094 GasolineFuelTankPress 1;
BA_ "SPN" SG_ 2633764094 GasolineFuelTankPress 7835;
BA_ "SigType" SG_ 2633764094 CanisterPurgeVlvCmd 1;
BA_ "SPN" SG_ 2633764094 CanisterPurgeVlvCmd 7834;
BA_ "SigType" SG_ 2633764094 CanisterVentVlv 4;
BA_ "SPN" SG_ 2633764094 CanisterVentVlv 7833;
BA_ "SigType" SG_ 2566654974 AbsEngLoadPercentAirMass 1;
BA_ "SPN" SG_ 2566654974 AbsEngLoadPercentAirMass 13131;
BA_ "SigType" SG_ 2566654974 NomFrictionPercentTrq 1;
BA_ "SPN" SG_ 2566654974 NomFrictionPercentTrq 12926;
BA_ "SigType" SG_ 2566654974 ActualMaxAvailableEngPercentFuel 1;
BA_ "SPN" SG_ 2566654974 ActualMaxAvailableEngPercentFuel 8630;
BA_ "SigType" SG_ 2566654974 EstEngParasiticLossesPercentTrq 1;
BA_ "SPN" SG_ 2566654974 EstEngParasiticLossesPercentTrq 7837;
BA_ "SigType" SG_ 2566654718 SLIBatPack1Bat1V 1;
BA_ "SPN" SG_ 2566654718 SLIBatPack1Bat1V 7902;
BA_ "SigType" SG_ 2566654718 SLIBatPack1Bat1Temp 1;
BA_ "SPN" SG_ 2566654718 SLIBatPack1Bat1Temp 7901;
BA_ "SigType" SG_ 2566654718 SLIBatPack1Bat1NetCur 1;
BA_ "SPN" SG_ 2566654718 SLIBatPack1Bat1NetCur 7900;
BA_ "SPN" SG_ 2566654462 SLIBatPack1Snsr1InitStatus 7907;
BA_ "SigType" SG_ 2566654462 SLIBatPack1Bat1PredMinCrankingV 1;
BA_ "SPN" SG_ 2566654462 SLIBatPack1Bat1PredMinCrankingV 7906;
BA_ "SigType" SG_ 2566654462 SLIBatPack1Bat1Health 1;
BA_ "SPN" SG_ 2566654462 SLIBatPack1Bat1Health 7905;
BA_ "SigType" SG_ 2566654462 SLIBatPack1Bat1Capacity 1;
BA_ "SPN" SG_ 2566654462 SLIBatPack1Bat1Capacity 7904;
BA_ "SigType" SG_ 2566654462 SLIBatPack1Bat1StOfCharge 1;
BA_ "SPN" SG_ 2566654462 SLIBatPack1Bat1StOfCharge 7903;
BA_ "SigType" SG_ 2566654206 SLIBatPack1Bat2V 1;
BA_ "SPN" SG_ 2566654206 SLIBatPack1Bat2V 7910;
BA_ "SigType" SG_ 2566654206 SLIBatPack1Bat2Temp 1;
BA_ "SPN" SG_ 2566654206 SLIBatPack1Bat2Temp 7909;
BA_ "SigType" SG_ 2566654206 SLIBatPack1Bat2NetCur 1;
BA_ "SPN" SG_ 2566654206 SLIBatPack1Bat2NetCur 7908;
BA_ "SPN" SG_ 2566653950 SLIBatPack1Snsr2InitStatus 7915;
BA_ "SigType" SG_ 2566653950 SLIBatPack1Bat2PredMinCrankingV 1;
BA_ "SPN" SG_ 2566653950 SLIBatPack1Bat2PredMinCrankingV 7914;
BA_ "SigType" SG_ 2566653950 SLIBatPack1Bat2Health 1;
BA_ "SPN" SG_ 2566653950 SLIBatPack1Bat2Health 7913;
BA_ "SigType" SG_ 2566653950 SLIBatPack1Bat2Capacity 1;
BA_ "SPN" SG_ 2566653950 SLIBatPack1Bat2Capacity 7912;
BA_ "SigType" SG_ 2566653950 SLIBatPack1Bat2StOfCharge 1;
BA_ "SPN" SG_ 2566653950 SLIBatPack1Bat2StOfCharge 7911;
BA_ "SigType" SG_ 2566653694 SLIBatPack1Bat3V 1;
BA_ "SPN" SG_ 2566653694 SLIBatPack1Bat3V 7918;
BA_ "SigType" SG_ 2566653694 SLIBatPack1Bat3Temp 1;
BA_ "SPN" SG_ 2566653694 SLIBatPack1Bat3Temp 7917;
BA_ "SigType" SG_ 2566653694 SLIBatPack1Bat3NetCur 1;
BA_ "SPN" SG_ 2566653694 SLIBatPack1Bat3NetCur 7916;
BA_ "SPN" SG_ 2566653438 SLIBatPack1Snsr3InitStatus 7923;
BA_ "SigType" SG_ 2566653438 SLIBatPack1Bat3PredMinCrankingV 1;
BA_ "SPN" SG_ 2566653438 SLIBatPack1Bat3PredMinCrankingV 7922;
BA_ "SigType" SG_ 2566653438 SLIBatPack1Bat3Health 1;
BA_ "SPN" SG_ 2566653438 SLIBatPack1Bat3Health 7921;
BA_ "SigType" SG_ 2566653438 SLIBatPack1Bat3Capacity 1;
BA_ "SPN" SG_ 2566653438 SLIBatPack1Bat3Capacity 7920;
BA_ "SigType" SG_ 2566653438 SLIBatPack1Bat3StOfCharge 1;
BA_ "SPN" SG_ 2566653438 SLIBatPack1Bat3StOfCharge 7919;
BA_ "SigType" SG_ 2566653182 SLIBatPack1Bat4V 1;
BA_ "SPN" SG_ 2566653182 SLIBatPack1Bat4V 7926;
BA_ "SigType" SG_ 2566653182 SLIBatPack1Bat4Temp 1;
BA_ "SPN" SG_ 2566653182 SLIBatPack1Bat4Temp 7925;
BA_ "SigType" SG_ 2566653182 SLIBatPack1Bat4NetCur 1;
BA_ "SPN" SG_ 2566653182 SLIBatPack1Bat4NetCur 7924;
BA_ "SPN" SG_ 2566652926 SLIBatPack1Snsr4InitStatus 7931;
BA_ "SigType" SG_ 2566652926 SLIBatPack1Bat4PredMinCrankingV 1;
BA_ "SPN" SG_ 2566652926 SLIBatPack1Bat4PredMinCrankingV 7930;
BA_ "SigType" SG_ 2566652926 SLIBatPack1Bat4Health 1;
BA_ "SPN" SG_ 2566652926 SLIBatPack1Bat4Health 7929;
BA_ "SigType" SG_ 2566652926 SLIBatPack1Bat4Capacity 1;
BA_ "SPN" SG_ 2566652926 SLIBatPack1Bat4Capacity 7928;
BA_ "SigType" SG_ 2566652926 SLIBatPack1Bat4StOfCharge 1;
BA_ "SPN" SG_ 2566652926 SLIBatPack1Bat4StOfCharge 7927;
BA_ "SigType" SG_ 2566652670 A2SysHydrocarbon 1;
BA_ "SPN" SG_ 2566652670 A2SysHydrocarbon 7935;
BA_ "SigType" SG_ 2566652670 A2DEFDosingSysFrozen 5;
BA_ "SPN" SG_ 2566652670 A2DEFDosingSysFrozen 6803;
BA_ "SigType" SG_ 2566652670 A1DEFDosingSysFrozen 5;
BA_ "SPN" SG_ 2566652670 A1DEFDosingSysFrozen 6802;
BA_ "SigType" SG_ 2566652670 A1SysHydrocarbon 1;
BA_ "SPN" SG_ 2566652670 A1SysHydrocarbon 7934;
BA_ "SigType" SG_ 2566652670 DEFFrozenTime 1;
BA_ "SPN" SG_ 2566652670 DEFFrozenTime 7938;
BA_ "SPN" SG_ 2566652414 Instance 8308;
BA_ "SigType" SG_ 2566652414 OperatingStatus 5;
BA_ "SPN" SG_ 2566652414 OperatingStatus 7954;
BA_ "SigType" SG_ 2566652414 ServiceInd 5;
BA_ "SPN" SG_ 2566652414 ServiceInd 7953;
BA_ "SigType" SG_ 2566652414 Pwr 1;
BA_ "SPN" SG_ 2566652414 Pwr 7952;
BA_ "SigType" SG_ 2566652414 MediumTemp 1;
BA_ "SPN" SG_ 2566652414 MediumTemp 7951;
BA_ "SigType" SG_ 2566652414 Spd 1;
BA_ "SPN" SG_ 2566652414 Spd 7950;
BA_ "SigType" SG_ 2566652414 CtrlCmdStatus 5;
BA_ "SPN" SG_ 2566652414 CtrlCmdStatus 7949;
BA_ "SPN" SG_ 2566652414 CtrlStatusReasonCode 7948;
BA_ "SigType" SG_ 2566652414 EnableStatus 5;
BA_ "SPN" SG_ 2566652414 EnableStatus 7947;
BA_ "SigType" SG_ 2566651902 OperatingStatus 5;
BA_ "SPN" SG_ 2566651902 OperatingStatus 7978;
BA_ "SigType" SG_ 2566651902 ServiceInd 5;
BA_ "SPN" SG_ 2566651902 ServiceInd 7977;
BA_ "SigType" SG_ 2566651902 Pwr 1;
BA_ "SPN" SG_ 2566651902 Pwr 7976;
BA_ "SigType" SG_ 2566651902 CtrlTemp 1;
BA_ "SPN" SG_ 2566651902 CtrlTemp 7975;
BA_ "SigType" SG_ 2566651902 MotorSpd 1;
BA_ "SPN" SG_ 2566651902 MotorSpd 7974;
BA_ "SigType" SG_ 2566651902 CtrlCmdStatus 5;
BA_ "SPN" SG_ 2566651902 CtrlCmdStatus 7973;
BA_ "SPN" SG_ 2566651902 CtrlStatusReasonCode 7972;
BA_ "SigType" SG_ 2566651902 EnableStatus 5;
BA_ "SPN" SG_ 2566651902 EnableStatus 7971;
BA_ "SigType" SG_ 2566651646 OperatingStatus 5;
BA_ "SPN" SG_ 2566651646 OperatingStatus 7990;
BA_ "SigType" SG_ 2566651646 ServiceInd 5;
BA_ "SPN" SG_ 2566651646 ServiceInd 7989;
BA_ "SigType" SG_ 2566651646 Pwr 1;
BA_ "SPN" SG_ 2566651646 Pwr 7988;
BA_ "SigType" SG_ 2566651646 CtrlTemp 1;
BA_ "SPN" SG_ 2566651646 CtrlTemp 7987;
BA_ "SigType" SG_ 2566651646 MotorSpd 1;
BA_ "SPN" SG_ 2566651646 MotorSpd 7986;
BA_ "SigType" SG_ 2566651646 CtrlCmdStatus 5;
BA_ "SPN" SG_ 2566651646 CtrlCmdStatus 7985;
BA_ "SPN" SG_ 2566651646 CtrlStatusReasonCode 7984;
BA_ "SigType" SG_ 2566651646 EnableStatus 5;
BA_ "SPN" SG_ 2566651646 EnableStatus 7983;
BA_ "SigType" SG_ 2566651390 OperatingStatus 5;
BA_ "SPN" SG_ 2566651390 OperatingStatus 8002;
BA_ "SigType" SG_ 2566651390 ServiceInd 5;
BA_ "SPN" SG_ 2566651390 ServiceInd 8001;
BA_ "SigType" SG_ 2566651390 Pwr 1;
BA_ "SPN" SG_ 2566651390 Pwr 8000;
BA_ "SigType" SG_ 2566651390 CtrlTemp 1;
BA_ "SPN" SG_ 2566651390 CtrlTemp 7999;
BA_ "SigType" SG_ 2566651390 MotorSpd 1;
BA_ "SPN" SG_ 2566651390 MotorSpd 7998;
BA_ "SigType" SG_ 2566651390 CtrlCmdStatus 5;
BA_ "SPN" SG_ 2566651390 CtrlCmdStatus 7997;
BA_ "SPN" SG_ 2566651390 CtrlStatusReasonCode 7996;
BA_ "SigType" SG_ 2566651390 EnableStatus 5;
BA_ "SPN" SG_ 2566651390 EnableStatus 7995;
BA_ "SigType" SG_ 2566651134 OperatingStatus 5;
BA_ "SPN" SG_ 2566651134 OperatingStatus 8014;
BA_ "SigType" SG_ 2566651134 ServiceInd 5;
BA_ "SPN" SG_ 2566651134 ServiceInd 8013;
BA_ "SigType" SG_ 2566651134 Pwr 1;
BA_ "SPN" SG_ 2566651134 Pwr 8012;
BA_ "SigType" SG_ 2566651134 CtrlTemp 1;
BA_ "SPN" SG_ 2566651134 CtrlTemp 8011;
BA_ "SigType" SG_ 2566651134 MotorSpd 1;
BA_ "SPN" SG_ 2566651134 MotorSpd 8010;
BA_ "SigType" SG_ 2566651134 CtrlCmdStatus 5;
BA_ "SPN" SG_ 2566651134 CtrlCmdStatus 8009;
BA_ "SPN" SG_ 2566651134 CtrlStatusReasonCode 8008;
BA_ "SigType" SG_ 2566651134 EnableStatus 5;
BA_ "SPN" SG_ 2566651134 EnableStatus 8007;
BA_ "SigType" SG_ 2566650878 OperatingStatus 5;
BA_ "SPN" SG_ 2566650878 OperatingStatus 8026;
BA_ "SigType" SG_ 2566650878 ServiceInd 5;
BA_ "SPN" SG_ 2566650878 ServiceInd 8025;
BA_ "SigType" SG_ 2566650878 Pwr 1;
BA_ "SPN" SG_ 2566650878 Pwr 8024;
BA_ "SigType" SG_ 2566650878 CtrlTemp 1;
BA_ "SPN" SG_ 2566650878 CtrlTemp 8023;
BA_ "SigType" SG_ 2566650878 MotorSpd 1;
BA_ "SPN" SG_ 2566650878 MotorSpd 8022;
BA_ "SigType" SG_ 2566650878 CtrlCmdStatus 5;
BA_ "SPN" SG_ 2566650878 CtrlCmdStatus 8021;
BA_ "SPN" SG_ 2566650878 CtrlStatusReasonCode 8020;
BA_ "SigType" SG_ 2566650878 EnableStatus 5;
BA_ "SPN" SG_ 2566650878 EnableStatus 8019;
BA_ "SigType" SG_ 2566650622 OperatingStatus 5;
BA_ "SPN" SG_ 2566650622 OperatingStatus 8038;
BA_ "SigType" SG_ 2566650622 ServiceInd 5;
BA_ "SPN" SG_ 2566650622 ServiceInd 8037;
BA_ "SigType" SG_ 2566650622 Pwr 1;
BA_ "SPN" SG_ 2566650622 Pwr 8036;
BA_ "SigType" SG_ 2566650622 CtrlTemp 1;
BA_ "SPN" SG_ 2566650622 CtrlTemp 8035;
BA_ "SigType" SG_ 2566650622 MotorSpd 1;
BA_ "SPN" SG_ 2566650622 MotorSpd 8034;
BA_ "SigType" SG_ 2566650622 CtrlCmdStatus 5;
BA_ "SPN" SG_ 2566650622 CtrlCmdStatus 8033;
BA_ "SPN" SG_ 2566650622 CtrlStatusReasonCode 8032;
BA_ "SigType" SG_ 2566650622 EnableStatus 5;
BA_ "SPN" SG_ 2566650622 EnableStatus 8031;
BA_ "SigType" SG_ 2566650366 OperatingStatus 5;
BA_ "SPN" SG_ 2566650366 OperatingStatus 8050;
BA_ "SigType" SG_ 2566650366 ServiceInd 5;
BA_ "SPN" SG_ 2566650366 ServiceInd 8049;
BA_ "SigType" SG_ 2566650366 Pwr 1;
BA_ "SPN" SG_ 2566650366 Pwr 8048;
BA_ "SigType" SG_ 2566650366 CtrlTemp 1;
BA_ "SPN" SG_ 2566650366 CtrlTemp 8047;
BA_ "SigType" SG_ 2566650366 MotorSpd 1;
BA_ "SPN" SG_ 2566650366 MotorSpd 8046;
BA_ "SigType" SG_ 2566650366 CtrlCmdStatus 5;
BA_ "SPN" SG_ 2566650366 CtrlCmdStatus 8045;
BA_ "SPN" SG_ 2566650366 CtrlStatusReasonCode 8044;
BA_ "SigType" SG_ 2566650366 EnableStatus 5;
BA_ "SPN" SG_ 2566650366 EnableStatus 8043;
BA_ "SigType" SG_ 2566650110 OperatingStatus 5;
BA_ "SPN" SG_ 2566650110 OperatingStatus 8062;
BA_ "SigType" SG_ 2566650110 ServiceInd 5;
BA_ "SPN" SG_ 2566650110 ServiceInd 8061;
BA_ "SigType" SG_ 2566650110 Pwr 1;
BA_ "SPN" SG_ 2566650110 Pwr 8060;
BA_ "SigType" SG_ 2566650110 CtrlTemp 1;
BA_ "SPN" SG_ 2566650110 CtrlTemp 8059;
BA_ "SigType" SG_ 2566650110 MotorSpd 1;
BA_ "SPN" SG_ 2566650110 MotorSpd 8058;
BA_ "SigType" SG_ 2566650110 CtrlCmdStatus 5;
BA_ "SPN" SG_ 2566650110 CtrlCmdStatus 8057;
BA_ "SPN" SG_ 2566650110 CtrlStatusReasonCode 8056;
BA_ "SigType" SG_ 2566650110 EnableStatus 5;
BA_ "SPN" SG_ 2566650110 EnableStatus 8055;
BA_ "SigType" SG_ 2566649854 OperatingStatus 5;
BA_ "SPN" SG_ 2566649854 OperatingStatus 8074;
BA_ "SigType" SG_ 2566649854 ServiceInd 5;
BA_ "SPN" SG_ 2566649854 ServiceInd 8073;
BA_ "SigType" SG_ 2566649854 Pwr 1;
BA_ "SPN" SG_ 2566649854 Pwr 8072;
BA_ "SigType" SG_ 2566649854 CtrlTemp 1;
BA_ "SPN" SG_ 2566649854 CtrlTemp 8071;
BA_ "SigType" SG_ 2566649854 MotorSpd 1;
BA_ "SPN" SG_ 2566649854 MotorSpd 8070;
BA_ "SigType" SG_ 2566649854 CtrlCmdStatus 5;
BA_ "SPN" SG_ 2566649854 CtrlCmdStatus 8069;
BA_ "SPN" SG_ 2566649854 CtrlStatusReasonCode 8068;
BA_ "SigType" SG_ 2566649854 EnableStatus 5;
BA_ "SPN" SG_ 2566649854 EnableStatus 8067;
BA_ "SigType" SG_ 2566649598 TimeDilutionOfPrecision 1;
BA_ "SPN" SG_ 2566649598 TimeDilutionOfPrecision 8132;
BA_ "SigType" SG_ 2566649598 DilutionOfPrecision 1;
BA_ "SPN" SG_ 2566649598 DilutionOfPrecision 8131;
BA_ "SigType" SG_ 2566649598 VerticalDilutionOfPrecision 1;
BA_ "SPN" SG_ 2566649598 VerticalDilutionOfPrecision 8130;
BA_ "SigType" SG_ 2566649598 HorizontalDilutionOfPrecision 1;
BA_ "SPN" SG_ 2566649598 HorizontalDilutionOfPrecision 8129;
BA_ "SigType" SG_ 2566649598 TotalNumOfSatellitesInView 1;
BA_ "SPN" SG_ 2566649598 TotalNumOfSatellitesInView 8128;
BA_ "SigType" SG_ 2566649342 DOCInToDPFOutDeltaPress 1;
BA_ "SPN" SG_ 2566649342 DOCInToDPFOutDeltaPress 8162;
BA_ "SigType" SG_ 2566649342 OutPress 1;
BA_ "SPN" SG_ 2566649342 OutPress 8161;
BA_ "SigType" SG_ 2566649342 InPress 1;
BA_ "SPN" SG_ 2566649342 InPress 8160;
BA_ "SigType" SG_ 2566649086 DOCInToDPFOutDeltaPress 1;
BA_ "SPN" SG_ 2566649086 DOCInToDPFOutDeltaPress 8165;
BA_ "SigType" SG_ 2566649086 OutPress 1;
BA_ "SPN" SG_ 2566649086 OutPress 8164;
BA_ "SigType" SG_ 2566649086 InPress 1;
BA_ "SPN" SG_ 2566649086 InPress 8163;
BA_ "SigType" SG_ 2365322238 DirVS 1;
BA_ "SPN" SG_ 2365322238 DirVS 8166;
BA_ "SigType" SG_ 2566648318 MonitorETempStatus 5;
BA_ "SPN" SG_ 2566648318 MonitorETempStatus 8190;
BA_ "SigType" SG_ 2566648318 MonitorSPEStatus 5;
BA_ "SPN" SG_ 2566648318 MonitorSPEStatus 8189;
BA_ "SigType" SG_ 2566648318 MonitorSensingElementStatus 5;
BA_ "SPN" SG_ 2566648318 MonitorSensingElementStatus 8188;
BA_ "SigType" SG_ 2566648318 MonitorEnvironmentStatus 5;
BA_ "SPN" SG_ 2566648318 MonitorEnvironmentStatus 8187;
BA_ "SigType" SG_ 2566648318 MonitorTotalNumOfSensors 1;
BA_ "SPN" SG_ 2566648318 MonitorTotalNumOfSensors 8186;
BA_ "SigType" SG_ 2566648318 MonitorStatusIdNum 1;
BA_ "SPN" SG_ 2566648318 MonitorStatusIdNum 8185;
BA_ "SPN" SG_ 2566648062 NFBin6Count 8184;
BA_ "SPN" SG_ 2566648062 NFBin5Count 8183;
BA_ "SigType" SG_ 2566648062 NFBins5And6IdNum 1;
BA_ "SPN" SG_ 2566648062 NFBins5And6IdNum 8182;
BA_ "SPN" SG_ 2566647806 NFBin4Count 8181;
BA_ "SPN" SG_ 2566647806 NFBin3Count 8180;
BA_ "SigType" SG_ 2566647806 NFBins3And4IdNum 1;
BA_ "SPN" SG_ 2566647806 NFBins3And4IdNum 8179;
BA_ "SPN" SG_ 2566647550 NFBin2Count 8178;
BA_ "SPN" SG_ 2566647550 NFBin1Count 8177;
BA_ "SigType" SG_ 2566647550 NFBins1And2IdNum 1;
BA_ "SPN" SG_ 2566647550 NFBins1And2IdNum 8176;
BA_ "SPN" SG_ 2566647294 FBin6Count 8175;
BA_ "SPN" SG_ 2566647294 FBin5Count 8174;
BA_ "SigType" SG_ 2566647294 FBins5And6IdNum 1;
BA_ "SPN" SG_ 2566647294 FBins5And6IdNum 8173;
BA_ "SPN" SG_ 2566647038 FBin4Count 8172;
BA_ "SPN" SG_ 2566647038 FBin3Count 8171;
BA_ "SigType" SG_ 2566647038 FBins3And4IdNum 1;
BA_ "SPN" SG_ 2566647038 FBins3And4IdNum 8170;
BA_ "SPN" SG_ 2566646782 FBin2Count 8169;
BA_ "SPN" SG_ 2566646782 FBin1Count 8168;
BA_ "SigType" SG_ 2566646782 FBins1And2IdNum 1;
BA_ "SPN" SG_ 2566646782 FBins1And2IdNum 8167;
BA_ "SPN" SG_ 2633755390 MACAddressOctet6 8287;
BA_ "SPN" SG_ 2633755390 MACAddressOctet5 8286;
BA_ "SPN" SG_ 2633755390 MACAddressOctet4 8285;
BA_ "SPN" SG_ 2633755390 MACAddressOctet3 8284;
BA_ "SPN" SG_ 2633755390 MACAddressOctet2 8283;
BA_ "SPN" SG_ 2633755390 MACAddressOctet1 8282;
BA_ "SPN" SG_ 2633755390 DefaultGatewayOctet4 8281;
BA_ "SPN" SG_ 2633755390 DefaultGatewayOctet3 8280;
BA_ "SPN" SG_ 2633755390 DefaultGatewayOctet2 8279;
BA_ "SPN" SG_ 2633755390 DefaultGatewayOctet1 8278;
BA_ "SPN" SG_ 2633755390 SubnetMaskOctet4 8277;
BA_ "SPN" SG_ 2633755390 SubnetMaskOctet3 8276;
BA_ "SPN" SG_ 2633755390 SubnetMaskOctet2 8275;
BA_ "SPN" SG_ 2633755390 SubnetMaskOctet1 8274;
BA_ "SPN" SG_ 2633755390 IPv4AddressOctet4 8273;
BA_ "SPN" SG_ 2633755390 IPv4AddressOctet3 8272;
BA_ "SPN" SG_ 2633755390 IPv4AddressOctet2 8271;
BA_ "SPN" SG_ 2633755390 IPv4AddressOctet1 8270;
BA_ "SigType" SG_ 2633755390 LinkStatus 5;
BA_ "SPN" SG_ 2633755390 LinkStatus 8269;
BA_ "SPN" SG_ 2633755390 DHCPStatus 8268;
BA_ "SigType" SG_ 2633755134 HostName 3;
BA_ "SPN" SG_ 2633755134 HostName 8288;
BA_ "SigType" SG_ 2633754878 HCDoserDutyCycle 1;
BA_ "SPN" SG_ 2633754878 HCDoserDutyCycle 12743;
BA_ "SigType" SG_ 2633754878 OneDEFDosingMode 1;
BA_ "SPN" SG_ 2633754878 OneDEFDosingMode 12749;
BA_ "SigType" SG_ 2633754878 DEFUsedThisOperatingCycle 1;
BA_ "SPN" SG_ 2633754878 DEFUsedThisOperatingCycle 12748;
BA_ "SigType" SG_ 2633754878 TotalDEFUsed 1;
BA_ "SPN" SG_ 2633754878 TotalDEFUsed 8326;
BA_ "SigType" SG_ 2633754622 EmergOvrdTotalActivationTime 1;
BA_ "SPN" SG_ 2633754622 EmergOvrdTotalActivationTime 9179;
BA_ "SigType" SG_ 2633754622 A1SCRInHiTempTime 1;
BA_ "SPN" SG_ 2633754622 A1SCRInHiTempTime 8327;
BA_ "SPN" SG_ 2365318910 HVESFanInstance15 8402;
BA_ "SPN" SG_ 2365318910 HVESFanInstance14 8401;
BA_ "SPN" SG_ 2365318910 HVESFanInstance13 8400;
BA_ "SPN" SG_ 2365318910 HVESFanInstance12 8399;
BA_ "SPN" SG_ 2365318910 HVESFanInstance11 8398;
BA_ "SPN" SG_ 2365318910 HVESFanInstance10 8397;
BA_ "SPN" SG_ 2365318910 HVESFanInstance9 8396;
BA_ "SPN" SG_ 2365318910 HVESFanInstance8 8395;
BA_ "SPN" SG_ 2365318910 HVESFanInstance7 8394;
BA_ "SPN" SG_ 2365318910 HVESFanInstance6 8393;
BA_ "SPN" SG_ 2365318910 HVESFanInstance5 8392;
BA_ "SPN" SG_ 2365318910 HVESFanInstance4 8391;
BA_ "SPN" SG_ 2365318910 HVESFanInstance3 8390;
BA_ "SPN" SG_ 2365318910 HVESFanInstance2 8389;
BA_ "SPN" SG_ 2365318910 HVESFanInstance1 8388;
BA_ "SigType" SG_ 2365318910 HVESFanPercentSpdCmd 1;
BA_ "SPN" SG_ 2365318910 HVESFanPercentSpdCmd 8387;
BA_ "SigType" SG_ 2365318910 HVESFanSpdCmd 1;
BA_ "SPN" SG_ 2365318910 HVESFanSpdCmd 8386;
BA_ "SigType" SG_ 2365318910 HVESFanPwrHold 5;
BA_ "SPN" SG_ 2365318910 HVESFanPwrHold 8385;
BA_ "SigType" SG_ 2365318910 HVESFanEnableCmd 5;
BA_ "SPN" SG_ 2365318910 HVESFanEnableCmd 8384;
BA_ "SPN" SG_ 2566645246 HVESFanInstance 8411;
BA_ "SigType" SG_ 2566645246 HVESFanOperatingStatus 4;
BA_ "SPN" SG_ 2566645246 HVESFanOperatingStatus 8410;
BA_ "SigType" SG_ 2566645246 HVESFanServiceInd 4;
BA_ "SPN" SG_ 2566645246 HVESFanServiceInd 8409;
BA_ "SigType" SG_ 2566645246 HVESFanPwr 1;
BA_ "SPN" SG_ 2566645246 HVESFanPwr 8408;
BA_ "SigType" SG_ 2566645246 HVESFanMediumTemp 1;
BA_ "SPN" SG_ 2566645246 HVESFanMediumTemp 8407;
BA_ "SigType" SG_ 2566645246 HVESFanSpd 1;
BA_ "SPN" SG_ 2566645246 HVESFanSpd 8406;
BA_ "SigType" SG_ 2566645246 HVESFanCmdStatus 4;
BA_ "SPN" SG_ 2566645246 HVESFanCmdStatus 8405;
BA_ "SPN" SG_ 2566645246 HVESFanStatusReasonCode 8404;
BA_ "SigType" SG_ 2566645246 HVESFanEnableStatus 5;
BA_ "SPN" SG_ 2566645246 HVESFanEnableStatus 8403;
BA_ "SigType" SG_ 2566644990 StorageCompartment3Temp2 1;
BA_ "SPN" SG_ 2566644990 StorageCompartment3Temp2 8425;
BA_ "SigType" SG_ 2566644990 StorageCompartment3Temp1 1;
BA_ "SPN" SG_ 2566644990 StorageCompartment3Temp1 8424;
BA_ "SigType" SG_ 2566644990 StorageCompartment2Temp2 1;
BA_ "SPN" SG_ 2566644990 StorageCompartment2Temp2 8423;
BA_ "SigType" SG_ 2566644990 StorageCompartment2Temp1 1;
BA_ "SPN" SG_ 2566644990 StorageCompartment2Temp1 8422;
BA_ "SigType" SG_ 2566644990 StorageCompartment1Temp2 1;
BA_ "SPN" SG_ 2566644990 StorageCompartment1Temp2 8421;
BA_ "SigType" SG_ 2566644990 StorageCompartment1Temp1 1;
BA_ "SPN" SG_ 2566644990 StorageCompartment1Temp1 8420;
BA_ "SigType" SG_ 2566644990 FrontFuelRecpCoverStatus 4;
BA_ "SPN" SG_ 2566644990 FrontFuelRecpCoverStatus 8419;
BA_ "SigType" SG_ 2566644990 PsgrSideFuelRecp2CoverStatus 4;
BA_ "SPN" SG_ 2566644990 PsgrSideFuelRecp2CoverStatus 8418;
BA_ "SigType" SG_ 2566644990 PsgrSideFuelRecp1CoverStatus 4;
BA_ "SPN" SG_ 2566644990 PsgrSideFuelRecp1CoverStatus 8417;
BA_ "SigType" SG_ 2566644990 DriverSideFuelRecp2CoverStatus 4;
BA_ "SPN" SG_ 2566644990 DriverSideFuelRecp2CoverStatus 8416;
BA_ "SigType" SG_ 2566644990 DriverSideFuelRecp1CoverStatus 4;
BA_ "SPN" SG_ 2566644990 DriverSideFuelRecp1CoverStatus 8415;
BA_ "SigType" SG_ 2633753598 ACAirOutTemp 1;
BA_ "SPN" SG_ 2633753598 ACAirOutTemp 8450;
BA_ "SigType" SG_ 2633753598 ACAirInTemp 1;
BA_ "SPN" SG_ 2633753598 ACAirInTemp 8449;
BA_ "SigType" SG_ 2633753598 EngAltWinding12Temp 1;
BA_ "SPN" SG_ 2633753598 EngAltWinding12Temp 8448;
BA_ "SigType" SG_ 2633753598 EngAltWinding11Temp 1;
BA_ "SPN" SG_ 2633753598 EngAltWinding11Temp 8447;
BA_ "SigType" SG_ 2633753598 EngAltWinding10Temp 1;
BA_ "SPN" SG_ 2633753598 EngAltWinding10Temp 8446;
BA_ "SigType" SG_ 2633753598 EngAltWinding9Temp 1;
BA_ "SPN" SG_ 2633753598 EngAltWinding9Temp 8445;
BA_ "SigType" SG_ 2633753598 EngAltWinding8Temp 1;
BA_ "SPN" SG_ 2633753598 EngAltWinding8Temp 8444;
BA_ "SigType" SG_ 2633753598 EngAltWinding7Temp 1;
BA_ "SPN" SG_ 2633753598 EngAltWinding7Temp 8443;
BA_ "SigType" SG_ 2633753342 PwrRectifierDiode8Temp 1;
BA_ "SPN" SG_ 2633753342 PwrRectifierDiode8Temp 8458;
BA_ "SigType" SG_ 2633753342 PwrRectifierDiode7Temp 1;
BA_ "SPN" SG_ 2633753342 PwrRectifierDiode7Temp 8457;
BA_ "SigType" SG_ 2633753342 PwrRectifierDiode6Temp 1;
BA_ "SPN" SG_ 2633753342 PwrRectifierDiode6Temp 8456;
BA_ "SigType" SG_ 2633753342 PwrRectifierDiode5Temp 1;
BA_ "SPN" SG_ 2633753342 PwrRectifierDiode5Temp 8455;
BA_ "SigType" SG_ 2633753342 PwrRectifierDiode4Temp 1;
BA_ "SPN" SG_ 2633753342 PwrRectifierDiode4Temp 8454;
BA_ "SigType" SG_ 2633753342 PwrRectifierDiode3Temp 1;
BA_ "SPN" SG_ 2633753342 PwrRectifierDiode3Temp 8453;
BA_ "SigType" SG_ 2633753342 PwrRectifierDiode2Temp 1;
BA_ "SPN" SG_ 2633753342 PwrRectifierDiode2Temp 8452;
BA_ "SigType" SG_ 2633753342 PwrRectifierDiode1Temp 1;
BA_ "SPN" SG_ 2633753342 PwrRectifierDiode1Temp 8451;
BA_ "SigType" SG_ 2633753086 PwrRectifierDiode12Temp 1;
BA_ "SPN" SG_ 2633753086 PwrRectifierDiode12Temp 8462;
BA_ "SigType" SG_ 2633753086 PwrRectifierDiode11Temp 1;
BA_ "SPN" SG_ 2633753086 PwrRectifierDiode11Temp 8461;
BA_ "SigType" SG_ 2633753086 PwrRectifierDiode10Temp 1;
BA_ "SPN" SG_ 2633753086 PwrRectifierDiode10Temp 8460;
BA_ "SigType" SG_ 2633753086 PwrRectifierDiode9Temp 1;
BA_ "SPN" SG_ 2633753086 PwrRectifierDiode9Temp 8459;
BA_ "SigType" SG_ 2633752830 AltAftercoolerCPOutPress 1;
BA_ "SPN" SG_ 2633752830 AltAftercoolerCPOutPress 8472;
BA_ "SigType" SG_ 2633752830 AltAftercoolerCoolantOutTemp 1;
BA_ "SPN" SG_ 2633752830 AltAftercoolerCoolantOutTemp 8471;
BA_ "SigType" SG_ 2633752830 AltAftercoolerCPOutTemp 1;
BA_ "SPN" SG_ 2633752830 AltAftercoolerCPOutTemp 8470;
BA_ "SigType" SG_ 2633752830 EngOilCoolerCoolantOutTemp 1;
BA_ "SPN" SG_ 2633752830 EngOilCoolerCoolantOutTemp 728;
BA_ "SigType" SG_ 2633752830 AltOilCoolerCoolantOutTemp 1;
BA_ "SPN" SG_ 2633752830 AltOilCoolerCoolantOutTemp 8469;
BA_ "SigType" SG_ 2633752830 AltOilCoolerCoolantInTemp 1;
BA_ "SPN" SG_ 2633752830 AltOilCoolerCoolantInTemp 8468;
BA_ "SigType" SG_ 2633752830 AltOilCoolerOilOutTemp 1;
BA_ "SPN" SG_ 2633752830 AltOilCoolerOilOutTemp 8467;
BA_ "SigType" SG_ 2633752830 AltOilCoolerOilInTemp 1;
BA_ "SPN" SG_ 2633752830 AltOilCoolerOilInTemp 8466;
BA_ "SigType" SG_ 2566643710 DesEngInManifoldPressHiLmt 1;
BA_ "SPN" SG_ 2566643710 DesEngInManifoldPressHiLmt 12307;
BA_ "SigType" SG_ 2566643710 EngInManifold2AbsPress 1;
BA_ "SPN" SG_ 2566643710 EngInManifold2AbsPress 11731;
BA_ "SigType" SG_ 2566643710 EngMixer2InPress 1;
BA_ "SPN" SG_ 2566643710 EngMixer2InPress 8607;
BA_ "SigType" SG_ 2566643710 EngMixer1InPress 1;
BA_ "SPN" SG_ 2566643710 EngMixer1InPress 8477;
BA_ "SigType" SG_ 2566643454 DiffTemp 1;
BA_ "SPN" SG_ 2566643454 DiffTemp 12306;
BA_ "SigType" SG_ 2566643454 InCoolantTemp 1;
BA_ "SPN" SG_ 2566643454 InCoolantTemp 8489;
BA_ "SigType" SG_ 2566643454 ChargeACOutCoolantTemp 1;
BA_ "SPN" SG_ 2566643454 ChargeACOutCoolantTemp 8488;
BA_ "SigType" SG_ 2566643454 ChargeACInCoolantTemp 1;
BA_ "SPN" SG_ 2566643454 ChargeACInCoolantTemp 8487;
BA_ "SigType" SG_ 2566643198 EnableStatusOfDoor20 5;
BA_ "SPN" SG_ 2566643198 EnableStatusOfDoor20 8524;
BA_ "SigType" SG_ 2566643198 OpenStatusOfDoor20 5;
BA_ "SPN" SG_ 2566643198 OpenStatusOfDoor20 8523;
BA_ "SigType" SG_ 2566643198 LockStatusOfDoor20 5;
BA_ "SPN" SG_ 2566643198 LockStatusOfDoor20 8522;
BA_ "SigType" SG_ 2566643198 EnableStatusOfDoor19 5;
BA_ "SPN" SG_ 2566643198 EnableStatusOfDoor19 8521;
BA_ "SigType" SG_ 2566643198 OpenStatusOfDoor19 5;
BA_ "SPN" SG_ 2566643198 OpenStatusOfDoor19 8520;
BA_ "SigType" SG_ 2566643198 LockStatusOfDoor19 5;
BA_ "SPN" SG_ 2566643198 LockStatusOfDoor19 8519;
BA_ "SigType" SG_ 2566643198 EnableStatusOfDoor18 5;
BA_ "SPN" SG_ 2566643198 EnableStatusOfDoor18 8518;
BA_ "SigType" SG_ 2566643198 OpenStatusOfDoor18 5;
BA_ "SPN" SG_ 2566643198 OpenStatusOfDoor18 8517;
BA_ "SigType" SG_ 2566643198 LockStatusOfDoor18 5;
BA_ "SPN" SG_ 2566643198 LockStatusOfDoor18 8516;
BA_ "SigType" SG_ 2566643198 EnableStatusOfDoor17 5;
BA_ "SPN" SG_ 2566643198 EnableStatusOfDoor17 8515;
BA_ "SigType" SG_ 2566643198 OpenStatusOfDoor17 5;
BA_ "SPN" SG_ 2566643198 OpenStatusOfDoor17 8514;
BA_ "SigType" SG_ 2566643198 LockStatusOfDoor17 5;
BA_ "SPN" SG_ 2566643198 LockStatusOfDoor17 8513;
BA_ "SigType" SG_ 2566643198 EnableStatusOfDoor16 5;
BA_ "SPN" SG_ 2566643198 EnableStatusOfDoor16 8512;
BA_ "SigType" SG_ 2566643198 OpenStatusOfDoor16 5;
BA_ "SPN" SG_ 2566643198 OpenStatusOfDoor16 8511;
BA_ "SigType" SG_ 2566643198 LockStatusOfDoor16 5;
BA_ "SPN" SG_ 2566643198 LockStatusOfDoor16 8510;
BA_ "SigType" SG_ 2566643198 EnableStatusOfDoor15 5;
BA_ "SPN" SG_ 2566643198 EnableStatusOfDoor15 8509;
BA_ "SigType" SG_ 2566643198 OpenStatusOfDoor15 5;
BA_ "SPN" SG_ 2566643198 OpenStatusOfDoor15 8508;
BA_ "SigType" SG_ 2566643198 LockStatusOfDoor15 5;
BA_ "SPN" SG_ 2566643198 LockStatusOfDoor15 8507;
BA_ "SigType" SG_ 2566643198 EnableStatusOfDoor14 5;
BA_ "SPN" SG_ 2566643198 EnableStatusOfDoor14 8506;
BA_ "SigType" SG_ 2566643198 OpenStatusOfDoor14 5;
BA_ "SPN" SG_ 2566643198 OpenStatusOfDoor14 8505;
BA_ "SigType" SG_ 2566643198 LockStatusOfDoor14 5;
BA_ "SPN" SG_ 2566643198 LockStatusOfDoor14 8504;
BA_ "SigType" SG_ 2566643198 EnableStatusOfDoor13 5;
BA_ "SPN" SG_ 2566643198 EnableStatusOfDoor13 8503;
BA_ "SigType" SG_ 2566643198 OpenStatusOfDoor13 5;
BA_ "SPN" SG_ 2566643198 OpenStatusOfDoor13 8502;
BA_ "SigType" SG_ 2566643198 LockStatusOfDoor13 5;
BA_ "SPN" SG_ 2566643198 LockStatusOfDoor13 8501;
BA_ "SigType" SG_ 2566643198 EnableStatusOfDoor12 5;
BA_ "SPN" SG_ 2566643198 EnableStatusOfDoor12 8500;
BA_ "SigType" SG_ 2566643198 OpenStatusOfDoor12 5;
BA_ "SPN" SG_ 2566643198 OpenStatusOfDoor12 8499;
BA_ "SigType" SG_ 2566643198 LockStatusOfDoor12 5;
BA_ "SPN" SG_ 2566643198 LockStatusOfDoor12 8498;
BA_ "SigType" SG_ 2566643198 EnableStatusOfDoor11 5;
BA_ "SPN" SG_ 2566643198 EnableStatusOfDoor11 8497;
BA_ "SigType" SG_ 2566643198 OpenStatusOfDoor11 5;
BA_ "SPN" SG_ 2566643198 OpenStatusOfDoor11 8496;
BA_ "SigType" SG_ 2566643198 LockStatusOfDoor11 5;
BA_ "SPN" SG_ 2566643198 LockStatusOfDoor11 8495;
VAL_ 2565917438 PLedDueToUndefinedReason 3 "Not Available" 2 "Error" 1 "Power limited for this reason" 0 "No power limit for this reason" ;
VAL_ 2565917438 PLedDueToRateOfChangeLmt 3 "Not Available" 2 "Error" 1 "Power limited for this reason" 0 "No power limit for this reason" ;
VAL_ 2565917438 PLedDueToPwrETemp 3 "Not Available" 2 "Error" 1 "Power limited for this reason" 0 "No power limit for this reason" ;
VAL_ 2565917438 PLedDueToEFilterTemp 3 "Not Available" 2 "Error" 1 "Power limited for this reason" 0 "No power limit for this reason" ;
VAL_ 2565917438 PLedDueToCtrlTemp 3 "Not Available" 2 "Error" 1 "Power limited for this reason" 0 "No power limit for this reason" ;
VAL_ 2565917438 FreqCmdExceedsMax 3 "Not Available" 2 "Error" 1 "Frequency limited for this reason" 0 "No frequency limit for this reason" ;
VAL_ 2565917438 FreqCmdBelowMin 3 "Not Available" 2 "Error" 1 "Frequency limited for this reason" 0 "No frequency limit for this reason" ;
VAL_ 2565917438 PLedDueToDCSideVMin 3 "Not Available" 2 "Error" 1 "Power limited for this reason" 0 "No power limit for this reason" ;
VAL_ 2565917438 PLedDueToACSideRMSCur 3 "Not Available" 2 "Error" 1 "Power limited for this reason" 0 "No power limit for this reason" ;
VAL_ 2565917438 PLedDueToDCSideCur 3 "Not Available" 2 "Error" 1 "Power limited for this reason" 0 "No power limit for this reason" ;
VAL_ 2624519934 CommandedReceiveSPNSA 255 "The command in SPN 8840 applies to all valid source addresses" 254 "The command in SPN 8840 applies to all source addresses in which the Configurable ECU is currently configured to receive the SP contained in SPN 8839." ;
VAL_ 2624519934 CommandedReceiveSPNReqSt 3 "Not Available" 2 "SAE Reserved" 1 "SP reception shall be enabled for the source address identified in SPN 8841." 0 "SP reception shall be disabled for the source address identified in SPN 8841." ;
VAL_ 2624519934 TransactionMode 15 "SAE Reserved" 14 "SAE Reserved" 13 "SAE Reserved" 12 "SAE Reserved" 11 "SAE Reserved" 10 "SAE Reserved" 9 "SAE Reserved" 8 "SAE Reserved" 7 "SAE Reserved" 6 "SAE Reserved" 5 "SAE Reserved" 4 "Partial Revert to Default" 3 "Global Revert to Default" 2 "Cancel Pending Changes" 1 "Configure Port Receive State" 0 "Request Port Receive Status" ;
VAL_ 2624519934 CommandedPort 15 "SAE Reserved" 14 "SAE Reserved" 13 "SAE Reserved" 12 "SAE Reserved" 11 "SAE Reserved" 10 "Port 10" 9 "Port 9" 8 "Port 8" 7 "Port 7" 6 "Port 6" 5 "Port 5" 4 "Port 4" 3 "Port 3" 2 "Port 2" 1 "Port 1" 0 "Current port" ;
VAL_ 2557345534 PlungerFiringOrder 15 "Don't Care / Take no action" 14 "Reserved" 13 "Reserved" 12 "Reserved" 11 "Reserved" 10 "Reserved" 9 "Reserved" 8 "Reserved" 7 "Reserved" 6 "Reserved" 5 "Reserved" 4 "Reserved" 3 "Reserved" 2 "Reserved" 1 "Firing order 1-5-2-3-4" 0 "Firing order 1-2-3" ;
VAL_ 2557214462 DisPressCalSetPointCmd 15 "Not Available" 14 "Error" 13 "Reserved" 12 "Reset Calibration" 11 "Correction Point" 10 "End Point" 9 "Calibration Reference Point 9" 8 "Calibration Reference Point 8" 7 "Calibration Reference Point 7" 6 "Calibration Reference Point 6" 5 "Calibration Reference Point 5" 4 "Calibration Reference Point 4" 3 "Calibration Reference Point 3" 2 "Calibration Reference Point 2" 1 "Calibration Reference Point 1" 0 "Zero Point" ;
VAL_ 2557214462 SuctionPressCalSetPointCmd 15 "Not Available" 14 "Error" 13 "Reserved" 12 "Reset Calibration" 11 "Correction Point" 10 "End Point" 9 "Calibration Reference Point 9" 8 "Calibration Reference Point 8" 7 "Calibration Reference Point 7" 6 "Calibration Reference Point 6" 5 "Calibration Reference Point 5" 4 "Calibration Reference Point 4" 3 "Calibration Reference Point 3" 2 "Calibration Reference Point 2" 1 "Calibration Reference Point 1" 0 "Zero Point" ;
VAL_ 2557148926 VesselSpdCtrlMode 255 "Not Available" 254 "Error" 3 "Trolling Mode" 2 "Synchronization Mode" 1 "Slow Vessel Mode" 0 "No Set Speed" ;
VAL_ 2557148926 TrollingModeCurSetting 255 "Not Available" 254 "Error" 2 "Advanced Troll Active" 1 "Traditional Troll Active" 0 "No Troll" ;
VAL_ 2557148926 TrollingMode 255 "Not Available" 254 "Error" 2 "Advanced Troll Active" 1 "Traditional Troll Active" 0 "No Troll" ;
VAL_ 2557148926 EngThrotSynchModeCurSetting 15 "Not available" 14 "Error" 13 "Reserved" 12 "Reserved" 11 "Reserved" 10 "Reserved" 9 "Reserved" 8 "Reserved" 7 "Reserved" 6 "Reserved" 5 "Reserved" 4 "Synchronized Master" 3 "Synchronized Starboard" 2 "Synchronized Port" 1 "Synchronized Center" 0 "Not Synchronized" ;
VAL_ 2557148926 OpStationLockout 3 "Not available" 2 "Error" 1 "Station Lockout Active" 0 "Station Lockout Inactive" ;
VAL_ 2557148926 OpStationInCtrlLocation 255 "Not Available" 254 "Error" 7 "Bow Station" 6 "Fly Bridge" 5 "Aft" 4 "Engine Room" 3 "Tower" 2 "Starboard Wing" 1 "Port Wing" 0 "Bridge" ;
VAL_ 2557083390 EngThrotSynchModeCmd 15 "Not available/Take no action" 14 "Error" 13 "Reserved" 12 "Reserved" 11 "Reserved" 10 "Reserved" 9 "Reserved" 8 "Reserved" 7 "Reserved" 6 "Reserved" 5 "Reserved" 4 "Synchronized Master" 3 "Synchronized Starboard" 2 "Synchronized Port" 1 "Synchronized Center" 0 "Not Synchronized" ;
VAL_ 2557083390 TrollingModeSettingCmd 255 "Not Available / Take no action" 254 "Error" 2 "Advanced Troll Active" 1 "Traditional Troll Active" 0 "No Troll" ;
VAL_ 2557083390 OpStationLocationSetting 255 "Not Available / Take no action" 254 "Error" 7 "Bow Station" 6 "Fly Bridge" 5 "Aft" 4 "Engine Room" 3 "Tower" 2 "Starboard Wing" 1 "Port Wing" 0 "Bridge" ;
VAL_ 2633764094 CanisterVentVlv 3 "Not Available" 2 "Error" 1 "Vent Valve is Open" 0 "Vent Valve is Closed" ;
VAL_ 2566654462 SLIBatPack1Snsr1InitStatus 10 "Initialization process is complete." 0 "Initialization process has not started." ;
VAL_ 2566653950 SLIBatPack1Snsr2InitStatus 10 "Initialization process is complete." 0 "Initialization process has not started." ;
VAL_ 2566653438 SLIBatPack1Snsr3InitStatus 10 "Initialization process is complete." 0 "Initialization process has not started." ;
VAL_ 2566652926 SLIBatPack1Snsr4InitStatus 10 "Initialization process is complete." 0 "Initialization process has not started." ;
VAL_ 2566652670 A2DEFDosingSysFrozen 3 "Not available" 2 "Error" 1 "DEF system is frozen" 0 "DEF system is not frozen" ;
VAL_ 2566652670 A1DEFDosingSysFrozen 3 "Not available" 2 "Error" 1 "DEF system is frozen" 0 "DEF system is not frozen" ;
VAL_ 2566652414 Instance 15 "Not available / Instance not specified" 14 "Instance 15" 13 "Instance 14" 12 "Instance 13" 11 "Instance 12" 10 "Instance 11" 9 "Instance 10" 8 "Instance 9" 7 "Instance 8" 6 "Instance 7" 5 "Instance 6" 4 "Instance 5" 3 "Instance 4" 2 "Instance 3" 1 "Instance 2" 0 "Instance 1" ;
VAL_ 2566652414 OperatingStatus 3 "Not Available" 2 "Not Operable" 1 "Derated Operation" 0 "Normal Operation" ;
VAL_ 2566652414 ServiceInd 3 "Not Available" 2 "Reserved" 1 "Service Required" 0 "Service Not Required" ;
VAL_ 2566652414 CtrlCmdStatus 3 "Not Available" 2 "Default Command" 1 "External Command" 0 "Internal Command" ;
VAL_ 2566652414 CtrlStatusReasonCode 15 "Not Available" 14 "Reserved" 13 "Reserved" 12 "Reserved" 11 "Speed limited due to over-voltage protection" 10 "Low Flow Detected" 9 "Exceeding commanded speed due to external force" 8 "Speed limited due to over-temperature protection" 7 "Speed limited due to torque limit" 6 "Speed limited due to maximum system design capability" 5 "Speed Limited due to current" 4 "Over-Temperature Protection Shutdown" 3 "Under-Voltage Protection Shutdown" 2 "Over-Voltage Protection Shutdown" 1 "Unable to Start" 0 "Normal Operation" ;
VAL_ 2566652414 EnableStatus 3 "Not available" 2 "Accessory Motor On, Reverse Direction" 1 "Accessory Motor On, Normal" 0 "Accessory Motor Off" ;
VAL_ 2566651902 OperatingStatus 3 "Not Available" 2 "Not Operable" 1 "Derated Operation" 0 "Normal Operation" ;
VAL_ 2566651902 ServiceInd 3 "Not Available" 2 "Reserved" 1 "Service Required" 0 "Service Not Required" ;
VAL_ 2566651902 CtrlCmdStatus 3 "Not Available" 2 "Default Command" 1 "External Command" 0 "Internal Command" ;
VAL_ 2566651902 CtrlStatusReasonCode 15 "Not Available" 14 "Reserved" 13 "Reserved" 12 "Reserved" 11 "Speed limited due to over-voltage protection" 10 "Low Flow Detected" 9 "Exceeding commanded speed due to external force" 8 "Speed limited due to over-temperature protection" 7 "Speed limited due to torque limit" 6 "Speed limited due to maximum system design capability" 5 "Speed Limited due to current" 4 "Over-Temperature Protection Shutdown" 3 "Under-Voltage Protection Shutdown" 2 "Over-Voltage Protection Shutdown" 1 "Unable to Start" 0 "Normal Operation" ;
VAL_ 2566651902 EnableStatus 3 "Not available" 2 "Accessory Motor On, Reverse Direction" 1 "Accessory Motor On, Normal" 0 "Accessory Motor Off" ;
VAL_ 2566651646 OperatingStatus 3 "Not Available" 2 "Not Operable" 1 "Derated Operation" 0 "Normal Operation" ;
VAL_ 2566651646 ServiceInd 3 "Not Available" 2 "Reserved" 1 "Service Required" 0 "Service Not Required" ;
VAL_ 2566651646 CtrlCmdStatus 3 "Not Available" 2 "Default Command" 1 "External Command" 0 "Internal Command" ;
VAL_ 2566651646 CtrlStatusReasonCode 15 "Not Available" 14 "Reserved" 13 "Reserved" 12 "Reserved" 11 "Speed limited due to over-voltage protection" 10 "Low Flow Detected" 9 "Exceeding commanded speed due to external force" 8 "Speed limited due to over-temperature protection" 7 "Speed limited due to torque limit" 6 "Speed limited due to maximum system design capability" 5 "Speed Limited due to current" 4 "Over-Temperature Protection Shutdown" 3 "Under-Voltage Protection Shutdown" 2 "Over-Voltage Protection Shutdown" 1 "Unable to Start" 0 "Normal Operation" ;
VAL_ 2566651646 EnableStatus 3 "Not available" 2 "Accessory Motor On, Reverse Direction" 1 "Accessory Motor On, Normal" 0 "Accessory Motor Off" ;
VAL_ 2566651390 OperatingStatus 3 "Not Available" 2 "Not Operable" 1 "Derated Operation" 0 "Normal Operation" ;
VAL_ 2566651390 ServiceInd 3 "Not Available" 2 "Reserved" 1 "Service Required" 0 "Service Not Required" ;
VAL_ 2566651390 CtrlCmdStatus 3 "Not Available" 2 "Default Command" 1 "External Command" 0 "Internal Command" ;
VAL_ 2566651390 CtrlStatusReasonCode 15 "Not Available" 14 "Reserved" 13 "Reserved" 12 "Reserved" 11 "Speed limited due to over-voltage protection" 10 "Low Flow Detected" 9 "Exceeding commanded speed due to external force" 8 "Speed limited due to over-temperature protection" 7 "Speed limited due to torque limit" 6 "Speed limited due to maximum system design capability" 5 "Speed Limited due to current" 4 "Over-Temperature Protection Shutdown" 3 "Under-Voltage Protection Shutdown" 2 "Over-Voltage Protection Shutdown" 1 "Unable to Start" 0 "Normal Operation" ;
VAL_ 2566651390 EnableStatus 3 "Not available" 2 "Accessory Motor On, Reverse Direction" 1 "Accessory Motor On, Normal" 0 "Accessory Motor Off" ;
VAL_ 2566651134 OperatingStatus 3 "Not Available" 2 "Not Operable" 1 "Derated Operation" 0 "Normal Operation" ;
VAL_ 2566651134 ServiceInd 3 "Not Available" 2 "Reserved" 1 "Service Required" 0 "Service Not Required" ;
VAL_ 2566651134 CtrlCmdStatus 3 "Not Available" 2 "Default Command" 1 "External Command" 0 "Internal Command" ;
VAL_ 2566651134 CtrlStatusReasonCode 15 "Not Available" 14 "Reserved" 13 "Reserved" 12 "Reserved" 11 "Speed limited due to over-voltage protection" 10 "Low Flow Detected" 9 "Exceeding commanded speed due to external force" 8 "Speed limited due to over-temperature protection" 7 "Speed limited due to torque limit" 6 "Speed limited due to maximum system design capability" 5 "Speed Limited due to current" 4 "Over-Temperature Protection Shutdown" 3 "Under-Voltage Protection Shutdown" 2 "Over-Voltage Protection Shutdown" 1 "Unable to Start" 0 "Normal Operation" ;
VAL_ 2566651134 EnableStatus 3 "Not available" 2 "Accessory Motor On, Reverse Direction" 1 "Accessory Motor On, Normal" 0 "Accessory Motor Off" ;
VAL_ 2566650878 OperatingStatus 3 "Not Available" 2 "Not Operable" 1 "Derated Operation" 0 "Normal Operation" ;
VAL_ 2566650878 ServiceInd 3 "Not Available" 2 "Reserved" 1 "Service Required" 0 "Service Not Required" ;
VAL_ 2566650878 CtrlCmdStatus 3 "Not Available" 2 "Default Command" 1 "External Command" 0 "Internal Command" ;
VAL_ 2566650878 CtrlStatusReasonCode 15 "Not Available" 14 "Reserved" 13 "Reserved" 12 "Reserved" 11 "Speed limited due to over-voltage protection" 10 "Low Flow Detected" 9 "Exceeding commanded speed due to external force" 8 "Speed limited due to over-temperature protection" 7 "Speed limited due to torque limit" 6 "Speed limited due to maximum system design capability" 5 "Speed Limited due to current" 4 "Over-Temperature Protection Shutdown" 3 "Under-Voltage Protection Shutdown" 2 "Over-Voltage Protection Shutdown" 1 "Unable to Start" 0 "Normal Operation" ;
VAL_ 2566650878 EnableStatus 3 "Not available" 2 "Accessory Motor On, Reverse Direction" 1 "Accessory Motor On, Normal" 0 "Accessory Motor Off" ;
VAL_ 2566650622 OperatingStatus 3 "Not Available" 2 "Not Operable" 1 "Derated Operation" 0 "Normal Operation" ;
VAL_ 2566650622 ServiceInd 3 "Not Available" 2 "Reserved" 1 "Service Required" 0 "Service Not Required" ;
VAL_ 2566650622 CtrlCmdStatus 3 "Not Available" 2 "Default Command" 1 "External Command" 0 "Internal Command" ;
VAL_ 2566650622 CtrlStatusReasonCode 15 "Not Available" 14 "Reserved" 13 "Reserved" 12 "Reserved" 11 "Speed limited due to over-voltage protection" 10 "Low Flow Detected" 9 "Exceeding commanded speed due to external force" 8 "Speed limited due to over-temperature protection" 7 "Speed limited due to torque limit" 6 "Speed limited due to maximum system design capability" 5 "Speed Limited due to current" 4 "Over-Temperature Protection Shutdown" 3 "Under-Voltage Protection Shutdown" 2 "Over-Voltage Protection Shutdown" 1 "Unable to Start" 0 "Normal Operation" ;
VAL_ 2566650622 EnableStatus 3 "Not available" 2 "Accessory Motor On, Reverse Direction" 1 "Accessory Motor On, Normal" 0 "Accessory Motor Off" ;
VAL_ 2566650366 OperatingStatus 3 "Not Available" 2 "Not Operable" 1 "Derated Operation" 0 "Normal Operation" ;
VAL_ 2566650366 ServiceInd 3 "Not Available" 2 "Reserved" 1 "Service Required" 0 "Service Not Required" ;
VAL_ 2566650366 CtrlCmdStatus 3 "Not Available" 2 "Default Command" 1 "External Command" 0 "Internal Command" ;
VAL_ 2566650366 CtrlStatusReasonCode 15 "Not Available" 14 "Reserved" 13 "Reserved" 12 "Reserved" 11 "Speed limited due to over-voltage protection" 10 "Low Flow Detected" 9 "Exceeding commanded speed due to external force" 8 "Speed limited due to over-temperature protection" 7 "Speed limited due to torque limit" 6 "Speed limited due to maximum system design capability" 5 "Speed Limited due to current" 4 "Over-Temperature Protection Shutdown" 3 "Under-Voltage Protection Shutdown" 2 "Over-Voltage Protection Shutdown" 1 "Unable to Start" 0 "Normal Operation" ;
VAL_ 2566650366 EnableStatus 3 "Not available" 2 "Accessory Motor On, Reverse Direction" 1 "Accessory Motor On, Normal" 0 "Accessory Motor Off" ;
VAL_ 2566650110 OperatingStatus 3 "Not Available" 2 "Not Operable" 1 "Derated Operation" 0 "Normal Operation" ;
VAL_ 2566650110 ServiceInd 3 "Not Available" 2 "Reserved" 1 "Service Required" 0 "Service Not Required" ;
VAL_ 2566650110 CtrlCmdStatus 3 "Not Available" 2 "Default Command" 1 "External Command" 0 "Internal Command" ;
VAL_ 2566650110 CtrlStatusReasonCode 15 "Not Available" 14 "Reserved" 13 "Reserved" 12 "Reserved" 11 "Speed limited due to over-voltage protection" 10 "Low Flow Detected" 9 "Exceeding commanded speed due to external force" 8 "Speed limited due to over-temperature protection" 7 "Speed limited due to torque limit" 6 "Speed limited due to maximum system design capability" 5 "Speed Limited due to current" 4 "Over-Temperature Protection Shutdown" 3 "Under-Voltage Protection Shutdown" 2 "Over-Voltage Protection Shutdown" 1 "Unable to Start" 0 "Normal Operation" ;
VAL_ 2566650110 EnableStatus 3 "Not available" 2 "Accessory Motor On, Reverse Direction" 1 "Accessory Motor On, Normal" 0 "Accessory Motor Off" ;
VAL_ 2566649854 OperatingStatus 3 "Not Available" 2 "Not Operable" 1 "Derated Operation" 0 "Normal Operation" ;
VAL_ 2566649854 ServiceInd 3 "Not Available" 2 "Reserved" 1 "Service Required" 0 "Service Not Required" ;
VAL_ 2566649854 CtrlCmdStatus 3 "Not Available" 2 "Default Command" 1 "External Command" 0 "Internal Command" ;
VAL_ 2566649854 CtrlStatusReasonCode 15 "Not Available" 14 "Reserved" 13 "Reserved" 12 "Reserved" 11 "Speed limited due to over-voltage protection" 10 "Low Flow Detected" 9 "Exceeding commanded speed due to external force" 8 "Speed limited due to over-temperature protection" 7 "Speed limited due to torque limit" 6 "Speed limited due to maximum system design capability" 5 "Speed Limited due to current" 4 "Over-Temperature Protection Shutdown" 3 "Under-Voltage Protection Shutdown" 2 "Over-Voltage Protection Shutdown" 1 "Unable to Start" 0 "Normal Operation" ;
VAL_ 2566649854 EnableStatus 3 "Not available" 2 "Accessory Motor On, Reverse Direction" 1 "Accessory Motor On, Normal" 0 "Accessory Motor Off" ;
VAL_ 2566648318 MonitorETempStatus 3 "Not available" 2 "Reserved" 1 "Temperature is outside of limits" 0 "Acceptable temperature" ;
VAL_ 2566648318 MonitorSPEStatus 3 "Not available" 2 "Reserved" 1 "Fault in electronics" 0 "Electronics functioning normally" ;
VAL_ 2566648318 MonitorSensingElementStatus 3 "Not available" 2 "Reserved" 1 "Fault with sensing element" 0 "Sensing element OK" ;
VAL_ 2566648318 MonitorEnvironmentStatus 3 "Not available" 2 "Reserved" 1 "Excessive noise in signal" 0 "Acceptable environment" ;
VAL_ 2633755390 LinkStatus 3 "Not Supported" 2 "Error" 1 "Ethernet Link Up" 0 "Ethernet Link Down" ;
VAL_ 2633755390 DHCPStatus 15 "Not Available" 14 "Error" 13 "SAE Reserved" 12 "SAE Reserved" 11 "SAE Reserved" 10 "SAE Reserved" 9 "SAE Reserved" 8 "SAE Reserved" 7 "SAE Reserved" 6 "SAE Reserved" 5 "SAE Reserved" 4 "SAE Reserved" 3 "Contacting DHCP Server" 2 "IP Leased" 1 "Obtaining IP" 0 "Not Configured" ;
VAL_ 2633754878 OneDEFDosingMode 255 "Not available" 253 "Reserved" 252 "Reserved" 251 "Reserved" 0 "Off" ;
VAL_ 2365318910 HVESFanInstance15 1 "No Command applied to this Fan Instance" 0 "Command applied to this Fan Instance" ;
VAL_ 2365318910 HVESFanInstance14 1 "No Command applied to this Fan Instance" 0 "Command applied to this Fan Instance" ;
VAL_ 2365318910 HVESFanInstance13 1 "No Command applied to this Fan Instance" 0 "Command applied to this Fan Instance" ;
VAL_ 2365318910 HVESFanInstance12 1 "No Command applied to this Fan Instance" 0 "Command applied to this Fan Instance" ;
VAL_ 2365318910 HVESFanInstance11 1 "No Command applied to this Fan Instance" 0 "Command applied to this Fan Instance" ;
VAL_ 2365318910 HVESFanInstance10 1 "No Command applied to this Fan Instance" 0 "Command applied to this Fan Instance" ;
VAL_ 2365318910 HVESFanInstance9 1 "No Command applied to this Fan Instance" 0 "Command applied to this Fan Instance" ;
VAL_ 2365318910 HVESFanInstance8 1 "No Command applied to this Fan Instance" 0 "Command applied to this Fan Instance" ;
VAL_ 2365318910 HVESFanInstance7 1 "No Command applied to this Fan Instance" 0 "Command applied to this Fan Instance" ;
VAL_ 2365318910 HVESFanInstance6 1 "No Command applied to this Fan Instance" 0 "Command applied to this Fan Instance" ;
VAL_ 2365318910 HVESFanInstance5 1 "No Command applied to this Fan Instance" 0 "Command applied to this Fan Instance" ;
VAL_ 2365318910 HVESFanInstance4 1 "No Command applied to this Fan Instance" 0 "Command applied to this Fan Instance" ;
VAL_ 2365318910 HVESFanInstance3 1 "No Command applied to this Fan Instance" 0 "Command applied to this Fan Instance" ;
VAL_ 2365318910 HVESFanInstance2 1 "No Command applied to this Fan Instance" 0 "Command applied to this Fan Instance" ;
VAL_ 2365318910 HVESFanInstance1 1 "No Command applied to this Fan Instance" 0 "Command applied to this Fan Instance" ;
VAL_ 2365318910 HVESFanPwrHold 3 "Don't Care/Take no action" 2 "Reserved" 1 "Power Hold Enabled" 0 "Power Hold Disabled" ;
VAL_ 2365318910 HVESFanEnableCmd 3 "Don't Care/Take no action" 2 "Fan On Reverse Direction" 1 "Fan On Normal/Default Direction" 0 "Fan Off" ;
VAL_ 2566645246 HVESFanInstance 15 "Not available / Instance not specified" 14 "Instance 15" 13 "Instance 14" 12 "Instance 13" 11 "Instance 12" 10 "Instance 11" 9 "Instance 10" 8 "Instance 9" 7 "Instance 8" 6 "Instance 7" 5 "Instance 6" 4 "Instance 5" 3 "Instance 4" 2 "Instance 3" 1 "Instance 2" 0 "Instance 1" ;
VAL_ 2566645246 HVESFanOperatingStatus 3 "Not Available" 2 "Not Operable" 1 "Derated Operation" 0 "Normal Operation" ;
VAL_ 2566645246 HVESFanServiceInd 3 "Not Available" 2 "Reserved" 1 "Service Required" 0 "Service Not Required" ;
VAL_ 2566645246 HVESFanCmdStatus 3 "Not Available" 2 "Default Command" 1 "External Command" 0 "Internal Command" ;
VAL_ 2566645246 HVESFanStatusReasonCode 15 "Not Available" 14 "Reserved" 13 "Reserved" 12 "Reserved" 11 "Reserved" 10 "Reserved" 9 "Reserved" 8 "Reserved" 7 "Reserved" 6 "Speed limited due to maximum system design capability" 5 "Speed Limited due to current" 4 "Over-Temperature Protection Shutdown" 3 "Under-Voltage Protection Shutdown" 2 "Over-Voltage Protection Shutdown" 1 "Unable to Start" 0 "Normal Operation" ;
VAL_ 2566645246 HVESFanEnableStatus 3 "Not available" 2 "Fan On, Reverse Direction" 1 "Fan On, Normal" 0 "Fan Off" ;
VAL_ 2566644990 FrontFuelRecpCoverStatus 3 "Not available" 2 "Error" 1 "Receptacle cover is attached" 0 "Receptacle cover is detached" ;
VAL_ 2566644990 PsgrSideFuelRecp2CoverStatus 3 "Not available" 2 "Error" 1 "Receptacle cover is attached" 0 "Receptacle cover is detached" ;
VAL_ 2566644990 PsgrSideFuelRecp1CoverStatus 3 "Not available" 2 "Error" 1 "Receptacle cover is attached" 0 "Receptacle cover is detached" ;
VAL_ 2566644990 DriverSideFuelRecp2CoverStatus 3 "Not available" 2 "Error" 1 "Receptacle cover is attached" 0 "Receptacle cover is detached" ;
VAL_ 2566644990 DriverSideFuelRecp1CoverStatus 3 "Not available" 2 "Error" 1 "Receptacle cover is attached" 0 "Receptacle cover is detached" ;
VAL_ 2566643198 EnableStatusOfDoor20 3 "Not available" 2 "Error" 1 "Door enabled" 0 "Door disabled" ;
VAL_ 2566643198 OpenStatusOfDoor20 3 "Not available" 2 "Error" 1 "Door opened" 0 "Door closed" ;
VAL_ 2566643198 LockStatusOfDoor20 3 "Not available" 2 "Error" 1 "Locked" 0 "Unlocked" ;
VAL_ 2566643198 EnableStatusOfDoor19 3 "Not available" 2 "Error" 1 "Door enabled" 0 "Door disabled" ;
VAL_ 2566643198 OpenStatusOfDoor19 3 "Not available" 2 "Error" 1 "Door opened" 0 "Door closed" ;
VAL_ 2566643198 LockStatusOfDoor19 3 "Not available" 2 "Error" 1 "Locked" 0 "Unlocked" ;
VAL_ 2566643198 EnableStatusOfDoor18 3 "Not available" 2 "Error" 1 "Door enabled" 0 "Door disabled" ;
VAL_ 2566643198 OpenStatusOfDoor18 3 "Not available" 2 "Error" 1 "Door opened" 0 "Door closed" ;
VAL_ 2566643198 LockStatusOfDoor18 3 "Not available" 2 "Error" 1 "Locked" 0 "Unlocked" ;
VAL_ 2566643198 EnableStatusOfDoor17 3 "Not available" 2 "Error" 1 "Door enabled" 0 "Door disabled" ;
VAL_ 2566643198 OpenStatusOfDoor17 3 "Not available" 2 "Error" 1 "Door opened" 0 "Door closed" ;
VAL_ 2566643198 LockStatusOfDoor17 3 "Not available" 2 "Error" 1 "Locked" 0 "Unlocked" ;
VAL_ 2566643198 EnableStatusOfDoor16 3 "Not available" 2 "Error" 1 "Door enabled" 0 "Door disabled" ;
VAL_ 2566643198 OpenStatusOfDoor16 3 "Not available" 2 "Error" 1 "Door opened" 0 "Door closed" ;
VAL_ 2566643198 LockStatusOfDoor16 3 "Not available" 2 "Error" 1 "Locked" 0 "Unlocked" ;
VAL_ 2566643198 EnableStatusOfDoor15 3 "Not available" 2 "Error" 1 "Door enabled" 0 "Door disabled" ;
VAL_ 2566643198 OpenStatusOfDoor15 3 "Not available" 2 "Error" 1 "Door opened" 0 "Door closed" ;
VAL_ 2566643198 LockStatusOfDoor15 3 "Not available" 2 "Error" 1 "Locked" 0 "Unlocked" ;
VAL_ 2566643198 EnableStatusOfDoor14 3 "Not available" 2 "Error" 1 "Door enabled" 0 "Door disabled" ;
VAL_ 2566643198 OpenStatusOfDoor14 3 "Not available" 2 "Error" 1 "Door opened" 0 "Door closed" ;
VAL_ 2566643198 LockStatusOfDoor14 3 "Not available" 2 "Error" 1 "Locked" 0 "Unlocked" ;
VAL_ 2566643198 EnableStatusOfDoor13 3 "Not available" 2 "Error" 1 "Door enabled" 0 "Door disabled" ;
VAL_ 2566643198 OpenStatusOfDoor13 3 "Not available" 2 "Error" 1 "Door opened" 0 "Door closed" ;
VAL_ 2566643198 LockStatusOfDoor13 3 "Not available" 2 "Error" 1 "Locked" 0 "Unlocked" ;
VAL_ 2566643198 EnableStatusOfDoor12 3 "Not available" 2 "Error" 1 "Door enabled" 0 "Door disabled" ;
VAL_ 2566643198 OpenStatusOfDoor12 3 "Not available" 2 "Error" 1 "Door opened" 0 "Door closed" ;
VAL_ 2566643198 LockStatusOfDoor12 3 "Not available" 2 "Error" 1 "Locked" 0 "Unlocked" ;
VAL_ 2566643198 EnableStatusOfDoor11 3 "Not available" 2 "Error" 1 "Door enabled" 0 "Door disabled" ;
VAL_ 2566643198 OpenStatusOfDoor11 3 "Not available" 2 "Error" 1 "Door opened" 0 "Door closed" ;
VAL_ 2566643198 LockStatusOfDoor11 3 "Not available" 2 "Error" 1 "Locked" 0 "Unlocked" ;
